VERSION ""

NS_ :

BS_:

BU_: Skylark_EV

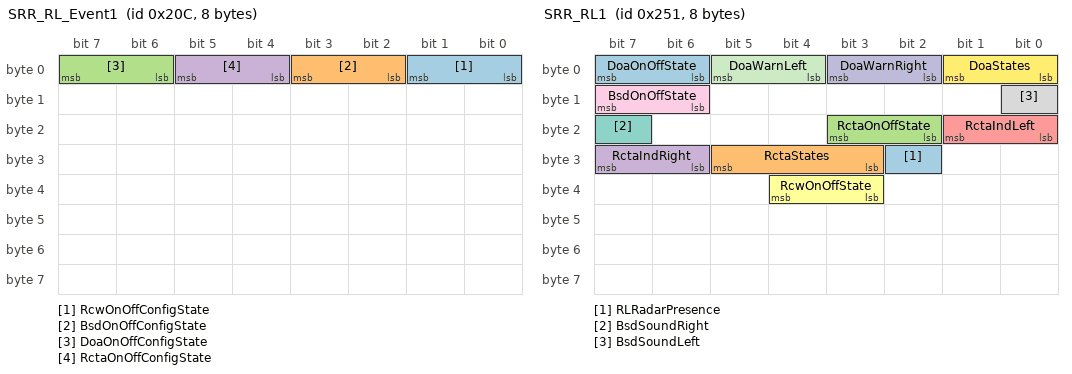
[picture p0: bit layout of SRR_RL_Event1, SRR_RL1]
BO_ 524 SRR_RL_Event1: 8 Vector__XXX
 SG_ RcwOnOffConfigState : 1|2@0+ (1,0) [0|3] ""  Skylark_EV
 SG_ BsdOnOffConfigState : 3|2@0+ (1,0) [0|3] ""  Skylark_EV
 SG_ DoaOnOffConfigState : 7|2@0+ (1,0) [0|3] ""  Skylark_EV
 SG_ RctaOnOffConfigState : 5|2@0+ (1,0) [0|3] ""  Skylark_EV

BO_ 593 SRR_RL1: 8 Vector__XXX
 SG_ RLRadarPresence : 26|1@0+ (1,0) [0|1] ""  Skylark_EV
 SG_ RctaStates : 29|3@0+ (1,0) [0|7] ""  Skylark_EV
 SG_ RctaOnOffState : 19|2@0+ (1,0) [0|3] ""  Skylark_EV
 SG_ RctaIndRight : 31|2@0+ (1,0) [0|3] ""  Skylark_EV
 SG_ RctaIndLeft : 17|2@0+ (1,0) [0|3] ""  Skylark_EV
 SG_ RcwOnOffState : 36|2@0+ (1,0) [0|3] ""  Skylark_EV
 SG_ BsdSoundRight : 23|1@0+ (1,0) [0|1] ""  Skylark_EV
 SG_ BsdSoundLeft : 8|1@0+ (1,0) [0|1] ""  Skylark_EV
 SG_ BsdOnOffState : 15|2@0+ (1,0) [0|3] ""  Skylark_EV
 SG_ DoaWarnRight : 3|2@0+ (1,0) [0|3] ""  Skylark_EV
 SG_ DoaWarnLeft : 5|2@0+ (1,0) [0|3] ""  Skylark_EV
 SG_ DoaStates : 1|2@0+ (1,0) [0|3] ""  Skylark_EV
 SG_ DoaOnOffState : 7|2@0+ (1,0) [0|3] ""  Skylark_EV

BO_ 468 HU_Event2: 8 Skylark_EV
 SG_ HuBcmOrvmTiltReversePos : 56|1@0+ (1,0) [0|1] "" Vector__XXX
 SG_ PotSwRkeOnOffReq : 58|2@0+ (1,0) [0|3] "" Vector__XXX
 SG_ PotHeightAdjReq : 61|3@0+ (1,0) [0|7] "" Vector__XXX
 SG_ PotGestOnOffReq : 63|2@0+ (1,0) [0|3] "" Vector__XXX
 SG_ PotBuzzOnOffReq : 49|2@0+ (1,0) [0|3] "" Vector__XXX
 SG_ RcwReqType : 51|2@0+ (1,0) [0|3] "" Vector__XXX
 SG_ RcwOnOffStateReq : 53|2@0+ (1,0) [0|3] "" Vector__XXX
 SG_ RcwOnOffStateAck : 55|2@0+ (1,0) [0|3] "" Vector__XXX
 SG_ RctaReqType : 41|2@0+ (1,0) [0|3] "" Vector__XXX
 SG_ RctaOnOffStateReq : 43|2@0+ (1,0) [0|3] "" Vector__XXX
 SG_ RctaOnOffStateAck : 45|2@0+ (1,0) [0|3] "" Vector__XXX
 SG_ DoaReqType : 47|2@0+ (1,0) [0|3] "" Vector__XXX
 SG_ DoaOnOffStateReq : 33|2@0+ (1,0) [0|3] "" Vector__XXX
 SG_ DoaOnOffStateAck : 35|2@0+ (1,0) [0|3] "" Vector__XXX
 SG_ BsdReqType : 37|2@0+ (1,0) [0|3] "" Vector__XXX
 SG_ BsdOnOffStateReq : 39|2@0+ (1,0) [0|3] "" Vector__XXX
 SG_ BsdOnOffStateAck : 25|2@0+ (1,0) [0|3] "" Vector__XXX
 SG_ FcwAebWarnSetStateReq : 21|3@0+ (1,0) [0|7] "" Vector__XXX
 SG_ FcwAebWarnSetStateAck : 18|3@0+ (1,0) [0|7] "" Vector__XXX
 SG_ FcwAebReqType : 31|2@0+ (1,0) [0|3] "" Vector__XXX
 SG_ FcwAebOnOffStateReq : 23|2@0+ (1,0) [0|3] "" Vector__XXX
 SG_ FcwAebOnOffStateAck : 29|2@0+ (1,0) [0|3] "" Vector__XXX
 SG_ TsrReqType : 13|2@0+ (1,0) [0|3] "" Vector__XXX
 SG_ TsrOnOffStateReq : 9|2@0+ (1,0) [0|3] "" Vector__XXX
 SG_ TsrOnOffStateAck : 11|2@0+ (1,0) [0|3] "" Vector__XXX
 SG_ LdwOnOffStateReq : 15|2@0+ (1,0) [0|3] "" Vector__XXX
 SG_ LdwReqType : 27|2@0+ (1,0) [0|3] "" Vector__XXX
 SG_ LdwOnOffStateAck : 7|2@0+ (1,0) [0|3] "" Vector__XXX
 SG_ HbaOnOffStateReq : 5|2@0+ (1,0) [0|3] "" Vector__XXX
 SG_ HbaReqType : 3|2@0+ (1,0) [0|3] "" Vector__XXX
 SG_ HbaOnOffStateAck : 1|2@0+ (1,0) [0|3] "" Vector__XXX

BO_ 471 FCM_Event1: 8 Vector__XXX
 SG_ LdwWarningSettingConfigState : 46|2@0+ (1,0) [0|3] ""  Skylark_EV
 SG_ LdwHapticWarningConfigState : 33|3@0+ (1,0) [0|7] ""  Skylark_EV
 SG_ LcsSignalApplicability : 24|1@0+ (1,0) [0|1] ""  Skylark_EV
 SG_ LcsOnOffConfigState : 17|2@0+ (1,0) [0|3] ""  Skylark_EV
 SG_ AsaSignalApplicability : 31|1@0+ (1,0) [0|1] ""  Skylark_EV
 SG_ AsaOnOffConfigState : 35|2@0+ (1,0) [0|3] ""  Skylark_EV
 SG_ OvrSpdLmtThrshldConfigState : 28|2@0+ (1,0) [0|3] "kmph"  Skylark_EV
 SG_ OvrSpdLmtWarnConfigState : 30|2@0+ (1,0) [0|3] ""  Skylark_EV
 SG_ IsaOnOffConfigState : 37|2@0+ (1,0) [0|3] ""  Skylark_EV
 SG_ TsrSignalApplicability : 23|1@0+ (1,0) [0|1] ""  Skylark_EV
 SG_ FcwAebSignalApplicability : 15|1@0+ (1,0) [0|1] ""  Skylark_EV
 SG_ LdwSignalApplicability : 14|1@0+ (1,0) [0|1] ""  Skylark_EV
 SG_ HbaSignalApplicability : 13|1@0+ (1,0) [0|1] ""  Skylark_EV
 SG_ FcwAebOnOffConfigStateValidity : 12|1@0+ (1,0) [0|1] ""  Skylark_EV
 SG_ FcwAebWarnSetConfigStateValidity : 11|1@0+ (1,0) [0|1] ""  Skylark_EV
 SG_ FcwAebWarnSetConfigState : 10|3@0+ (1,0) [0|7] ""  Skylark_EV
 SG_ TsrOnOffConfigState : 7|2@0+ (1,0) [0|3] ""  Skylark_EV
 SG_ LdwOnOffConfigState : 5|2@0+ (1,0) [0|3] ""  Skylark_EV
 SG_ HbaOnOffConfigState : 3|2@0+ (1,0) [0|3] ""  Skylark_EV
 SG_ FcwAebOnOffConfigState : 1|2@0+ (1,0) [0|3] ""  Skylark_EV

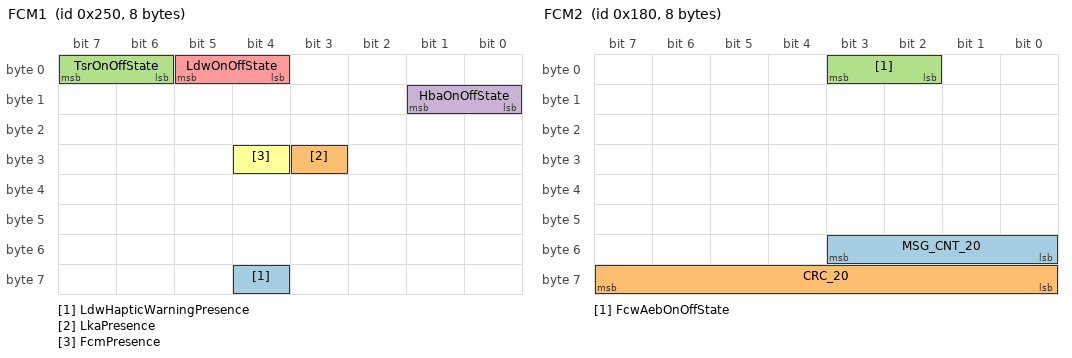
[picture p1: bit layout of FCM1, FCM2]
BO_ 592 FCM1: 8 Vector__XXX
 SG_ LdwHapticWarningPresence : 60|1@0+ (1,0) [0|1] ""  Skylark_EV
 SG_ LkaPresence : 27|1@0+ (1,0) [0|1] ""  Skylark_EV
 SG_ TsrOnOffState : 7|2@0+ (1,0) [0|3] ""  Skylark_EV
 SG_ HbaOnOffState : 9|2@0+ (1,0) [0|3] ""  Skylark_EV
 SG_ LdwOnOffState : 5|2@0+ (1,0) [0|3] ""  Skylark_EV
 SG_ FcmPresence : 28|1@0+ (1,0) [0|1] ""  Skylark_EV

BO_ 384 FCM2: 8 Vector__XXX
 SG_ MSG_CNT_20 : 51|4@0+ (1,0) [0|15] ""  Skylark_EV
 SG_ CRC_20 : 63|8@0+ (1,0) [0|255] ""  Skylark_EV
 SG_ FcwAebOnOffState : 3|2@0+ (1,0) [0|3] ""  Skylark_EV

BO_ 473 HU_Event3: 8 Skylark_EV
 SG_ LdwWarningSettingReq : 27|2@0+ (1,0) [0|3] "" Vector__XXX
 SG_ LdwWarningSettingConfigAck : 25|2@0+ (1,0) [0|3] "" Vector__XXX
 SG_ LdwHapticWarningStateReq : 18|3@0+ (1,0) [0|7] "" Vector__XXX
 SG_ LdwHapticWarningConfigAck : 21|3@0+ (1,0) [0|7] "" Vector__XXX
 SG_ LcsOnOffStateReq : 11|2@0+ (1,0) [0|3] "" Vector__XXX
 SG_ LcsOnOffStateAck : 23|2@0+ (1,0) [0|3] "" Vector__XXX
 SG_ LcsReqType : 9|2@0+ (1,0) [0|3] "" Vector__XXX
 SG_ HuPepsMrrProximityUnfoldSelReq : 13|2@0+ (1,0) [0|3] "" Vector__XXX
 SG_ HuVCuReqType : 15|2@0+ (1,0) [0|3] "" Vector__XXX
 SG_ HuVCuChargeLimitValue : 62|7@0+ (1,0) [0|100] "" Vector__XXX
 SG_ HuCplSclTimerSettingUpdate : 49|2@0+ (1,0) [0|3] "" Vector__XXX
 SG_ HuCplSclOnOffSettingUpdate : 63|1@0+ (1,0) [0|1] "" Vector__XXX
 SG_ HuCplReqType : 51|2@0+ (1,0) [0|3] "" Vector__XXX
 SG_ AsaOnOffStateReq : 33|2@0+ (1,0) [0|3] "" Vector__XXX
 SG_ AsaOnOffStateAck : 35|2@0+ (1,0) [0|3] "" Vector__XXX
 SG_ AsaReqType : 37|2@0+ (1,0) [0|3] "" Vector__XXX
 SG_ OvrSpdLmtThrshldStateReq : 41|2@0+ (1,0) [0|3] "kmph" Vector__XXX
 SG_ OvrSpdLmtThrshldStateAck : 47|2@0+ (1,0) [0|3] "kmph" Vector__XXX
 SG_ OvrSpdLmtWarnStateReq : 43|2@0+ (1,0) [0|3] "" Vector__XXX
 SG_ OvrSpdLmtWarnStateAck : 45|2@0+ (1,0) [0|3] "" Vector__XXX
 SG_ IsaOnOffStateReq : 55|2@0+ (1,0) [0|3] "" Vector__XXX
 SG_ IsaOnOffStateAck : 53|2@0+ (1,0) [0|3] "" Vector__XXX
 SG_ HuBCmMrrAutoUnfoldSelReq : 39|2@0+ (1,0) [0|3] "" Vector__XXX
 SG_ IviSwcEvent : 3|4@0+ (1,0) [0|15] "" Vector__XXX

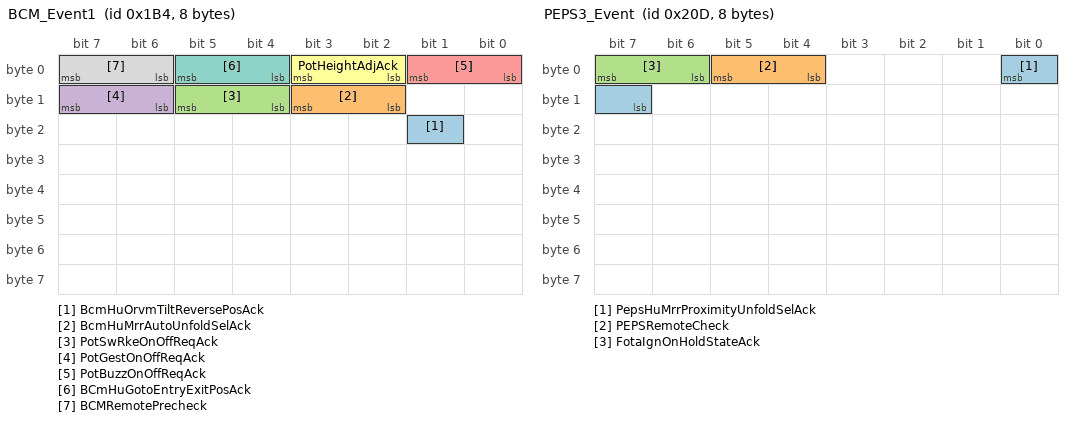
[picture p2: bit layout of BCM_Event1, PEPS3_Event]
BO_ 436 BCM_Event1: 8 Vector__XXX
 SG_ BcmHuOrvmTiltReversePosAck : 17|1@0+ (1,0) [0|1] ""  Skylark_EV
 SG_ BcmHuMrrAutoUnfoldSelAck : 11|2@0+ (1,0) [0|3] ""  Skylark_EV
 SG_ PotSwRkeOnOffReqAck : 13|2@0+ (1,0) [0|3] ""  Skylark_EV
 SG_ PotGestOnOffReqAck : 15|2@0+ (1,0) [0|3] ""  Skylark_EV
 SG_ PotBuzzOnOffReqAck : 1|2@0+ (1,0) [0|3] ""  Skylark_EV
 SG_ PotHeightAdjAck : 3|2@0+ (1,0) [0|3] ""  Skylark_EV
 SG_ BCmHuGotoEntryExitPosAck : 5|2@0+ (1,0) [0|3] ""  Skylark_EV
 SG_ BCMRemotePrecheck : 7|2@0+ (1,0) [0|3] ""  Skylark_EV

BO_ 525 PEPS3_Event: 8 Vector__XXX
 SG_ PepsHuMrrProximityUnfoldSelAck : 0|2@0+ (1,0) [0|3] ""  Skylark_EV
 SG_ PEPSRemoteCheck : 5|2@0+ (1,0) [0|3] ""  Skylark_EV
 SG_ FotaIgnOnHoldStateAck : 7|2@0+ (1,0) [0|3] ""  Skylark_EV

BO_ 496 TelematicsEventMsg1: 8 Skylark_EV
 SG_ FotaIgnOnHoldState : 19|2@0+ (1,0) [0|3] "" Vector__XXX

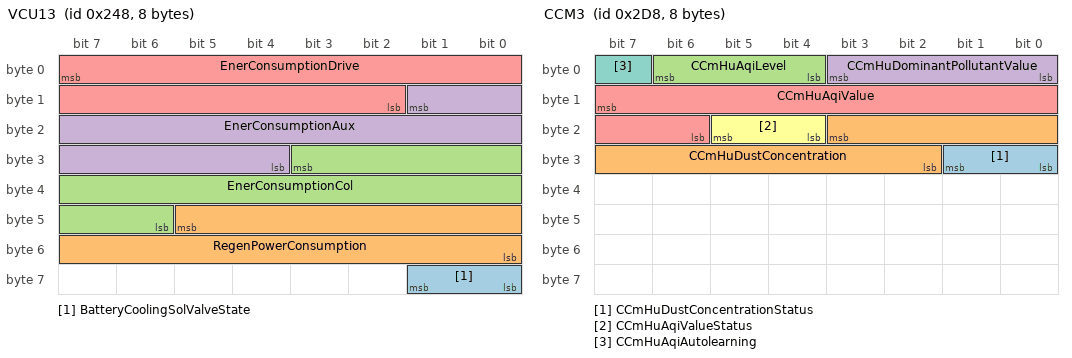
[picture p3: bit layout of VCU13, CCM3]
BO_ 584 VCU13: 8 Vector__XXX
 SG_ BatteryCoolingSolValveState : 57|2@0+ (1,0) [0|3] ""  Skylark_EV
 SG_ RegenPowerConsumption : 45|14@0+ (0.01,0) [0|150] ""  Skylark_EV
 SG_ EnerConsumptionCol : 27|14@0+ (0.01,0) [0|150] ""  Skylark_EV
 SG_ EnerConsumptionAux : 9|14@0+ (0.01,0) [0|150] ""  Skylark_EV
 SG_ EnerConsumptionDrive : 7|14@0+ (0.01,0) [0|150] ""  Skylark_EV

BO_ 728 CCM3: 8 Vector__XXX
 SG_ CCmHuDustConcentrationStatus : 25|2@0+ (1,0) [0|3] ""  Skylark_EV
 SG_ CCmHuDustConcentration : 19|10@0+ (1,0) [0|1023] ""  Skylark_EV
 SG_ CCmHuAqiLevel : 6|3@0+ (1,0) [0|7] ""  Skylark_EV
 SG_ CCmHuDominantPollutantValue : 3|4@0+ (1,0) [0|15] ""  Skylark_EV
 SG_ CCmHuAqiValue : 15|10@0+ (1,0) [0|1023] ""  Skylark_EV
 SG_ CCmHuAqiValueStatus : 21|2@0+ (1,0) [0|3] ""  Skylark_EV
 SG_ CCmHuAqiAutolearning : 7|1@0+ (1,0) [0|1] ""  Skylark_EV

BO_ 736 Remote_Feature1: 8 Vector__XXX
 SG_ VehicleMobilizationStateStatus : 7|2@0+ (1,0) [0|3] ""  Skylark_EV
 SG_ VehicleMobilizationState : 5|2@0+ (1,0) [0|3] ""  Skylark_EV

BO_ 467 HU_Event1: 8 Skylark_EV
 SG_ HuBCmGotoEntryExitPos : 7|2@0+ (1,0) [0|3] "" Vector__XXX

BO_ 583 VCU10_RC: 8 Vector__XXX
 SG_ HvBattDischargingStatus_VCAN : 51|2@0+ (1,0) [0|3] ""  Skylark_EV
 SG_ HvBattDischargingState_VCAN : 23|3@0+ (1,0) [0|7] ""  Skylark_EV
 SG_ HvBattDischargelimitstatus_VCAN : 9|2@0+ (1,0) [0|3] ""  Skylark_EV
 SG_ HvBattDischargelimit_VCAN : 11|2@0+ (1,0) [0|3] ""  Skylark_EV
 SG_ HvBattFullChargeStatus_new_VCAN : 13|2@0+ (1,0) [0|3] ""  Skylark_EV
 SG_ HvBattFullCharge_new_VCAN : 15|2@0+ (1,0) [0|3] ""  Skylark_EV
 SG_ CruiseSwitchStateVCUStatus : 1|2@0+ (1,0) [0|3] ""  Skylark_EV
 SG_ CruiseSwitchStateVCU : 3|2@0+ (1,0) [0|3] ""  Skylark_EV
 SG_ VcuModeSelectionChangeTxt : 53|2@0+ (1,0) [0|3] ""  Skylark_EV
 SG_ ModeForDisplayVCUStatus : 47|2@0+ (1,0) [0|3] ""  Skylark_EV
 SG_ ModeForDisplayVCU : 37|3@0+ (1,0) [0|7] ""  Skylark_EV
 SG_ ModeSelectionSwStateVCUStatus : 16|3@0+ (1,0) [0|7] ""  Skylark_EV
 SG_ ModeSelectionSwStateVCU : 29|3@0+ (1,0) [0|7] ""  Skylark_EV
 SG_ VcuRegenSelectionChangeTxt : 55|2@0+ (1,0) [0|3] ""  Skylark_EV
 SG_ RegenForDisplayVCUStatus : 45|2@0+ (1,0) [0|3] ""  Skylark_EV
 SG_ RegenForDisplayVCU : 34|3@0+ (1,0) [0|7] ""  Skylark_EV
 SG_ VcuCruiseSelectionChangeTxt : 43|4@0+ (1,0) [0|15] ""  Skylark_EV
 SG_ DesiredCruiseSpeedStatus : 49|2@0+ (1,0) [0|3] ""  Skylark_EV
 SG_ DesiredCruiseSpeed : 63|8@0+ (1,0) [0|255] ""  Skylark_EV
 SG_ VCuCruiseStateStatus : 39|2@0+ (1,0) [0|3] ""  Skylark_EV
 SG_ VCuCruiseState : 26|3@0+ (1,0) [0|7] ""  Skylark_EV
 SG_ HvBattFullChargeStatus_VCAN : 7|2@0+ (1,0) [0|3] ""  Skylark_EV
 SG_ HvBattFullCharge_VCAN : 5|1@0+ (1,0) [0|1] ""  Skylark_EV

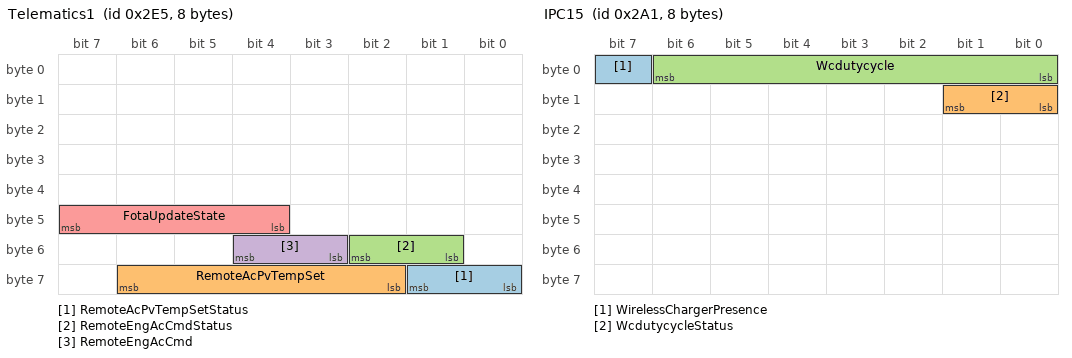
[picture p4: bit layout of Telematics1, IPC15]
BO_ 741 Telematics1: 8 Skylark_EV
 SG_ RemoteAcPvTempSetStatus : 57|2@0+ (1,0) [0|3] "" Vector__XXX
 SG_ RemoteAcPvTempSet : 62|5@0+ (1,0) [0|31] "" Vector__XXX
 SG_ RemoteEngAcCmdStatus : 50|2@0+ (1,0) [0|3] "" Vector__XXX
 SG_ RemoteEngAcCmd : 52|2@0+ (1,0) [0|3] "" Vector__XXX
 SG_ FotaUpdateState : 47|4@0+ (1,0) [0|15] "" Vector__XXX

BO_ 673 IPC15: 8 Vector__XXX
 SG_ WirelessChargerPresence : 7|1@0+ (1,0) [0|1] ""  Skylark_EV
 SG_ WcdutycycleStatus : 9|2@0+ (1,0) [0|3] ""  Skylark_EV
 SG_ Wcdutycycle : 6|7@0+ (1,0) [0|100] "%"  Skylark_EV

BO_ 491 HU_VrCmd_SupportAck: 8 Skylark_EV
 SG_ HuBCmWindowWindingHmiCmdSupportA : 23|1@0+ (1,0) [0|1] "" Vector__XXX
 SG_ HuBCmTyreTempVrCmdSupportAck : 8|1@0+ (1,0) [0|1] "" Vector__XXX
 SG_ HuBCmTyreTempHmiCmdSupportAck : 9|1@0+ (1,0) [0|1] "" Vector__XXX
 SG_ HuBCmTyrePressureVrCmdSupportAck : 10|1@0+ (1,0) [0|1] "" Vector__XXX
 SG_ HuBCmTyrePressureHmiCmdSupportAc : 11|1@0+ (1,0) [0|1] "" Vector__XXX
 SG_ HuBCmSunroofTiltVrCmdSupportAck : 12|1@0+ (1,0) [0|1] "" Vector__XXX
 SG_ HuBCmRoofLampVrCmdSupportAck : 13|1@0+ (1,0) [0|1] "" Vector__XXX
 SG_ HuBCmRoofLampHmiCmdSupportAck : 14|1@0+ (1,0) [0|1] "" Vector__XXX
 SG_ HuBCmPositionLampVrCmdSupportAck : 15|1@0+ (1,0) [0|1] "" Vector__XXX
 SG_ HuBCmORVMVrCmdSupportAck : 2|1@0+ (1,0) [0|1] "" Vector__XXX
 SG_ HuBCmORVMHmiCmdSupportAck : 3|1@0+ (1,0) [0|1] "" Vector__XXX
 SG_ HuBCmMoodLightVrCmdSupportAck : 4|1@0+ (1,0) [0|1] "" Vector__XXX
 SG_ HuBCmHazardLampVrCmdSupportAck : 5|1@0+ (1,0) [0|1] "" Vector__XXX
 SG_ HuBCmDRLVrCmdSupportAck : 6|1@0+ (1,0) [0|1] "" Vector__XXX
 SG_ HuBCmAmbientLightVrCmdSupportAck : 7|1@0+ (1,0) [0|1] "" Vector__XXX
 SG_ HuBCmSunShadeVrCmdSupportAck : 1|1@0+ (1,0) [0|1] "" Vector__XXX
 SG_ HuBCmSunRoofVrCmdSupportAck : 0|1@0+ (1,0) [0|1] "" Vector__XXX

CM_ SG_ 524 RcwOnOffConfigState "It indicates the RCW  feature's On/Off State";
CM_ SG_ 524 BsdOnOffConfigState "It indicates the BSD feature's On/Off State";
CM_ SG_ 524 DoaOnOffConfigState "It indicates the DOA feature's On/Off State";
CM_ SG_ 524 RctaOnOffConfigState "It indicates the RCTA feature's On/Off State";
CM_ SG_ 593 RLRadarPresence "This signal indicates the presence of Rear Radar Module";
CM_ SG_ 593 RctaStates "This signal indicates the states of RCTA";
CM_ SG_ 593 RctaOnOffState "This signal indicates the presence of RCTA feature";
CM_ SG_ 593 RctaIndRight "This signal Indicates RCTA Warning Indicator mode for Right side.";
CM_ SG_ 593 RctaIndLeft "This signal Indicates RCTA Warning Indicator mode for Left side.";
CM_ SG_ 593 RcwOnOffState "This signal indicates the presence of RCW feature";
CM_ SG_ 593 BsdSoundRight "BSD-LCA Sound warning Right speaker";
CM_ SG_ 593 BsdSoundLeft "BSD-LCA Sound warning Left speaker";
CM_ SG_ 593 BsdOnOffState "This signal indicates the presence of BSD feature";
CM_ SG_ 593 DoaWarnRight "DOA Left indicator warning";
CM_ SG_ 593 DoaWarnLeft "DOA Left indicator warning";
CM_ SG_ 593 DoaStates "This signal indicates the states of DOA";
CM_ SG_ 593 DoaOnOffState "This signal indicates the presence of DOA feature";
CM_ SG_ 468 HuBcmOrvmTiltReversePos "ORVM Tilt in reverse Function User request to Enable or Disable Feature";
CM_ SG_ 468 PotSwRkeOnOffReq "POT open/close by RKE switch enable/ disable user req";
CM_ SG_ 468 PotHeightAdjReq "POT height selection by user through HU";
CM_ SG_ 468 PotGestOnOffReq "POT open/close by gesture enable/ disable user req";
CM_ SG_ 468 PotBuzzOnOffReq "POT buzzer of open/close action enable/ disable user req";
CM_ SG_ 468 RcwReqType "This signal indicates the request for an action that IVI wants RearRadar to perform for RCW feature";
CM_ SG_ 468 RcwOnOffStateReq "It indicates the request made by the user for feature enable/disable";
CM_ SG_ 468 RcwOnOffStateAck "It indicates the acknowledgment status from IVI";
CM_ SG_ 468 RctaReqType "This signal indicates the request for an action that IVI wants RLRadar to perform for RCTA feature";
CM_ SG_ 468 RctaOnOffStateReq "It indicates the request made by the user for feature enable/disable";
CM_ SG_ 468 RctaOnOffStateAck "It indicates the acknowledgment status from IVI";
CM_ SG_ 468 DoaReqType "This signal indicates the request for an action that IVI wants RLRadar to perform for DOA feature";
CM_ SG_ 468 DoaOnOffStateReq "It indicates the request made by the user for feature enable/disable";
CM_ SG_ 468 DoaOnOffStateAck "It indicates the acknowledgment status from IVI";
CM_ SG_ 468 BsdReqType "This signal indicates the request for an action that IVI wants RearRadar to perform for BSD feature";
CM_ SG_ 468 BsdOnOffStateReq "It indicates the request made by the user for feature enable/disable";
CM_ SG_ 468 BsdOnOffStateAck "It indicates the acknowledgment status from IVI";
CM_ SG_ 468 FcwAebWarnSetStateReq "It indicates the request made by the user for feature sensitivity

";
CM_ SG_ 468 FcwAebWarnSetStateAck "It indicates the acknowledgment status from IVI for feature sensitivity
";
CM_ SG_ 468 FcwAebReqType "This signal indicates the request for an action that IVI wants FCM to perform for FCW AEB feature

";
CM_ SG_ 468 FcwAebOnOffStateReq "It indicates the request made by the user for feature enable/disable

";
CM_ SG_ 468 FcwAebOnOffStateAck "It indicates the acknowledgment status from IVI for feature ON/OFF
";
CM_ SG_ 468 TsrReqType "This signal indicates the request for an action that IVI wants FCM to perform for TSR feature

";
CM_ SG_ 468 TsrOnOffStateReq "It indicates the request made by the user for feature enable/disable

";
CM_ SG_ 468 TsrOnOffStateAck "It indicates the acknowledgment status from IVI

";
CM_ SG_ 468 LdwOnOffStateReq "It indicates the request made by the user for feature enable/disable

";
CM_ SG_ 468 LdwReqType "This signal indicates the request for an action that IVI wants FCM to perform for LDW feature
";
CM_ SG_ 468 LdwOnOffStateAck "It indicates the acknowledgment status from IVI
";
CM_ SG_ 468 HbaOnOffStateReq "It indicates the request made by the user for feature enable/disable
";
CM_ SG_ 468 HbaReqType "This signal indicates the request for an action that IVI wants FCM to perform for HBA feature";
CM_ SG_ 468 HbaOnOffStateAck "It indicates the acknowledgment status from IVI
";
CM_ SG_ 471 LdwWarningSettingConfigState "This signal  indicates the LDW warning setting





";
CM_ SG_ 471 LdwHapticWarningConfigState "This signal  indicates the LDW Haptic warning setting






";
CM_ SG_ 471 LcsSignalApplicability "This signal describes the applicability of LCS Event signals



";
CM_ SG_ 471 LcsOnOffConfigState "It indicates the LCS feature's On/Off State





";
CM_ SG_ 471 AsaSignalApplicability "It indicates the request made by the user for feature enable/disable





";
CM_ SG_ 471 OvrSpdLmtThrshldConfigState "It indicates the Overspeed limit threshold speed value





";
CM_ SG_ 471 OvrSpdLmtWarnConfigState "It indicates the Overspeed limit alert feature ON/OFF state.";
CM_ SG_ 471 IsaOnOffConfigState "It indicates the ISA feature's ON/OFF state





";
CM_ SG_ 471 TsrSignalApplicability "This signal describes the applicability of TSR Event signals";
CM_ SG_ 471 FcwAebSignalApplicability "This signal describes the applicability of FCW-AEB Event signals";
CM_ SG_ 471 LdwSignalApplicability "This signal describes the applicability of LDW Event signals";
CM_ SG_ 471 HbaSignalApplicability "This signal describes the applicability of HBA Event signals";
CM_ SG_ 471 FcwAebOnOffConfigStateValidity "It indicates the status of AEB feature's On/Off State signal";
CM_ SG_ 471 FcwAebWarnSetConfigStateValidity "It indicates the status of the sensitivity settings signal";
CM_ SG_ 471 FcwAebWarnSetConfigState "It indicates the sensitivity settings selected by the user";
CM_ SG_ 471 TsrOnOffConfigState "It indicates the TSR feature's On/Off State";
CM_ SG_ 471 LdwOnOffConfigState "It indicates the LDW feature's On/Off State";
CM_ SG_ 471 HbaOnOffConfigState "It indicates the HBA feature's On/Off State";
CM_ SG_ 471 FcwAebOnOffConfigState "It indicates the AEB feature's On/Off State";
CM_ SG_ 592 LdwHapticWarningPresence "This signal indicates the presence of Haptic warning setting menu



";
CM_ SG_ 592 LkaPresence "This signal indicates the presence of Lane Keep Assist Feature";
CM_ SG_ 592 TsrOnOffState "It indicates the TSR feature's On/Off State";
CM_ SG_ 592 HbaOnOffState "It indicates the HBA feature's On/Off State";
CM_ SG_ 592 LdwOnOffState "It indicates the LDW feature's On/Off State";
CM_ SG_ 592 FcmPresence "This signal indicates the presence of Front Camera Module";
CM_ SG_ 384 MSG_CNT_20 "Message counter for AEB feature";
CM_ SG_ 384 CRC_20 "CRC signal for AEB feature";
CM_ SG_ 384 FcwAebOnOffState "It indicates the AEB feature's On/Off State";
CM_ SG_ 473 LdwWarningSettingReq "It indicates the request made by the user for LDW warning setting change





";
CM_ SG_ 473 LdwWarningSettingConfigAck "It indicates the acknowledgment status from IVI for LDW warning setting





";
CM_ SG_ 473 LdwHapticWarningStateReq "It indicates the request made by the user for LDW Haptic warning setting change






";
CM_ SG_ 473 LdwHapticWarningConfigAck "It indicates the acknowledgment status from IVI for LDW Haptic warning setting






";
CM_ SG_ 473 LcsOnOffStateReq "It indicates the request made by the user for feature enable/disable





";
CM_ SG_ 473 LcsOnOffStateAck "It indicates the acknowledgment status from IVI





";
CM_ SG_ 473 LcsReqType "This signal indicates the request for an action that IVI wants FCM to perform for LCS feature





";
CM_ SG_ 473 HuPepsMrrProximityUnfoldSelReq "ORVM Proximity Fold / Unfold function enable/ disable user req HU to Peps";
CM_ SG_ 473 HuVCuChargeLimitValue "HuVCuChargeLimitValue";
CM_ SG_ 473 HuCplSclTimerSettingUpdate "This signal indicates timer setting update information for SCL feature.";
CM_ SG_ 473 HuCplSclOnOffSettingUpdate "This signal indicates On/Off setting update information for SCL feature.";
CM_ SG_ 473 HuCplReqType "This signal indicates the intent of event signal send by HU.";
CM_ SG_ 473 AsaOnOffStateReq "It indicates the request made by the user for feature enable/disable





";
CM_ SG_ 473 AsaOnOffStateAck "It indicates the acknowledgment status from IVI





";
CM_ SG_ 473 AsaReqType "This signal indicates the request for an action that IVI wants FCM to perform for ASA feature";
CM_ SG_ 473 OvrSpdLmtThrshldStateReq "It indicates the request made by the user





";
CM_ SG_ 473 OvrSpdLmtThrshldStateAck "It indicates the acknowledgment status from IVI for Overspeed limit threshold speed value





";
CM_ SG_ 473 OvrSpdLmtWarnStateReq "It indicates the request made by the user
";
CM_ SG_ 473 OvrSpdLmtWarnStateAck "It indicates the acknowledgment status from IVI for Overspeed limit alert feature ON/OFF state





";
CM_ SG_ 473 IsaOnOffStateReq "It indicates the request made by the user for feature enable/disable





";
CM_ SG_ 473 IsaOnOffStateAck "It indicates the acknowledgment status from IVI for feature ON/OFF





";
CM_ SG_ 473 HuBCmMrrAutoUnfoldSelReq "ORVM Auto Unfold function enable/ disable user req";
CM_ SG_ 473 IviSwcEvent "LinSwcIc shall publish its variant type to all partner ECUs.";
CM_ SG_ 436 BcmHuOrvmTiltReversePosAck "BCM Ack for ORVM Tilt in Reverse Enable or Disable from HU";
CM_ SG_ 436 BcmHuMrrAutoUnfoldSelAck "ORVM Auto Unfold function user selection acknowledgment from BCM to HU";
CM_ SG_ 436 PotSwRkeOnOffReqAck "ACK BCM to HU for POT open/close by RKE switch enable/ disable user req";
CM_ SG_ 436 PotGestOnOffReqAck "ACK BCM to HU for POT open/close by gesture enable/ disable user req";
CM_ SG_ 436 PotBuzzOnOffReqAck "ACK BCM to HU for POT buzzer of open/close action enable/ disable user req";
CM_ SG_ 436 PotHeightAdjAck "BCM Ack for POT height adj from HU";
CM_ SG_ 436 BCmHuGotoEntryExitPosAck "BCM Ack for Easy Entry/Exit Enable or Disable from HU";
CM_ SG_ 436 BCMRemotePrecheck "BCM shall publish the  door status to TCM & PEPS";
CM_ SG_ 525 PepsHuMrrProximityUnfoldSelAck "ORVM Proximity Fold / Unfold function user selection acknowledgment from Peps to HU";
CM_ SG_ 525 PEPSRemoteCheck "PEPS shall publish  precheck status to TCM";
CM_ SG_ 525 FotaIgnOnHoldStateAck "Acknowledgement Signal from PEPS to TCM for confirming the reception of  the FotaIgnOnHoldState signal  ";
CM_ SG_ 496 FotaIgnOnHoldState "Signal  from TCM to PEPS for requesting to hold Ignition in ON state";
CM_ SG_ 584 BatteryCoolingSolValveState "Battery Cooling Solenoid Valve Signal";
CM_ SG_ 584 RegenPowerConsumption "Regen Power Consumption";
CM_ SG_ 584 EnerConsumptionCol "Energy Consumption Cooling";
CM_ SG_ 584 EnerConsumptionAux "Energy Consumption Auxilary";
CM_ SG_ 584 EnerConsumptionDrive "Energy Consumption Drive ";
CM_ SG_ 728 CCmHuDustConcentrationStatus "Satus for Dust Concentration.";
CM_ SG_ 728 CCmHuDustConcentration "Dust concentration signal is used to measure the concentration level in ug/m3_ PM2.5 Value";
CM_ SG_ 728 CCmHuAqiLevel "AQI Level – used for color indication w.r.t  AQI_Based on Value AQI value the color codes to be assigned. AQI Value to be mapped with respective colour codes.";
CM_ SG_ 728 CCmHuDominantPollutantValue "This value express the concentration of major pollutant inside the cabin";
CM_ SG_ 728 CCmHuAqiValue "AQI value information";
CM_ SG_ 728 CCmHuAqiValueStatus "Plausibility Satus for CCmHuAQIValue";
CM_ SG_ 728 CCmHuAqiAutolearning "This signal will be used by HU to determine whether said feature is available or not";
CM_ SG_ 736 VehicleMobilizationStateStatus "Status of the VehicleMobilizationState signal";
CM_ SG_ 736 VehicleMobilizationState "Vehicle Mobilization and immobilization  response to prevent vehicle crank";
CM_ SG_ 467 HuBCmGotoEntryExitPos "Easy Entry Exit function User request to Enable or Disable Feature";
CM_ SG_ 583 HvBattDischargingStatus_VCAN "Status of HvDischargingState signal";
CM_ SG_ 583 HvBattDischargingState_VCAN "Discharging state of vehicle as published by VCU";
CM_ SG_ 583 HvBattDischargelimitstatus_VCAN "Status of the HV Battery Discharge Charge alert";
CM_ SG_ 583 HvBattDischargelimit_VCAN "HV Battery Discharge alert";
CM_ SG_ 583 HvBattFullChargeStatus_new_VCAN "Status of the HV Battery Full Charge alert_New";
CM_ SG_ 583 HvBattFullCharge_new_VCAN "HV Battery Full Charge alert_New";
CM_ SG_ 583 CruiseSwitchStateVCUStatus "CruiseSwitchstate Signal status information";
CM_ SG_ 583 CruiseSwitchStateVCU "Resume and Set Cruise Switches stateinformation to support HDC function";
CM_ SG_ 583 VcuModeSelectionChangeTxt "Signal on CAN to IPC for possibility of user requested change status.";
CM_ SG_ 583 ModeForDisplayVCUStatus "Plausibility Status of ModeForDisplayVCU";
CM_ SG_ 583 ModeForDisplayVCU "Mode Selection Switch signal (Validated User request) is published by VCU for response Mode Selection";
CM_ SG_ 583 ModeSelectionSwStateVCUStatus "Plausibility Status of ModeSelectionSwState";
CM_ SG_ 583 ModeSelectionSwStateVCU "Mode Selection Display signal is published by VCU for ESP confirmation of Mode Selection request from user";
CM_ SG_ 583 VcuRegenSelectionChangeTxt "This function indicates Regen Level Selection Cluster Indication";
CM_ SG_ 583 RegenForDisplayVCUStatus "Plausibility Status of Regen Level Display on cluster";
CM_ SG_ 583 RegenForDisplayVCU "Regen Level Display on cluster";
CM_ SG_ 583 VcuCruiseSelectionChangeTxt "This function indicates Cruise Selection Cluster Indication";
CM_ SG_ 583 DesiredCruiseSpeedStatus "It indicate the cruise info status";
CM_ SG_ 583 DesiredCruiseSpeed "This information is used   to indicate the speed limit values in display";
CM_ SG_ 583 VCuCruiseStateStatus "status information to CruiseState";
CM_ SG_ 583 VCuCruiseState "Cruise control active / Cruise control failed";
CM_ SG_ 583 HvBattFullChargeStatus_VCAN "Status of the HV Battery Full Charge alert";
CM_ SG_ 583 HvBattFullCharge_VCAN "HV Battery Full Charge alert";
CM_ SG_ 741 RemoteAcPvTempSetStatus "Status of the RemoteAcPvTempSet signal as published by TCU.";
CM_ SG_ 741 RemoteAcPvTempSet "Set temperature value from TCU to FATC for in-cabin climate control.";
CM_ SG_ 741 RemoteEngAcCmdStatus "This signal gives status of RemoteEngAcCmdStatus signal.";
CM_ SG_ 741 RemoteEngAcCmd "After waking up ESCL by PEPS, TCM should send RemoteEngAcCmd on CAN (Cyclic) to BCM, PEPS, IPC, & FATC.";
CM_ SG_ 741 FotaUpdateState "This signal shall be published by TCU to indicate the current state of the FOTA installation to the corresponding ECUs in the vehicle network";
CM_ SG_ 673 WirelessChargerPresence "This signal is transmitted to HU to know wireless charger is presence in vehicle or not.";
CM_ SG_ 673 WcdutycycleStatus "This information is used to determine status of duty cycle of PWM sent by wireless charger";
CM_ SG_ 673 Wcdutycycle "This information is used to determine the duty cycle of PWM sent by wireless charger";
CM_ SG_ 491 HuBCmWindowWindingHmiCmdSupportA "Window Winding HMI support response from HU to BCM";
CM_ SG_ 491 HuBCmTyreTempVrCmdSupportAck "Tyre Temparature Voice support response from HU to BCM";
CM_ SG_ 491 HuBCmTyreTempHmiCmdSupportAck "Tyre Temparature HMI support response from HU to BCM";
CM_ SG_ 491 HuBCmTyrePressureVrCmdSupportAck "Tyre Pressure Voice support response from HU to BCM";
CM_ SG_ 491 HuBCmTyrePressureHmiCmdSupportAc "Tyre Pressure HMI support response from HU to BCM";
CM_ SG_ 491 HuBCmSunroofTiltVrCmdSupportAck "Sunroof Tilt voice support response from HU to BCM";
CM_ SG_ 491 HuBCmRoofLampVrCmdSupportAck "Roof Lamp Voice support response from HU to BCM";
CM_ SG_ 491 HuBCmRoofLampHmiCmdSupportAck "Roof Lamp HMI support response from HU to BCM";
CM_ SG_ 491 HuBCmPositionLampVrCmdSupportAck "Position lamp voice support response from HU to BCM";
CM_ SG_ 491 HuBCmORVMVrCmdSupportAck "ORVM voice support response from HU to BCM";
CM_ SG_ 491 HuBCmORVMHmiCmdSupportAck "ORVM HMI support response from HU to BCM";
CM_ SG_ 491 HuBCmMoodLightVrCmdSupportAck "Mood Light voice support response from HU to BCM";
CM_ SG_ 491 HuBCmHazardLampVrCmdSupportAck "Hazard Lamp voice support response from HU to BCM";
CM_ SG_ 491 HuBCmDRLVrCmdSupportAck "DRL voice support response from HU to BCM";
CM_ SG_ 491 HuBCmAmbientLightVrCmdSupportAck "Ambient Light voice support response from HU to BCM";
CM_ SG_ 491 HuBCmSunShadeVrCmdSupportAck "Sunshade operation support from HU to BCM";
CM_ SG_ 491 HuBCmSunRoofVrCmdSupportAck "Sunroof operation support from HU to BCM";
BA_DEF_ SG_  "Remarks" STRING ;
BA_DEF_ SG_  "NWM_WakeupAllowed" ENUM  "No","Yes";
BA_DEF_ SG_  "GenSigTimeoutTime_HU_Mid_X451" INT 0 65535;
BA_DEF_ SG_  "GenSigTimeoutTime_HU_High_X451" INT 0 65535;
BA_DEF_ SG_  "GenSigTimeoutTime_HU_B" INT 0 65535;
BA_DEF_ SG_  "GenSigTimeoutTime_HU_A" INT 0 65535;
BA_DEF_ SG_  "GenSigTimeoutTime_BCM_Mid" INT 0 65535;
BA_DEF_ SG_  "GenSigTimeoutMsg_HU_Mid_X451" INT 0 65535;
BA_DEF_ SG_  "GenSigTimeoutMsg_HU_High_X451" INT 0 65535;
BA_DEF_ SG_  "GenSigTimeoutMsg_HU_B" INT 0 65535;
BA_DEF_ SG_  "GenSigTimeoutMsg_HU_A" INT 0 65535;
BA_DEF_ SG_  "GenSigStartValue" INT 0 0;
BA_DEF_ SG_  "GenSigSendType" ENUM  "Cyclic","OnWrite","OnWriteWithRepetition","OnChange","OnChangeWithRepetition","IfActive","IfActiveWithRepetition","NoSigSendType","NotUsed","NotUsed","NotUsed","NotUsed","NotUsed";
BA_DEF_ SG_  "GenSigInactiveValue" INT 0 0;
BA_DEF_ SG_  "GenSigEnvVarType" ENUM  "int","float","undef";
BA_DEF_ SG_  "GenSigCycleTimeActive" INT 0 0;
BA_DEF_ SG_  "GenSigCycleTime" INT 0 0;
BA_DEF_ SG_  "GenSigTimeoutMsg_HU_High_X445" INT 0 65535;
BA_DEF_ SG_  "GenSigTimeoutMsg_HU_Mid_X445" INT 0 65535;
BA_DEF_ SG_  "GenSigTimeoutTime_HU_High_X445" INT 0 65535;
BA_DEF_ SG_  "GenSigTimeoutTime_HU_Mid_X445" INT 0 65535;
BA_DEF_ SG_  "GenSigTimeoutMsg_IVI" INT 0 65535;
BA_DEF_ SG_  "GenSigTimeoutTime_IVI" INT 0 65535;
BA_DEF_ BO_  "NmMessage" ENUM  "no","yes";
BA_DEF_ BO_  "NmAsrMessage" ENUM  "<n.a.>","No","Yes";
BA_DEF_ BO_  "MessageTimeout" INT 0 65535;
BA_DEF_ BO_  "GenMsgStartDelayTime" INT 0 0;
BA_DEF_ BO_  "GenMsgSendType" ENUM  "Cyclic","NotUsed","NotUsed","NotUsed","NotUsed","NotUsed","NotUsed","IfActive","NoMsgSendType","NotUsed";
BA_DEF_ BO_  "GenMsgNrOfRepetition" INT 0 0;
BA_DEF_ BO_  "GenMsgILSupport" ENUM  "No","Yes";
BA_DEF_ BO_  "GenMsgDelayTime" INT 0 0;
BA_DEF_ BO_  "GenMsgCycleTimeFast" INT 0 0;
BA_DEF_ BO_  "GenMsgCycleTime" INT 0 0;
BA_DEF_ BO_  "DiagUudtResponse" ENUM  "false","true";
BA_DEF_ BO_  "DiagUsdtResponse" ENUM  "false","true";
BA_DEF_ BO_  "DiagState" ENUM  "No","Yes";
BA_DEF_ BO_  "DiagResponse" ENUM  "No","Yes";
BA_DEF_ BO_  "DiagRequest" ENUM  "No","Yes";
BA_DEF_ BO_  "MsgType" ENUM  "Application","NM","NMH";
BA_DEF_ SG_  "SystemSignalLongSymbol" STRING ;
BA_DEF_DEF_  "Remarks" "null";
BA_DEF_DEF_  "NWM_WakeupAllowed" "No";
BA_DEF_DEF_  "GenSigTimeoutTime_HU_Mid_X451" 500;
BA_DEF_DEF_  "GenSigTimeoutTime_HU_High_X451" 500;
BA_DEF_DEF_  "GenSigTimeoutTime_HU_B" 500;
BA_DEF_DEF_  "GenSigTimeoutTime_HU_A" 500;
BA_DEF_DEF_  "GenSigTimeoutTime_BCM_Mid" 0;
BA_DEF_DEF_  "GenSigTimeoutMsg_HU_Mid_X451" 500;
BA_DEF_DEF_  "GenSigTimeoutMsg_HU_High_X451" 500;
BA_DEF_DEF_  "GenSigTimeoutMsg_HU_B" 500;
BA_DEF_DEF_  "GenSigTimeoutMsg_HU_A" 500;
BA_DEF_DEF_  "GenSigStartValue" 0;
BA_DEF_DEF_  "GenSigSendType" "Cyclic";
BA_DEF_DEF_  "GenSigInactiveValue" 0;
BA_DEF_DEF_  "GenSigEnvVarType" "undef";
BA_DEF_DEF_  "GenSigCycleTimeActive" 0;
BA_DEF_DEF_  "GenSigCycleTime" 0;
BA_DEF_DEF_  "GenSigTimeoutMsg_HU_High_X445" 500;
BA_DEF_DEF_  "GenSigTimeoutMsg_HU_Mid_X445" 500;
BA_DEF_DEF_  "GenSigTimeoutTime_HU_High_X445" 500;
BA_DEF_DEF_  "GenSigTimeoutTime_HU_Mid_X445" 500;
BA_DEF_DEF_  "GenSigTimeoutMsg_IVI" 500;
BA_DEF_DEF_  "GenSigTimeoutTime_IVI" 500;
BA_DEF_DEF_  "NmMessage" "no";
BA_DEF_DEF_  "NmAsrMessage" "<n.a.>";
BA_DEF_DEF_  "MessageTimeout" 500;
BA_DEF_DEF_  "GenMsgStartDelayTime" 0;
BA_DEF_DEF_  "GenMsgSendType" "Cyclic";
BA_DEF_DEF_  "GenMsgNrOfRepetition" 0;
BA_DEF_DEF_  "GenMsgILSupport" "Yes";
BA_DEF_DEF_  "GenMsgDelayTime" 0;
BA_DEF_DEF_  "GenMsgCycleTimeFast" 0;
BA_DEF_DEF_  "GenMsgCycleTime" 0;
BA_DEF_DEF_  "DiagUudtResponse" "false";
BA_DEF_DEF_  "DiagUsdtResponse" "false";
BA_DEF_DEF_  "DiagState" "No";
BA_DEF_DEF_  "DiagResponse" "No";
BA_DEF_DEF_  "DiagRequest" "No";
BA_DEF_DEF_  "MsgType" "Application";
BA_DEF_DEF_  "SystemSignalLongSymbol" "";
BA_ "MessageTimeout" BO_ 524 0;
BA_ "GenMsgSendType" BO_ 524 8;
BA_ "GenMsgNrOfRepetition" BO_ 524 3;
BA_ "GenMsgCycleTime" BO_ 593 100;
BA_ "MessageTimeout" BO_ 468 0;
BA_ "GenMsgSendType" BO_ 468 8;
BA_ "GenMsgNrOfRepetition" BO_ 468 3;
BA_ "GenMsgDelayTime" BO_ 468 200;
BA_ "GenMsgCycleTimeFast" BO_ 468 200;
BA_ "MessageTimeout" BO_ 471 0;
BA_ "GenMsgSendType" BO_ 471 8;
BA_ "GenMsgNrOfRepetition" BO_ 471 3;
BA_ "GenMsgDelayTime" BO_ 471 40;
BA_ "GenMsgCycleTimeFast" BO_ 471 40;
BA_ "GenMsgCycleTime" BO_ 592 100;
BA_ "GenMsgCycleTime" BO_ 384 20;
BA_ "MessageTimeout" BO_ 473 0;
BA_ "GenMsgSendType" BO_ 473 8;
BA_ "GenMsgNrOfRepetition" BO_ 473 3;
BA_ "GenMsgDelayTime" BO_ 473 200;
BA_ "GenMsgCycleTimeFast" BO_ 473 200;
BA_ "MessageTimeout" BO_ 436 0;
BA_ "GenMsgSendType" BO_ 436 8;
BA_ "GenMsgNrOfRepetition" BO_ 436 3;
BA_ "GenMsgDelayTime" BO_ 436 500;
BA_ "GenMsgCycleTimeFast" BO_ 436 500;
BA_ "MessageTimeout" BO_ 525 0;
BA_ "GenMsgSendType" BO_ 525 8;
BA_ "GenMsgNrOfRepetition" BO_ 525 4;
BA_ "GenMsgCycleTimeFast" BO_ 525 100;
BA_ "MessageTimeout" BO_ 496 0;
BA_ "GenMsgSendType" BO_ 496 8;
BA_ "GenMsgNrOfRepetition" BO_ 496 3;
BA_ "GenMsgDelayTime" BO_ 496 100;
BA_ "GenMsgCycleTimeFast" BO_ 496 100;
BA_ "GenMsgCycleTime" BO_ 584 100;
BA_ "GenMsgCycleTime" BO_ 728 100;
BA_ "GenMsgCycleTime" BO_ 736 100;
BA_ "MessageTimeout" BO_ 467 0;
BA_ "GenMsgSendType" BO_ 467 8;
BA_ "GenMsgNrOfRepetition" BO_ 467 3;
BA_ "GenMsgDelayTime" BO_ 467 200;
BA_ "GenMsgCycleTimeFast" BO_ 467 200;
BA_ "GenMsgCycleTime" BO_ 583 100;
BA_ "GenMsgCycleTime" BO_ 741 100;
BA_ "GenMsgCycleTime" BO_ 673 100;
BA_ "MessageTimeout" BO_ 491 0;
BA_ "GenMsgSendType" BO_ 491 8;
BA_ "GenMsgNrOfRepetition" BO_ 491 3;
BA_ "GenMsgDelayTime" BO_ 491 500;
BA_ "GenMsgCycleTimeFast" BO_ 491 500;
BA_ "GenSigTimeoutTime_HU_Mid_X451" SG_ 524 RcwOnOffConfigState 0;
BA_ "GenSigTimeoutTime_HU_High_X451" SG_ 524 RcwOnOffConfigState 0;
BA_ "GenSigTimeoutTime_HU_B" SG_ 524 RcwOnOffConfigState 0;
BA_ "GenSigTimeoutTime_HU_A" SG_ 524 RcwOnOffConfigState 0;
BA_ "GenSigTimeoutMsg_HU_Mid_X451" SG_ 524 RcwOnOffConfigState 0;
BA_ "GenSigTimeoutMsg_HU_High_X451" SG_ 524 RcwOnOffConfigState 0;
BA_ "GenSigTimeoutMsg_HU_B" SG_ 524 RcwOnOffConfigState 0;
BA_ "GenSigTimeoutMsg_HU_A" SG_ 524 RcwOnOffConfigState 0;
BA_ "GenSigSendType" SG_ 524 RcwOnOffConfigState 1;
BA_ "GenSigTimeoutMsg_HU_High_X445" SG_ 524 RcwOnOffConfigState 0;
BA_ "GenSigTimeoutMsg_HU_Mid_X445" SG_ 524 RcwOnOffConfigState 0;
BA_ "GenSigTimeoutTime_HU_High_X445" SG_ 524 RcwOnOffConfigState 0;
BA_ "GenSigTimeoutTime_HU_Mid_X445" SG_ 524 RcwOnOffConfigState 0;
BA_ "GenSigTimeoutMsg_IVI" SG_ 524 RcwOnOffConfigState 0;
BA_ "GenSigTimeoutTime_IVI" SG_ 524 RcwOnOffConfigState 0;
BA_ "GenSigTimeoutTime_HU_Mid_X451" SG_ 524 BsdOnOffConfigState 0;
BA_ "GenSigTimeoutTime_HU_High_X451" SG_ 524 BsdOnOffConfigState 0;
BA_ "GenSigTimeoutTime_HU_B" SG_ 524 BsdOnOffConfigState 0;
BA_ "GenSigTimeoutTime_HU_A" SG_ 524 BsdOnOffConfigState 0;
BA_ "GenSigTimeoutMsg_HU_Mid_X451" SG_ 524 BsdOnOffConfigState 0;
BA_ "GenSigTimeoutMsg_HU_High_X451" SG_ 524 BsdOnOffConfigState 0;
BA_ "GenSigTimeoutMsg_HU_B" SG_ 524 BsdOnOffConfigState 0;
BA_ "GenSigTimeoutMsg_HU_A" SG_ 524 BsdOnOffConfigState 0;
BA_ "GenSigSendType" SG_ 524 BsdOnOffConfigState 1;
BA_ "GenSigTimeoutMsg_HU_High_X445" SG_ 524 BsdOnOffConfigState 0;
BA_ "GenSigTimeoutMsg_HU_Mid_X445" SG_ 524 BsdOnOffConfigState 0;
BA_ "GenSigTimeoutTime_HU_High_X445" SG_ 524 BsdOnOffConfigState 0;
BA_ "GenSigTimeoutTime_HU_Mid_X445" SG_ 524 BsdOnOffConfigState 0;
BA_ "GenSigTimeoutMsg_IVI" SG_ 524 BsdOnOffConfigState 0;
BA_ "GenSigTimeoutTime_IVI" SG_ 524 BsdOnOffConfigState 0;
BA_ "GenSigTimeoutTime_HU_Mid_X451" SG_ 524 DoaOnOffConfigState 0;
BA_ "GenSigTimeoutTime_HU_High_X451" SG_ 524 DoaOnOffConfigState 0;
BA_ "GenSigTimeoutTime_HU_B" SG_ 524 DoaOnOffConfigState 0;
BA_ "GenSigTimeoutTime_HU_A" SG_ 524 DoaOnOffConfigState 0;
BA_ "GenSigTimeoutMsg_HU_Mid_X451" SG_ 524 DoaOnOffConfigState 0;
BA_ "GenSigTimeoutMsg_HU_High_X451" SG_ 524 DoaOnOffConfigState 0;
BA_ "GenSigTimeoutMsg_HU_B" SG_ 524 DoaOnOffConfigState 0;
BA_ "GenSigTimeoutMsg_HU_A" SG_ 524 DoaOnOffConfigState 0;
BA_ "GenSigSendType" SG_ 524 DoaOnOffConfigState 1;
BA_ "GenSigTimeoutMsg_HU_High_X445" SG_ 524 DoaOnOffConfigState 0;
BA_ "GenSigTimeoutMsg_HU_Mid_X445" SG_ 524 DoaOnOffConfigState 0;
BA_ "GenSigTimeoutTime_HU_High_X445" SG_ 524 DoaOnOffConfigState 0;
BA_ "GenSigTimeoutTime_HU_Mid_X445" SG_ 524 DoaOnOffConfigState 0;
BA_ "GenSigTimeoutMsg_IVI" SG_ 524 DoaOnOffConfigState 0;
BA_ "GenSigTimeoutTime_IVI" SG_ 524 DoaOnOffConfigState 0;
BA_ "GenSigTimeoutTime_HU_Mid_X451" SG_ 524 RctaOnOffConfigState 0;
BA_ "GenSigTimeoutTime_HU_High_X451" SG_ 524 RctaOnOffConfigState 0;
BA_ "GenSigTimeoutTime_HU_B" SG_ 524 RctaOnOffConfigState 0;
BA_ "GenSigTimeoutTime_HU_A" SG_ 524 RctaOnOffConfigState 0;
BA_ "GenSigTimeoutMsg_HU_Mid_X451" SG_ 524 RctaOnOffConfigState 0;
BA_ "GenSigTimeoutMsg_HU_High_X451" SG_ 524 RctaOnOffConfigState 0;
BA_ "GenSigTimeoutMsg_HU_B" SG_ 524 RctaOnOffConfigState 0;
BA_ "GenSigTimeoutMsg_HU_A" SG_ 524 RctaOnOffConfigState 0;
BA_ "GenSigSendType" SG_ 524 RctaOnOffConfigState 1;
BA_ "GenSigTimeoutMsg_HU_High_X445" SG_ 524 RctaOnOffConfigState 0;
BA_ "GenSigTimeoutMsg_HU_Mid_X445" SG_ 524 RctaOnOffConfigState 0;
BA_ "GenSigTimeoutTime_HU_High_X445" SG_ 524 RctaOnOffConfigState 0;
BA_ "GenSigTimeoutTime_HU_Mid_X445" SG_ 524 RctaOnOffConfigState 0;
BA_ "GenSigTimeoutMsg_IVI" SG_ 524 RctaOnOffConfigState 0;
BA_ "GenSigTimeoutTime_IVI" SG_ 524 RctaOnOffConfigState 0;
BA_ "GenSigSendType" SG_ 593 RLRadarPresence 7;
BA_ "GenSigCycleTimeActive" SG_ 593 RLRadarPresence 100;
BA_ "GenSigCycleTime" SG_ 593 RLRadarPresence 100;
BA_ "GenSigSendType" SG_ 593 RctaStates 7;
BA_ "GenSigCycleTimeActive" SG_ 593 RctaStates 100;
BA_ "GenSigCycleTime" SG_ 593 RctaStates 100;
BA_ "GenSigStartValue" SG_ 593 RctaOnOffState 1;
BA_ "GenSigSendType" SG_ 593 RctaOnOffState 7;
BA_ "GenSigCycleTimeActive" SG_ 593 RctaOnOffState 100;
BA_ "GenSigCycleTime" SG_ 593 RctaOnOffState 100;
BA_ "GenSigSendType" SG_ 593 RctaIndRight 7;
BA_ "GenSigCycleTimeActive" SG_ 593 RctaIndRight 100;
BA_ "GenSigCycleTime" SG_ 593 RctaIndRight 100;
BA_ "GenSigSendType" SG_ 593 RctaIndLeft 7;
BA_ "GenSigCycleTimeActive" SG_ 593 RctaIndLeft 100;
BA_ "GenSigCycleTime" SG_ 593 RctaIndLeft 100;
BA_ "GenSigStartValue" SG_ 593 RcwOnOffState 1;
BA_ "GenSigSendType" SG_ 593 RcwOnOffState 7;
BA_ "GenSigCycleTimeActive" SG_ 593 RcwOnOffState 100;
BA_ "GenSigCycleTime" SG_ 593 RcwOnOffState 100;
BA_ "GenSigSendType" SG_ 593 BsdSoundRight 7;
BA_ "GenSigCycleTimeActive" SG_ 593 BsdSoundRight 100;
BA_ "GenSigCycleTime" SG_ 593 BsdSoundRight 100;
BA_ "GenSigSendType" SG_ 593 BsdSoundLeft 7;
BA_ "GenSigCycleTimeActive" SG_ 593 BsdSoundLeft 100;
BA_ "GenSigCycleTime" SG_ 593 BsdSoundLeft 100;
BA_ "GenSigStartValue" SG_ 593 BsdOnOffState 1;
BA_ "GenSigSendType" SG_ 593 BsdOnOffState 7;
BA_ "GenSigCycleTimeActive" SG_ 593 BsdOnOffState 100;
BA_ "GenSigCycleTime" SG_ 593 BsdOnOffState 100;
BA_ "GenSigSendType" SG_ 593 DoaWarnRight 7;
BA_ "GenSigCycleTimeActive" SG_ 593 DoaWarnRight 100;
BA_ "GenSigCycleTime" SG_ 593 DoaWarnRight 100;
BA_ "GenSigSendType" SG_ 593 DoaWarnLeft 7;
BA_ "GenSigCycleTimeActive" SG_ 593 DoaWarnLeft 100;
BA_ "GenSigCycleTime" SG_ 593 DoaWarnLeft 100;
BA_ "GenSigSendType" SG_ 593 DoaStates 7;
BA_ "GenSigCycleTimeActive" SG_ 593 DoaStates 100;
BA_ "GenSigCycleTime" SG_ 593 DoaStates 100;
BA_ "GenSigStartValue" SG_ 593 DoaOnOffState 1;
BA_ "GenSigSendType" SG_ 593 DoaOnOffState 7;
BA_ "GenSigCycleTimeActive" SG_ 593 DoaOnOffState 100;
BA_ "GenSigCycleTime" SG_ 593 DoaOnOffState 100;
BA_ "GenSigTimeoutTime_HU_Mid_X451" SG_ 468 HuBcmOrvmTiltReversePos 0;
BA_ "GenSigTimeoutTime_HU_High_X451" SG_ 468 HuBcmOrvmTiltReversePos 0;
BA_ "GenSigTimeoutTime_HU_B" SG_ 468 HuBcmOrvmTiltReversePos 0;
BA_ "GenSigTimeoutTime_HU_A" SG_ 468 HuBcmOrvmTiltReversePos 0;
BA_ "GenSigTimeoutMsg_HU_Mid_X451" SG_ 468 HuBcmOrvmTiltReversePos 0;
BA_ "GenSigTimeoutMsg_HU_High_X451" SG_ 468 HuBcmOrvmTiltReversePos 0;
BA_ "GenSigTimeoutMsg_HU_B" SG_ 468 HuBcmOrvmTiltReversePos 0;
BA_ "GenSigTimeoutMsg_HU_A" SG_ 468 HuBcmOrvmTiltReversePos 0;
BA_ "GenSigSendType" SG_ 468 HuBcmOrvmTiltReversePos 2;
BA_ "GenSigTimeoutMsg_HU_High_X445" SG_ 468 HuBcmOrvmTiltReversePos 0;
BA_ "GenSigTimeoutMsg_HU_Mid_X445" SG_ 468 HuBcmOrvmTiltReversePos 0;
BA_ "GenSigTimeoutTime_HU_High_X445" SG_ 468 HuBcmOrvmTiltReversePos 0;
BA_ "GenSigTimeoutTime_HU_Mid_X445" SG_ 468 HuBcmOrvmTiltReversePos 0;
BA_ "GenSigTimeoutMsg_IVI" SG_ 468 HuBcmOrvmTiltReversePos 0;
BA_ "GenSigTimeoutTime_IVI" SG_ 468 HuBcmOrvmTiltReversePos 0;
BA_ "GenSigTimeoutTime_HU_Mid_X451" SG_ 468 PotSwRkeOnOffReq 0;
BA_ "GenSigTimeoutTime_HU_High_X451" SG_ 468 PotSwRkeOnOffReq 0;
BA_ "GenSigTimeoutTime_HU_B" SG_ 468 PotSwRkeOnOffReq 0;
BA_ "GenSigTimeoutTime_HU_A" SG_ 468 PotSwRkeOnOffReq 0;
BA_ "GenSigTimeoutMsg_HU_Mid_X451" SG_ 468 PotSwRkeOnOffReq 0;
BA_ "GenSigTimeoutMsg_HU_High_X451" SG_ 468 PotSwRkeOnOffReq 0;
BA_ "GenSigTimeoutMsg_HU_B" SG_ 468 PotSwRkeOnOffReq 0;
BA_ "GenSigTimeoutMsg_HU_A" SG_ 468 PotSwRkeOnOffReq 0;
BA_ "GenSigSendType" SG_ 468 PotSwRkeOnOffReq 2;
BA_ "GenSigTimeoutMsg_HU_High_X445" SG_ 468 PotSwRkeOnOffReq 0;
BA_ "GenSigTimeoutMsg_HU_Mid_X445" SG_ 468 PotSwRkeOnOffReq 0;
BA_ "GenSigTimeoutTime_HU_High_X445" SG_ 468 PotSwRkeOnOffReq 0;
BA_ "GenSigTimeoutTime_HU_Mid_X445" SG_ 468 PotSwRkeOnOffReq 0;
BA_ "GenSigTimeoutMsg_IVI" SG_ 468 PotSwRkeOnOffReq 0;
BA_ "GenSigTimeoutTime_IVI" SG_ 468 PotSwRkeOnOffReq 0;
BA_ "GenSigTimeoutTime_HU_Mid_X451" SG_ 468 PotHeightAdjReq 0;
BA_ "GenSigTimeoutTime_HU_High_X451" SG_ 468 PotHeightAdjReq 0;
BA_ "GenSigTimeoutTime_HU_B" SG_ 468 PotHeightAdjReq 0;
BA_ "GenSigTimeoutTime_HU_A" SG_ 468 PotHeightAdjReq 0;
BA_ "GenSigTimeoutMsg_HU_Mid_X451" SG_ 468 PotHeightAdjReq 0;
BA_ "GenSigTimeoutMsg_HU_High_X451" SG_ 468 PotHeightAdjReq 0;
BA_ "GenSigTimeoutMsg_HU_B" SG_ 468 PotHeightAdjReq 0;
BA_ "GenSigTimeoutMsg_HU_A" SG_ 468 PotHeightAdjReq 0;
BA_ "GenSigSendType" SG_ 468 PotHeightAdjReq 2;
BA_ "GenSigTimeoutMsg_HU_High_X445" SG_ 468 PotHeightAdjReq 0;
BA_ "GenSigTimeoutMsg_HU_Mid_X445" SG_ 468 PotHeightAdjReq 0;
BA_ "GenSigTimeoutTime_HU_High_X445" SG_ 468 PotHeightAdjReq 0;
BA_ "GenSigTimeoutTime_HU_Mid_X445" SG_ 468 PotHeightAdjReq 0;
BA_ "GenSigTimeoutMsg_IVI" SG_ 468 PotHeightAdjReq 0;
BA_ "GenSigTimeoutTime_IVI" SG_ 468 PotHeightAdjReq 0;
BA_ "GenSigTimeoutTime_HU_Mid_X451" SG_ 468 PotGestOnOffReq 0;
BA_ "GenSigTimeoutTime_HU_High_X451" SG_ 468 PotGestOnOffReq 0;
BA_ "GenSigTimeoutTime_HU_B" SG_ 468 PotGestOnOffReq 0;
BA_ "GenSigTimeoutTime_HU_A" SG_ 468 PotGestOnOffReq 0;
BA_ "GenSigTimeoutMsg_HU_Mid_X451" SG_ 468 PotGestOnOffReq 0;
BA_ "GenSigTimeoutMsg_HU_High_X451" SG_ 468 PotGestOnOffReq 0;
BA_ "GenSigTimeoutMsg_HU_B" SG_ 468 PotGestOnOffReq 0;
BA_ "GenSigTimeoutMsg_HU_A" SG_ 468 PotGestOnOffReq 0;
BA_ "GenSigSendType" SG_ 468 PotGestOnOffReq 2;
BA_ "GenSigTimeoutMsg_HU_High_X445" SG_ 468 PotGestOnOffReq 0;
BA_ "GenSigTimeoutMsg_HU_Mid_X445" SG_ 468 PotGestOnOffReq 0;
BA_ "GenSigTimeoutTime_HU_High_X445" SG_ 468 PotGestOnOffReq 0;
BA_ "GenSigTimeoutTime_HU_Mid_X445" SG_ 468 PotGestOnOffReq 0;
BA_ "GenSigTimeoutMsg_IVI" SG_ 468 PotGestOnOffReq 0;
BA_ "GenSigTimeoutTime_IVI" SG_ 468 PotGestOnOffReq 0;
BA_ "GenSigTimeoutTime_HU_Mid_X451" SG_ 468 PotBuzzOnOffReq 0;
BA_ "GenSigTimeoutTime_HU_High_X451" SG_ 468 PotBuzzOnOffReq 0;
BA_ "GenSigTimeoutTime_HU_B" SG_ 468 PotBuzzOnOffReq 0;
BA_ "GenSigTimeoutTime_HU_A" SG_ 468 PotBuzzOnOffReq 0;
BA_ "GenSigTimeoutMsg_HU_Mid_X451" SG_ 468 PotBuzzOnOffReq 0;
BA_ "GenSigTimeoutMsg_HU_High_X451" SG_ 468 PotBuzzOnOffReq 0;
BA_ "GenSigTimeoutMsg_HU_B" SG_ 468 PotBuzzOnOffReq 0;
BA_ "GenSigTimeoutMsg_HU_A" SG_ 468 PotBuzzOnOffReq 0;
BA_ "GenSigSendType" SG_ 468 PotBuzzOnOffReq 2;
BA_ "GenSigTimeoutMsg_HU_High_X445" SG_ 468 PotBuzzOnOffReq 0;
BA_ "GenSigTimeoutMsg_HU_Mid_X445" SG_ 468 PotBuzzOnOffReq 0;
BA_ "GenSigTimeoutTime_HU_High_X445" SG_ 468 PotBuzzOnOffReq 0;
BA_ "GenSigTimeoutTime_HU_Mid_X445" SG_ 468 PotBuzzOnOffReq 0;
BA_ "GenSigTimeoutMsg_IVI" SG_ 468 PotBuzzOnOffReq 0;
BA_ "GenSigTimeoutTime_IVI" SG_ 468 PotBuzzOnOffReq 0;
BA_ "GenSigTimeoutTime_HU_Mid_X451" SG_ 468 RcwReqType 0;
BA_ "GenSigTimeoutTime_HU_High_X451" SG_ 468 RcwReqType 0;
BA_ "GenSigTimeoutTime_HU_B" SG_ 468 RcwReqType 0;
BA_ "GenSigTimeoutTime_HU_A" SG_ 468 RcwReqType 0;
BA_ "GenSigTimeoutMsg_HU_Mid_X451" SG_ 468 RcwReqType 0;
BA_ "GenSigTimeoutMsg_HU_High_X451" SG_ 468 RcwReqType 0;
BA_ "GenSigTimeoutMsg_HU_B" SG_ 468 RcwReqType 0;
BA_ "GenSigTimeoutMsg_HU_A" SG_ 468 RcwReqType 0;
BA_ "GenSigSendType" SG_ 468 RcwReqType 2;
BA_ "GenSigTimeoutMsg_HU_High_X445" SG_ 468 RcwReqType 0;
BA_ "GenSigTimeoutMsg_HU_Mid_X445" SG_ 468 RcwReqType 0;
BA_ "GenSigTimeoutTime_HU_High_X445" SG_ 468 RcwReqType 0;
BA_ "GenSigTimeoutTime_HU_Mid_X445" SG_ 468 RcwReqType 0;
BA_ "GenSigTimeoutMsg_IVI" SG_ 468 RcwReqType 0;
BA_ "GenSigTimeoutTime_IVI" SG_ 468 RcwReqType 0;
BA_ "GenSigTimeoutTime_HU_Mid_X451" SG_ 468 RcwOnOffStateReq 0;
BA_ "GenSigTimeoutTime_HU_High_X451" SG_ 468 RcwOnOffStateReq 0;
BA_ "GenSigTimeoutTime_HU_B" SG_ 468 RcwOnOffStateReq 0;
BA_ "GenSigTimeoutTime_HU_A" SG_ 468 RcwOnOffStateReq 0;
BA_ "GenSigTimeoutMsg_HU_Mid_X451" SG_ 468 RcwOnOffStateReq 0;
BA_ "GenSigTimeoutMsg_HU_High_X451" SG_ 468 RcwOnOffStateReq 0;
BA_ "GenSigTimeoutMsg_HU_B" SG_ 468 RcwOnOffStateReq 0;
BA_ "GenSigTimeoutMsg_HU_A" SG_ 468 RcwOnOffStateReq 0;
BA_ "GenSigSendType" SG_ 468 RcwOnOffStateReq 2;
BA_ "GenSigTimeoutMsg_HU_High_X445" SG_ 468 RcwOnOffStateReq 0;
BA_ "GenSigTimeoutMsg_HU_Mid_X445" SG_ 468 RcwOnOffStateReq 0;
BA_ "GenSigTimeoutTime_HU_High_X445" SG_ 468 RcwOnOffStateReq 0;
BA_ "GenSigTimeoutTime_HU_Mid_X445" SG_ 468 RcwOnOffStateReq 0;
BA_ "GenSigTimeoutMsg_IVI" SG_ 468 RcwOnOffStateReq 0;
BA_ "GenSigTimeoutTime_IVI" SG_ 468 RcwOnOffStateReq 0;
BA_ "GenSigTimeoutTime_HU_Mid_X451" SG_ 468 RcwOnOffStateAck 0;
BA_ "GenSigTimeoutTime_HU_High_X451" SG_ 468 RcwOnOffStateAck 0;
BA_ "GenSigTimeoutTime_HU_B" SG_ 468 RcwOnOffStateAck 0;
BA_ "GenSigTimeoutTime_HU_A" SG_ 468 RcwOnOffStateAck 0;
BA_ "GenSigTimeoutMsg_HU_Mid_X451" SG_ 468 RcwOnOffStateAck 0;
BA_ "GenSigTimeoutMsg_HU_High_X451" SG_ 468 RcwOnOffStateAck 0;
BA_ "GenSigTimeoutMsg_HU_B" SG_ 468 RcwOnOffStateAck 0;
BA_ "GenSigTimeoutMsg_HU_A" SG_ 468 RcwOnOffStateAck 0;
BA_ "GenSigSendType" SG_ 468 RcwOnOffStateAck 2;
BA_ "GenSigTimeoutMsg_HU_High_X445" SG_ 468 RcwOnOffStateAck 0;
BA_ "GenSigTimeoutMsg_HU_Mid_X445" SG_ 468 RcwOnOffStateAck 0;
BA_ "GenSigTimeoutTime_HU_High_X445" SG_ 468 RcwOnOffStateAck 0;
BA_ "GenSigTimeoutTime_HU_Mid_X445" SG_ 468 RcwOnOffStateAck 0;
BA_ "GenSigTimeoutMsg_IVI" SG_ 468 RcwOnOffStateAck 0;
BA_ "GenSigTimeoutTime_IVI" SG_ 468 RcwOnOffStateAck 0;
BA_ "GenSigTimeoutTime_HU_Mid_X451" SG_ 468 RctaReqType 0;
BA_ "GenSigTimeoutTime_HU_High_X451" SG_ 468 RctaReqType 0;
BA_ "GenSigTimeoutTime_HU_B" SG_ 468 RctaReqType 0;
BA_ "GenSigTimeoutTime_HU_A" SG_ 468 RctaReqType 0;
BA_ "GenSigTimeoutMsg_HU_Mid_X451" SG_ 468 RctaReqType 0;
BA_ "GenSigTimeoutMsg_HU_High_X451" SG_ 468 RctaReqType 0;
BA_ "GenSigTimeoutMsg_HU_B" SG_ 468 RctaReqType 0;
BA_ "GenSigTimeoutMsg_HU_A" SG_ 468 RctaReqType 0;
BA_ "GenSigSendType" SG_ 468 RctaReqType 2;
BA_ "GenSigTimeoutMsg_HU_High_X445" SG_ 468 RctaReqType 0;
BA_ "GenSigTimeoutMsg_HU_Mid_X445" SG_ 468 RctaReqType 0;
BA_ "GenSigTimeoutTime_HU_High_X445" SG_ 468 RctaReqType 0;
BA_ "GenSigTimeoutTime_HU_Mid_X445" SG_ 468 RctaReqType 0;
BA_ "GenSigTimeoutMsg_IVI" SG_ 468 RctaReqType 0;
BA_ "GenSigTimeoutTime_IVI" SG_ 468 RctaReqType 0;
BA_ "GenSigTimeoutTime_HU_Mid_X451" SG_ 468 RctaOnOffStateReq 0;
BA_ "GenSigTimeoutTime_HU_High_X451" SG_ 468 RctaOnOffStateReq 0;
BA_ "GenSigTimeoutTime_HU_B" SG_ 468 RctaOnOffStateReq 0;
BA_ "GenSigTimeoutTime_HU_A" SG_ 468 RctaOnOffStateReq 0;
BA_ "GenSigTimeoutMsg_HU_Mid_X451" SG_ 468 RctaOnOffStateReq 0;
BA_ "GenSigTimeoutMsg_HU_High_X451" SG_ 468 RctaOnOffStateReq 0;
BA_ "GenSigTimeoutMsg_HU_B" SG_ 468 RctaOnOffStateReq 0;
BA_ "GenSigTimeoutMsg_HU_A" SG_ 468 RctaOnOffStateReq 0;
BA_ "GenSigSendType" SG_ 468 RctaOnOffStateReq 2;
BA_ "GenSigTimeoutMsg_HU_High_X445" SG_ 468 RctaOnOffStateReq 0;
BA_ "GenSigTimeoutMsg_HU_Mid_X445" SG_ 468 RctaOnOffStateReq 0;
BA_ "GenSigTimeoutTime_HU_High_X445" SG_ 468 RctaOnOffStateReq 0;
BA_ "GenSigTimeoutTime_HU_Mid_X445" SG_ 468 RctaOnOffStateReq 0;
BA_ "GenSigTimeoutMsg_IVI" SG_ 468 RctaOnOffStateReq 0;
BA_ "GenSigTimeoutTime_IVI" SG_ 468 RctaOnOffStateReq 0;
BA_ "GenSigTimeoutTime_HU_Mid_X451" SG_ 468 RctaOnOffStateAck 0;
BA_ "GenSigTimeoutTime_HU_High_X451" SG_ 468 RctaOnOffStateAck 0;
BA_ "GenSigTimeoutTime_HU_B" SG_ 468 RctaOnOffStateAck 0;
BA_ "GenSigTimeoutTime_HU_A" SG_ 468 RctaOnOffStateAck 0;
BA_ "GenSigTimeoutMsg_HU_Mid_X451" SG_ 468 RctaOnOffStateAck 0;
BA_ "GenSigTimeoutMsg_HU_High_X451" SG_ 468 RctaOnOffStateAck 0;
BA_ "GenSigTimeoutMsg_HU_B" SG_ 468 RctaOnOffStateAck 0;
BA_ "GenSigTimeoutMsg_HU_A" SG_ 468 RctaOnOffStateAck 0;
BA_ "GenSigSendType" SG_ 468 RctaOnOffStateAck 2;
BA_ "GenSigTimeoutMsg_HU_High_X445" SG_ 468 RctaOnOffStateAck 0;
BA_ "GenSigTimeoutMsg_HU_Mid_X445" SG_ 468 RctaOnOffStateAck 0;
BA_ "GenSigTimeoutTime_HU_High_X445" SG_ 468 RctaOnOffStateAck 0;
BA_ "GenSigTimeoutTime_HU_Mid_X445" SG_ 468 RctaOnOffStateAck 0;
BA_ "GenSigTimeoutMsg_IVI" SG_ 468 RctaOnOffStateAck 0;
BA_ "GenSigTimeoutTime_IVI" SG_ 468 RctaOnOffStateAck 0;
BA_ "GenSigTimeoutTime_HU_Mid_X451" SG_ 468 DoaReqType 0;
BA_ "GenSigTimeoutTime_HU_High_X451" SG_ 468 DoaReqType 0;
BA_ "GenSigTimeoutTime_HU_B" SG_ 468 DoaReqType 0;
BA_ "GenSigTimeoutTime_HU_A" SG_ 468 DoaReqType 0;
BA_ "GenSigTimeoutMsg_HU_Mid_X451" SG_ 468 DoaReqType 0;
BA_ "GenSigTimeoutMsg_HU_High_X451" SG_ 468 DoaReqType 0;
BA_ "GenSigTimeoutMsg_HU_B" SG_ 468 DoaReqType 0;
BA_ "GenSigTimeoutMsg_HU_A" SG_ 468 DoaReqType 0;
BA_ "GenSigSendType" SG_ 468 DoaReqType 2;
BA_ "GenSigTimeoutMsg_HU_High_X445" SG_ 468 DoaReqType 0;
BA_ "GenSigTimeoutMsg_HU_Mid_X445" SG_ 468 DoaReqType 0;
BA_ "GenSigTimeoutTime_HU_High_X445" SG_ 468 DoaReqType 0;
BA_ "GenSigTimeoutTime_HU_Mid_X445" SG_ 468 DoaReqType 0;
BA_ "GenSigTimeoutMsg_IVI" SG_ 468 DoaReqType 0;
BA_ "GenSigTimeoutTime_IVI" SG_ 468 DoaReqType 0;
BA_ "GenSigTimeoutTime_HU_Mid_X451" SG_ 468 DoaOnOffStateReq 0;
BA_ "GenSigTimeoutTime_HU_High_X451" SG_ 468 DoaOnOffStateReq 0;
BA_ "GenSigTimeoutTime_HU_B" SG_ 468 DoaOnOffStateReq 0;
BA_ "GenSigTimeoutTime_HU_A" SG_ 468 DoaOnOffStateReq 0;
BA_ "GenSigTimeoutMsg_HU_Mid_X451" SG_ 468 DoaOnOffStateReq 0;
BA_ "GenSigTimeoutMsg_HU_High_X451" SG_ 468 DoaOnOffStateReq 0;
BA_ "GenSigTimeoutMsg_HU_B" SG_ 468 DoaOnOffStateReq 0;
BA_ "GenSigTimeoutMsg_HU_A" SG_ 468 DoaOnOffStateReq 0;
BA_ "GenSigSendType" SG_ 468 DoaOnOffStateReq 2;
BA_ "GenSigTimeoutMsg_HU_High_X445" SG_ 468 DoaOnOffStateReq 0;
BA_ "GenSigTimeoutMsg_HU_Mid_X445" SG_ 468 DoaOnOffStateReq 0;
BA_ "GenSigTimeoutTime_HU_High_X445" SG_ 468 DoaOnOffStateReq 0;
BA_ "GenSigTimeoutTime_HU_Mid_X445" SG_ 468 DoaOnOffStateReq 0;
BA_ "GenSigTimeoutMsg_IVI" SG_ 468 DoaOnOffStateReq 0;
BA_ "GenSigTimeoutTime_IVI" SG_ 468 DoaOnOffStateReq 0;
BA_ "GenSigTimeoutTime_HU_Mid_X451" SG_ 468 DoaOnOffStateAck 0;
BA_ "GenSigTimeoutTime_HU_High_X451" SG_ 468 DoaOnOffStateAck 0;
BA_ "GenSigTimeoutTime_HU_B" SG_ 468 DoaOnOffStateAck 0;
BA_ "GenSigTimeoutTime_HU_A" SG_ 468 DoaOnOffStateAck 0;
BA_ "GenSigTimeoutMsg_HU_Mid_X451" SG_ 468 DoaOnOffStateAck 0;
BA_ "GenSigTimeoutMsg_HU_High_X451" SG_ 468 DoaOnOffStateAck 0;
BA_ "GenSigTimeoutMsg_HU_B" SG_ 468 DoaOnOffStateAck 0;
BA_ "GenSigTimeoutMsg_HU_A" SG_ 468 DoaOnOffStateAck 0;
BA_ "GenSigSendType" SG_ 468 DoaOnOffStateAck 2;
BA_ "GenSigTimeoutMsg_HU_High_X445" SG_ 468 DoaOnOffStateAck 0;
BA_ "GenSigTimeoutMsg_HU_Mid_X445" SG_ 468 DoaOnOffStateAck 0;
BA_ "GenSigTimeoutTime_HU_High_X445" SG_ 468 DoaOnOffStateAck 0;
BA_ "GenSigTimeoutTime_HU_Mid_X445" SG_ 468 DoaOnOffStateAck 0;
BA_ "GenSigTimeoutMsg_IVI" SG_ 468 DoaOnOffStateAck 0;
BA_ "GenSigTimeoutTime_IVI" SG_ 468 DoaOnOffStateAck 0;
BA_ "GenSigTimeoutTime_HU_Mid_X451" SG_ 468 BsdReqType 0;
BA_ "GenSigTimeoutTime_HU_High_X451" SG_ 468 BsdReqType 0;
BA_ "GenSigTimeoutTime_HU_B" SG_ 468 BsdReqType 0;
BA_ "GenSigTimeoutTime_HU_A" SG_ 468 BsdReqType 0;
BA_ "GenSigTimeoutMsg_HU_Mid_X451" SG_ 468 BsdReqType 0;
BA_ "GenSigTimeoutMsg_HU_High_X451" SG_ 468 BsdReqType 0;
BA_ "GenSigTimeoutMsg_HU_B" SG_ 468 BsdReqType 0;
BA_ "GenSigTimeoutMsg_HU_A" SG_ 468 BsdReqType 0;
BA_ "GenSigSendType" SG_ 468 BsdReqType 2;
BA_ "GenSigTimeoutMsg_HU_High_X445" SG_ 468 BsdReqType 0;
BA_ "GenSigTimeoutMsg_HU_Mid_X445" SG_ 468 BsdReqType 0;
BA_ "GenSigTimeoutTime_HU_High_X445" SG_ 468 BsdReqType 0;
BA_ "GenSigTimeoutTime_HU_Mid_X445" SG_ 468 BsdReqType 0;
BA_ "GenSigTimeoutMsg_IVI" SG_ 468 BsdReqType 0;
BA_ "GenSigTimeoutTime_IVI" SG_ 468 BsdReqType 0;
BA_ "GenSigTimeoutTime_HU_Mid_X451" SG_ 468 BsdOnOffStateReq 0;
BA_ "GenSigTimeoutTime_HU_High_X451" SG_ 468 BsdOnOffStateReq 0;
BA_ "GenSigTimeoutTime_HU_B" SG_ 468 BsdOnOffStateReq 0;
BA_ "GenSigTimeoutTime_HU_A" SG_ 468 BsdOnOffStateReq 0;
BA_ "GenSigTimeoutMsg_HU_Mid_X451" SG_ 468 BsdOnOffStateReq 0;
BA_ "GenSigTimeoutMsg_HU_High_X451" SG_ 468 BsdOnOffStateReq 0;
BA_ "GenSigTimeoutMsg_HU_B" SG_ 468 BsdOnOffStateReq 0;
BA_ "GenSigTimeoutMsg_HU_A" SG_ 468 BsdOnOffStateReq 0;
BA_ "GenSigSendType" SG_ 468 BsdOnOffStateReq 2;
BA_ "GenSigTimeoutMsg_HU_High_X445" SG_ 468 BsdOnOffStateReq 0;
BA_ "GenSigTimeoutMsg_HU_Mid_X445" SG_ 468 BsdOnOffStateReq 0;
BA_ "GenSigTimeoutTime_HU_High_X445" SG_ 468 BsdOnOffStateReq 0;
BA_ "GenSigTimeoutTime_HU_Mid_X445" SG_ 468 BsdOnOffStateReq 0;
BA_ "GenSigTimeoutMsg_IVI" SG_ 468 BsdOnOffStateReq 0;
BA_ "GenSigTimeoutTime_IVI" SG_ 468 BsdOnOffStateReq 0;
BA_ "GenSigTimeoutTime_HU_Mid_X451" SG_ 468 BsdOnOffStateAck 0;
BA_ "GenSigTimeoutTime_HU_High_X451" SG_ 468 BsdOnOffStateAck 0;
BA_ "GenSigTimeoutTime_HU_B" SG_ 468 BsdOnOffStateAck 0;
BA_ "GenSigTimeoutTime_HU_A" SG_ 468 BsdOnOffStateAck 0;
BA_ "GenSigTimeoutMsg_HU_Mid_X451" SG_ 468 BsdOnOffStateAck 0;
BA_ "GenSigTimeoutMsg_HU_High_X451" SG_ 468 BsdOnOffStateAck 0;
BA_ "GenSigTimeoutMsg_HU_B" SG_ 468 BsdOnOffStateAck 0;
BA_ "GenSigTimeoutMsg_HU_A" SG_ 468 BsdOnOffStateAck 0;
BA_ "GenSigSendType" SG_ 468 BsdOnOffStateAck 2;
BA_ "GenSigTimeoutMsg_HU_High_X445" SG_ 468 BsdOnOffStateAck 0;
BA_ "GenSigTimeoutMsg_HU_Mid_X445" SG_ 468 BsdOnOffStateAck 0;
BA_ "GenSigTimeoutTime_HU_High_X445" SG_ 468 BsdOnOffStateAck 0;
BA_ "GenSigTimeoutTime_HU_Mid_X445" SG_ 468 BsdOnOffStateAck 0;
BA_ "GenSigTimeoutMsg_IVI" SG_ 468 BsdOnOffStateAck 0;
BA_ "GenSigTimeoutTime_IVI" SG_ 468 BsdOnOffStateAck 0;
BA_ "GenSigTimeoutTime_HU_Mid_X451" SG_ 468 FcwAebWarnSetStateReq 0;
BA_ "GenSigTimeoutTime_HU_High_X451" SG_ 468 FcwAebWarnSetStateReq 0;
BA_ "GenSigTimeoutTime_HU_B" SG_ 468 FcwAebWarnSetStateReq 0;
BA_ "GenSigTimeoutTime_HU_A" SG_ 468 FcwAebWarnSetStateReq 0;
BA_ "GenSigTimeoutMsg_HU_Mid_X451" SG_ 468 FcwAebWarnSetStateReq 0;
BA_ "GenSigTimeoutMsg_HU_High_X451" SG_ 468 FcwAebWarnSetStateReq 0;
BA_ "GenSigTimeoutMsg_HU_B" SG_ 468 FcwAebWarnSetStateReq 0;
BA_ "GenSigTimeoutMsg_HU_A" SG_ 468 FcwAebWarnSetStateReq 0;
BA_ "GenSigSendType" SG_ 468 FcwAebWarnSetStateReq 2;
BA_ "GenSigTimeoutMsg_HU_High_X445" SG_ 468 FcwAebWarnSetStateReq 0;
BA_ "GenSigTimeoutMsg_HU_Mid_X445" SG_ 468 FcwAebWarnSetStateReq 0;
BA_ "GenSigTimeoutTime_HU_High_X445" SG_ 468 FcwAebWarnSetStateReq 0;
BA_ "GenSigTimeoutTime_HU_Mid_X445" SG_ 468 FcwAebWarnSetStateReq 0;
BA_ "GenSigTimeoutMsg_IVI" SG_ 468 FcwAebWarnSetStateReq 0;
BA_ "GenSigTimeoutTime_IVI" SG_ 468 FcwAebWarnSetStateReq 0;
BA_ "GenSigTimeoutTime_HU_Mid_X451" SG_ 468 FcwAebWarnSetStateAck 0;
BA_ "GenSigTimeoutTime_HU_High_X451" SG_ 468 FcwAebWarnSetStateAck 0;
BA_ "GenSigTimeoutTime_HU_B" SG_ 468 FcwAebWarnSetStateAck 0;
BA_ "GenSigTimeoutTime_HU_A" SG_ 468 FcwAebWarnSetStateAck 0;
BA_ "GenSigTimeoutMsg_HU_Mid_X451" SG_ 468 FcwAebWarnSetStateAck 0;
BA_ "GenSigTimeoutMsg_HU_High_X451" SG_ 468 FcwAebWarnSetStateAck 0;
BA_ "GenSigTimeoutMsg_HU_B" SG_ 468 FcwAebWarnSetStateAck 0;
BA_ "GenSigTimeoutMsg_HU_A" SG_ 468 FcwAebWarnSetStateAck 0;
BA_ "GenSigSendType" SG_ 468 FcwAebWarnSetStateAck 2;
BA_ "GenSigTimeoutMsg_HU_High_X445" SG_ 468 FcwAebWarnSetStateAck 0;
BA_ "GenSigTimeoutMsg_HU_Mid_X445" SG_ 468 FcwAebWarnSetStateAck 0;
BA_ "GenSigTimeoutTime_HU_High_X445" SG_ 468 FcwAebWarnSetStateAck 0;
BA_ "GenSigTimeoutTime_HU_Mid_X445" SG_ 468 FcwAebWarnSetStateAck 0;
BA_ "GenSigTimeoutMsg_IVI" SG_ 468 FcwAebWarnSetStateAck 0;
BA_ "GenSigTimeoutTime_IVI" SG_ 468 FcwAebWarnSetStateAck 0;
BA_ "GenSigTimeoutTime_HU_Mid_X451" SG_ 468 FcwAebReqType 0;
BA_ "GenSigTimeoutTime_HU_High_X451" SG_ 468 FcwAebReqType 0;
BA_ "GenSigTimeoutTime_HU_B" SG_ 468 FcwAebReqType 0;
BA_ "GenSigTimeoutTime_HU_A" SG_ 468 FcwAebReqType 0;
BA_ "GenSigTimeoutMsg_HU_Mid_X451" SG_ 468 FcwAebReqType 0;
BA_ "GenSigTimeoutMsg_HU_High_X451" SG_ 468 FcwAebReqType 0;
BA_ "GenSigTimeoutMsg_HU_B" SG_ 468 FcwAebReqType 0;
BA_ "GenSigTimeoutMsg_HU_A" SG_ 468 FcwAebReqType 0;
BA_ "GenSigSendType" SG_ 468 FcwAebReqType 2;
BA_ "GenSigTimeoutMsg_HU_High_X445" SG_ 468 FcwAebReqType 0;
BA_ "GenSigTimeoutMsg_HU_Mid_X445" SG_ 468 FcwAebReqType 0;
BA_ "GenSigTimeoutTime_HU_High_X445" SG_ 468 FcwAebReqType 0;
BA_ "GenSigTimeoutTime_HU_Mid_X445" SG_ 468 FcwAebReqType 0;
BA_ "GenSigTimeoutMsg_IVI" SG_ 468 FcwAebReqType 0;
BA_ "GenSigTimeoutTime_IVI" SG_ 468 FcwAebReqType 0;
BA_ "GenSigTimeoutTime_HU_Mid_X451" SG_ 468 FcwAebOnOffStateReq 0;
BA_ "GenSigTimeoutTime_HU_High_X451" SG_ 468 FcwAebOnOffStateReq 0;
BA_ "GenSigTimeoutTime_HU_B" SG_ 468 FcwAebOnOffStateReq 0;
BA_ "GenSigTimeoutTime_HU_A" SG_ 468 FcwAebOnOffStateReq 0;
BA_ "GenSigTimeoutMsg_HU_Mid_X451" SG_ 468 FcwAebOnOffStateReq 0;
BA_ "GenSigTimeoutMsg_HU_High_X451" SG_ 468 FcwAebOnOffStateReq 0;
BA_ "GenSigTimeoutMsg_HU_B" SG_ 468 FcwAebOnOffStateReq 0;
BA_ "GenSigTimeoutMsg_HU_A" SG_ 468 FcwAebOnOffStateReq 0;
BA_ "GenSigSendType" SG_ 468 FcwAebOnOffStateReq 2;
BA_ "GenSigTimeoutMsg_HU_High_X445" SG_ 468 FcwAebOnOffStateReq 0;
BA_ "GenSigTimeoutMsg_HU_Mid_X445" SG_ 468 FcwAebOnOffStateReq 0;
BA_ "GenSigTimeoutTime_HU_High_X445" SG_ 468 FcwAebOnOffStateReq 0;
BA_ "GenSigTimeoutTime_HU_Mid_X445" SG_ 468 FcwAebOnOffStateReq 0;
BA_ "GenSigTimeoutMsg_IVI" SG_ 468 FcwAebOnOffStateReq 0;
BA_ "GenSigTimeoutTime_IVI" SG_ 468 FcwAebOnOffStateReq 0;
BA_ "GenSigTimeoutTime_HU_Mid_X451" SG_ 468 FcwAebOnOffStateAck 0;
BA_ "GenSigTimeoutTime_HU_High_X451" SG_ 468 FcwAebOnOffStateAck 0;
BA_ "GenSigTimeoutTime_HU_B" SG_ 468 FcwAebOnOffStateAck 0;
BA_ "GenSigTimeoutTime_HU_A" SG_ 468 FcwAebOnOffStateAck 0;
BA_ "GenSigTimeoutMsg_HU_Mid_X451" SG_ 468 FcwAebOnOffStateAck 0;
BA_ "GenSigTimeoutMsg_HU_High_X451" SG_ 468 FcwAebOnOffStateAck 0;
BA_ "GenSigTimeoutMsg_HU_B" SG_ 468 FcwAebOnOffStateAck 0;
BA_ "GenSigTimeoutMsg_HU_A" SG_ 468 FcwAebOnOffStateAck 0;
BA_ "GenSigSendType" SG_ 468 FcwAebOnOffStateAck 2;
BA_ "GenSigTimeoutMsg_HU_High_X445" SG_ 468 FcwAebOnOffStateAck 0;
BA_ "GenSigTimeoutMsg_HU_Mid_X445" SG_ 468 FcwAebOnOffStateAck 0;
BA_ "GenSigTimeoutTime_HU_High_X445" SG_ 468 FcwAebOnOffStateAck 0;
BA_ "GenSigTimeoutTime_HU_Mid_X445" SG_ 468 FcwAebOnOffStateAck 0;
BA_ "GenSigTimeoutMsg_IVI" SG_ 468 FcwAebOnOffStateAck 0;
BA_ "GenSigTimeoutTime_IVI" SG_ 468 FcwAebOnOffStateAck 0;
BA_ "GenSigTimeoutTime_HU_Mid_X451" SG_ 468 TsrReqType 0;
BA_ "GenSigTimeoutTime_HU_High_X451" SG_ 468 TsrReqType 0;
BA_ "GenSigTimeoutTime_HU_B" SG_ 468 TsrReqType 0;
BA_ "GenSigTimeoutTime_HU_A" SG_ 468 TsrReqType 0;
BA_ "GenSigTimeoutMsg_HU_Mid_X451" SG_ 468 TsrReqType 0;
BA_ "GenSigTimeoutMsg_HU_High_X451" SG_ 468 TsrReqType 0;
BA_ "GenSigTimeoutMsg_HU_B" SG_ 468 TsrReqType 0;
BA_ "GenSigTimeoutMsg_HU_A" SG_ 468 TsrReqType 0;
BA_ "GenSigSendType" SG_ 468 TsrReqType 2;
BA_ "GenSigTimeoutMsg_HU_High_X445" SG_ 468 TsrReqType 0;
BA_ "GenSigTimeoutMsg_HU_Mid_X445" SG_ 468 TsrReqType 0;
BA_ "GenSigTimeoutTime_HU_High_X445" SG_ 468 TsrReqType 0;
BA_ "GenSigTimeoutTime_HU_Mid_X445" SG_ 468 TsrReqType 0;
BA_ "GenSigTimeoutMsg_IVI" SG_ 468 TsrReqType 0;
BA_ "GenSigTimeoutTime_IVI" SG_ 468 TsrReqType 0;
BA_ "GenSigTimeoutTime_HU_Mid_X451" SG_ 468 TsrOnOffStateReq 0;
BA_ "GenSigTimeoutTime_HU_High_X451" SG_ 468 TsrOnOffStateReq 0;
BA_ "GenSigTimeoutTime_HU_B" SG_ 468 TsrOnOffStateReq 0;
BA_ "GenSigTimeoutTime_HU_A" SG_ 468 TsrOnOffStateReq 0;
BA_ "GenSigTimeoutMsg_HU_Mid_X451" SG_ 468 TsrOnOffStateReq 0;
BA_ "GenSigTimeoutMsg_HU_High_X451" SG_ 468 TsrOnOffStateReq 0;
BA_ "GenSigTimeoutMsg_HU_B" SG_ 468 TsrOnOffStateReq 0;
BA_ "GenSigTimeoutMsg_HU_A" SG_ 468 TsrOnOffStateReq 0;
BA_ "GenSigSendType" SG_ 468 TsrOnOffStateReq 2;
BA_ "GenSigTimeoutMsg_HU_High_X445" SG_ 468 TsrOnOffStateReq 0;
BA_ "GenSigTimeoutMsg_HU_Mid_X445" SG_ 468 TsrOnOffStateReq 0;
BA_ "GenSigTimeoutTime_HU_High_X445" SG_ 468 TsrOnOffStateReq 0;
BA_ "GenSigTimeoutTime_HU_Mid_X445" SG_ 468 TsrOnOffStateReq 0;
BA_ "GenSigTimeoutMsg_IVI" SG_ 468 TsrOnOffStateReq 0;
BA_ "GenSigTimeoutTime_IVI" SG_ 468 TsrOnOffStateReq 0;
BA_ "GenSigTimeoutTime_HU_Mid_X451" SG_ 468 TsrOnOffStateAck 0;
BA_ "GenSigTimeoutTime_HU_High_X451" SG_ 468 TsrOnOffStateAck 0;
BA_ "GenSigTimeoutTime_HU_B" SG_ 468 TsrOnOffStateAck 0;
BA_ "GenSigTimeoutTime_HU_A" SG_ 468 TsrOnOffStateAck 0;
BA_ "GenSigTimeoutMsg_HU_Mid_X451" SG_ 468 TsrOnOffStateAck 0;
BA_ "GenSigTimeoutMsg_HU_High_X451" SG_ 468 TsrOnOffStateAck 0;
BA_ "GenSigTimeoutMsg_HU_B" SG_ 468 TsrOnOffStateAck 0;
BA_ "GenSigTimeoutMsg_HU_A" SG_ 468 TsrOnOffStateAck 0;
BA_ "GenSigSendType" SG_ 468 TsrOnOffStateAck 2;
BA_ "GenSigTimeoutMsg_HU_High_X445" SG_ 468 TsrOnOffStateAck 0;
BA_ "GenSigTimeoutMsg_HU_Mid_X445" SG_ 468 TsrOnOffStateAck 0;
BA_ "GenSigTimeoutTime_HU_High_X445" SG_ 468 TsrOnOffStateAck 0;
BA_ "GenSigTimeoutTime_HU_Mid_X445" SG_ 468 TsrOnOffStateAck 0;
BA_ "GenSigTimeoutMsg_IVI" SG_ 468 TsrOnOffStateAck 0;
BA_ "GenSigTimeoutTime_IVI" SG_ 468 TsrOnOffStateAck 0;
BA_ "GenSigTimeoutTime_HU_Mid_X451" SG_ 468 LdwOnOffStateReq 0;
BA_ "GenSigTimeoutTime_HU_High_X451" SG_ 468 LdwOnOffStateReq 0;
BA_ "GenSigTimeoutTime_HU_B" SG_ 468 LdwOnOffStateReq 0;
BA_ "GenSigTimeoutTime_HU_A" SG_ 468 LdwOnOffStateReq 0;
BA_ "GenSigTimeoutMsg_HU_Mid_X451" SG_ 468 LdwOnOffStateReq 0;
BA_ "GenSigTimeoutMsg_HU_High_X451" SG_ 468 LdwOnOffStateReq 0;
BA_ "GenSigTimeoutMsg_HU_B" SG_ 468 LdwOnOffStateReq 0;
BA_ "GenSigTimeoutMsg_HU_A" SG_ 468 LdwOnOffStateReq 0;
BA_ "GenSigSendType" SG_ 468 LdwOnOffStateReq 2;
BA_ "GenSigTimeoutMsg_HU_High_X445" SG_ 468 LdwOnOffStateReq 0;
BA_ "GenSigTimeoutMsg_HU_Mid_X445" SG_ 468 LdwOnOffStateReq 0;
BA_ "GenSigTimeoutTime_HU_High_X445" SG_ 468 LdwOnOffStateReq 0;
BA_ "GenSigTimeoutTime_HU_Mid_X445" SG_ 468 LdwOnOffStateReq 0;
BA_ "GenSigTimeoutMsg_IVI" SG_ 468 LdwOnOffStateReq 0;
BA_ "GenSigTimeoutTime_IVI" SG_ 468 LdwOnOffStateReq 0;
BA_ "GenSigTimeoutTime_HU_Mid_X451" SG_ 468 LdwReqType 0;
BA_ "GenSigTimeoutTime_HU_High_X451" SG_ 468 LdwReqType 0;
BA_ "GenSigTimeoutTime_HU_B" SG_ 468 LdwReqType 0;
BA_ "GenSigTimeoutTime_HU_A" SG_ 468 LdwReqType 0;
BA_ "GenSigTimeoutMsg_HU_Mid_X451" SG_ 468 LdwReqType 0;
BA_ "GenSigTimeoutMsg_HU_High_X451" SG_ 468 LdwReqType 0;
BA_ "GenSigTimeoutMsg_HU_B" SG_ 468 LdwReqType 0;
BA_ "GenSigTimeoutMsg_HU_A" SG_ 468 LdwReqType 0;
BA_ "GenSigSendType" SG_ 468 LdwReqType 2;
BA_ "GenSigTimeoutMsg_HU_High_X445" SG_ 468 LdwReqType 0;
BA_ "GenSigTimeoutMsg_HU_Mid_X445" SG_ 468 LdwReqType 0;
BA_ "GenSigTimeoutTime_HU_High_X445" SG_ 468 LdwReqType 0;
BA_ "GenSigTimeoutTime_HU_Mid_X445" SG_ 468 LdwReqType 0;
BA_ "GenSigTimeoutMsg_IVI" SG_ 468 LdwReqType 0;
BA_ "GenSigTimeoutTime_IVI" SG_ 468 LdwReqType 0;
BA_ "GenSigTimeoutTime_HU_Mid_X451" SG_ 468 LdwOnOffStateAck 0;
BA_ "GenSigTimeoutTime_HU_High_X451" SG_ 468 LdwOnOffStateAck 0;
BA_ "GenSigTimeoutTime_HU_B" SG_ 468 LdwOnOffStateAck 0;
BA_ "GenSigTimeoutTime_HU_A" SG_ 468 LdwOnOffStateAck 0;
BA_ "GenSigTimeoutMsg_HU_Mid_X451" SG_ 468 LdwOnOffStateAck 0;
BA_ "GenSigTimeoutMsg_HU_High_X451" SG_ 468 LdwOnOffStateAck 0;
BA_ "GenSigTimeoutMsg_HU_B" SG_ 468 LdwOnOffStateAck 0;
BA_ "GenSigTimeoutMsg_HU_A" SG_ 468 LdwOnOffStateAck 0;
BA_ "GenSigSendType" SG_ 468 LdwOnOffStateAck 2;
BA_ "GenSigTimeoutMsg_HU_High_X445" SG_ 468 LdwOnOffStateAck 0;
BA_ "GenSigTimeoutMsg_HU_Mid_X445" SG_ 468 LdwOnOffStateAck 0;
BA_ "GenSigTimeoutTime_HU_High_X445" SG_ 468 LdwOnOffStateAck 0;
BA_ "GenSigTimeoutTime_HU_Mid_X445" SG_ 468 LdwOnOffStateAck 0;
BA_ "GenSigTimeoutMsg_IVI" SG_ 468 LdwOnOffStateAck 0;
BA_ "GenSigTimeoutTime_IVI" SG_ 468 LdwOnOffStateAck 0;
BA_ "GenSigTimeoutTime_HU_Mid_X451" SG_ 468 HbaOnOffStateReq 0;
BA_ "GenSigTimeoutTime_HU_High_X451" SG_ 468 HbaOnOffStateReq 0;
BA_ "GenSigTimeoutTime_HU_B" SG_ 468 HbaOnOffStateReq 0;
BA_ "GenSigTimeoutTime_HU_A" SG_ 468 HbaOnOffStateReq 0;
BA_ "GenSigTimeoutMsg_HU_Mid_X451" SG_ 468 HbaOnOffStateReq 0;
BA_ "GenSigTimeoutMsg_HU_High_X451" SG_ 468 HbaOnOffStateReq 0;
BA_ "GenSigTimeoutMsg_HU_B" SG_ 468 HbaOnOffStateReq 0;
BA_ "GenSigTimeoutMsg_HU_A" SG_ 468 HbaOnOffStateReq 0;
BA_ "GenSigSendType" SG_ 468 HbaOnOffStateReq 2;
BA_ "GenSigTimeoutMsg_HU_High_X445" SG_ 468 HbaOnOffStateReq 0;
BA_ "GenSigTimeoutMsg_HU_Mid_X445" SG_ 468 HbaOnOffStateReq 0;
BA_ "GenSigTimeoutTime_HU_High_X445" SG_ 468 HbaOnOffStateReq 0;
BA_ "GenSigTimeoutTime_HU_Mid_X445" SG_ 468 HbaOnOffStateReq 0;
BA_ "GenSigTimeoutMsg_IVI" SG_ 468 HbaOnOffStateReq 0;
BA_ "GenSigTimeoutTime_IVI" SG_ 468 HbaOnOffStateReq 0;
BA_ "GenSigTimeoutTime_HU_Mid_X451" SG_ 468 HbaReqType 0;
BA_ "GenSigTimeoutTime_HU_High_X451" SG_ 468 HbaReqType 0;
BA_ "GenSigTimeoutTime_HU_B" SG_ 468 HbaReqType 0;
BA_ "GenSigTimeoutTime_HU_A" SG_ 468 HbaReqType 0;
BA_ "GenSigTimeoutMsg_HU_Mid_X451" SG_ 468 HbaReqType 0;
BA_ "GenSigTimeoutMsg_HU_High_X451" SG_ 468 HbaReqType 0;
BA_ "GenSigTimeoutMsg_HU_B" SG_ 468 HbaReqType 0;
BA_ "GenSigTimeoutMsg_HU_A" SG_ 468 HbaReqType 0;
BA_ "GenSigSendType" SG_ 468 HbaReqType 2;
BA_ "GenSigTimeoutMsg_HU_High_X445" SG_ 468 HbaReqType 0;
BA_ "GenSigTimeoutMsg_HU_Mid_X445" SG_ 468 HbaReqType 0;
BA_ "GenSigTimeoutTime_HU_High_X445" SG_ 468 HbaReqType 0;
BA_ "GenSigTimeoutTime_HU_Mid_X445" SG_ 468 HbaReqType 0;
BA_ "GenSigTimeoutMsg_IVI" SG_ 468 HbaReqType 0;
BA_ "GenSigTimeoutTime_IVI" SG_ 468 HbaReqType 0;
BA_ "GenSigTimeoutTime_HU_Mid_X451" SG_ 468 HbaOnOffStateAck 0;
BA_ "GenSigTimeoutTime_HU_High_X451" SG_ 468 HbaOnOffStateAck 0;
BA_ "GenSigTimeoutTime_HU_B" SG_ 468 HbaOnOffStateAck 0;
BA_ "GenSigTimeoutTime_HU_A" SG_ 468 HbaOnOffStateAck 0;
BA_ "GenSigTimeoutMsg_HU_Mid_X451" SG_ 468 HbaOnOffStateAck 0;
BA_ "GenSigTimeoutMsg_HU_High_X451" SG_ 468 HbaOnOffStateAck 0;
BA_ "GenSigTimeoutMsg_HU_B" SG_ 468 HbaOnOffStateAck 0;
BA_ "GenSigTimeoutMsg_HU_A" SG_ 468 HbaOnOffStateAck 0;
BA_ "GenSigSendType" SG_ 468 HbaOnOffStateAck 2;
BA_ "GenSigTimeoutMsg_HU_High_X445" SG_ 468 HbaOnOffStateAck 0;
BA_ "GenSigTimeoutMsg_HU_Mid_X445" SG_ 468 HbaOnOffStateAck 0;
BA_ "GenSigTimeoutTime_HU_High_X445" SG_ 468 HbaOnOffStateAck 0;
BA_ "GenSigTimeoutTime_HU_Mid_X445" SG_ 468 HbaOnOffStateAck 0;
BA_ "GenSigTimeoutMsg_IVI" SG_ 468 HbaOnOffStateAck 0;
BA_ "GenSigTimeoutTime_IVI" SG_ 468 HbaOnOffStateAck 0;
BA_ "GenSigTimeoutTime_HU_Mid_X451" SG_ 471 LdwWarningSettingConfigState 0;
BA_ "GenSigTimeoutTime_HU_High_X451" SG_ 471 LdwWarningSettingConfigState 0;
BA_ "GenSigTimeoutTime_HU_B" SG_ 471 LdwWarningSettingConfigState 0;
BA_ "GenSigTimeoutTime_HU_A" SG_ 471 LdwWarningSettingConfigState 0;
BA_ "GenSigTimeoutMsg_HU_Mid_X451" SG_ 471 LdwWarningSettingConfigState 0;
BA_ "GenSigTimeoutMsg_HU_High_X451" SG_ 471 LdwWarningSettingConfigState 0;
BA_ "GenSigTimeoutMsg_HU_B" SG_ 471 LdwWarningSettingConfigState 0;
BA_ "GenSigTimeoutMsg_HU_A" SG_ 471 LdwWarningSettingConfigState 0;
BA_ "GenSigSendType" SG_ 471 LdwWarningSettingConfigState 2;
BA_ "GenSigTimeoutMsg_HU_High_X445" SG_ 471 LdwWarningSettingConfigState 0;
BA_ "GenSigTimeoutMsg_HU_Mid_X445" SG_ 471 LdwWarningSettingConfigState 0;
BA_ "GenSigTimeoutTime_HU_High_X445" SG_ 471 LdwWarningSettingConfigState 0;
BA_ "GenSigTimeoutTime_HU_Mid_X445" SG_ 471 LdwWarningSettingConfigState 0;
BA_ "GenSigTimeoutMsg_IVI" SG_ 471 LdwWarningSettingConfigState 0;
BA_ "GenSigTimeoutTime_IVI" SG_ 471 LdwWarningSettingConfigState 0;
BA_ "GenSigTimeoutTime_HU_Mid_X451" SG_ 471 LdwHapticWarningConfigState 0;
BA_ "GenSigTimeoutTime_HU_High_X451" SG_ 471 LdwHapticWarningConfigState 0;
BA_ "GenSigTimeoutTime_HU_B" SG_ 471 LdwHapticWarningConfigState 0;
BA_ "GenSigTimeoutTime_HU_A" SG_ 471 LdwHapticWarningConfigState 0;
BA_ "GenSigTimeoutMsg_HU_Mid_X451" SG_ 471 LdwHapticWarningConfigState 0;
BA_ "GenSigTimeoutMsg_HU_High_X451" SG_ 471 LdwHapticWarningConfigState 0;
BA_ "GenSigTimeoutMsg_HU_B" SG_ 471 LdwHapticWarningConfigState 0;
BA_ "GenSigTimeoutMsg_HU_A" SG_ 471 LdwHapticWarningConfigState 0;
BA_ "GenSigSendType" SG_ 471 LdwHapticWarningConfigState 2;
BA_ "GenSigTimeoutMsg_HU_High_X445" SG_ 471 LdwHapticWarningConfigState 0;
BA_ "GenSigTimeoutMsg_HU_Mid_X445" SG_ 471 LdwHapticWarningConfigState 0;
BA_ "GenSigTimeoutTime_HU_High_X445" SG_ 471 LdwHapticWarningConfigState 0;
BA_ "GenSigTimeoutTime_HU_Mid_X445" SG_ 471 LdwHapticWarningConfigState 0;
BA_ "GenSigTimeoutMsg_IVI" SG_ 471 LdwHapticWarningConfigState 0;
BA_ "GenSigTimeoutTime_IVI" SG_ 471 LdwHapticWarningConfigState 0;
BA_ "GenSigTimeoutTime_HU_Mid_X451" SG_ 471 LcsSignalApplicability 0;
BA_ "GenSigTimeoutTime_HU_High_X451" SG_ 471 LcsSignalApplicability 0;
BA_ "GenSigTimeoutTime_HU_B" SG_ 471 LcsSignalApplicability 0;
BA_ "GenSigTimeoutTime_HU_A" SG_ 471 LcsSignalApplicability 0;
BA_ "GenSigTimeoutMsg_HU_Mid_X451" SG_ 471 LcsSignalApplicability 0;
BA_ "GenSigTimeoutMsg_HU_High_X451" SG_ 471 LcsSignalApplicability 0;
BA_ "GenSigTimeoutMsg_HU_B" SG_ 471 LcsSignalApplicability 0;
BA_ "GenSigTimeoutMsg_HU_A" SG_ 471 LcsSignalApplicability 0;
BA_ "GenSigSendType" SG_ 471 LcsSignalApplicability 2;
BA_ "GenSigTimeoutMsg_HU_High_X445" SG_ 471 LcsSignalApplicability 0;
BA_ "GenSigTimeoutMsg_HU_Mid_X445" SG_ 471 LcsSignalApplicability 0;
BA_ "GenSigTimeoutTime_HU_High_X445" SG_ 471 LcsSignalApplicability 0;
BA_ "GenSigTimeoutTime_HU_Mid_X445" SG_ 471 LcsSignalApplicability 0;
BA_ "GenSigTimeoutMsg_IVI" SG_ 471 LcsSignalApplicability 0;
BA_ "GenSigTimeoutTime_IVI" SG_ 471 LcsSignalApplicability 0;
BA_ "GenSigTimeoutTime_HU_Mid_X451" SG_ 471 LcsOnOffConfigState 0;
BA_ "GenSigTimeoutTime_HU_High_X451" SG_ 471 LcsOnOffConfigState 0;
BA_ "GenSigTimeoutTime_HU_B" SG_ 471 LcsOnOffConfigState 0;
BA_ "GenSigTimeoutTime_HU_A" SG_ 471 LcsOnOffConfigState 0;
BA_ "GenSigTimeoutMsg_HU_Mid_X451" SG_ 471 LcsOnOffConfigState 0;
BA_ "GenSigTimeoutMsg_HU_High_X451" SG_ 471 LcsOnOffConfigState 0;
BA_ "GenSigTimeoutMsg_HU_B" SG_ 471 LcsOnOffConfigState 0;
BA_ "GenSigTimeoutMsg_HU_A" SG_ 471 LcsOnOffConfigState 0;
BA_ "GenSigSendType" SG_ 471 LcsOnOffConfigState 2;
BA_ "GenSigTimeoutMsg_HU_High_X445" SG_ 471 LcsOnOffConfigState 0;
BA_ "GenSigTimeoutMsg_HU_Mid_X445" SG_ 471 LcsOnOffConfigState 0;
BA_ "GenSigTimeoutTime_HU_High_X445" SG_ 471 LcsOnOffConfigState 0;
BA_ "GenSigTimeoutTime_HU_Mid_X445" SG_ 471 LcsOnOffConfigState 0;
BA_ "GenSigTimeoutMsg_IVI" SG_ 471 LcsOnOffConfigState 0;
BA_ "GenSigTimeoutTime_IVI" SG_ 471 LcsOnOffConfigState 0;
BA_ "GenSigTimeoutTime_HU_Mid_X451" SG_ 471 AsaSignalApplicability 0;
BA_ "GenSigTimeoutTime_HU_High_X451" SG_ 471 AsaSignalApplicability 0;
BA_ "GenSigTimeoutTime_HU_B" SG_ 471 AsaSignalApplicability 0;
BA_ "GenSigTimeoutTime_HU_A" SG_ 471 AsaSignalApplicability 0;
BA_ "GenSigTimeoutMsg_HU_Mid_X451" SG_ 471 AsaSignalApplicability 0;
BA_ "GenSigTimeoutMsg_HU_High_X451" SG_ 471 AsaSignalApplicability 0;
BA_ "GenSigTimeoutMsg_HU_B" SG_ 471 AsaSignalApplicability 0;
BA_ "GenSigTimeoutMsg_HU_A" SG_ 471 AsaSignalApplicability 0;
BA_ "GenSigSendType" SG_ 471 AsaSignalApplicability 2;
BA_ "GenSigTimeoutMsg_HU_High_X445" SG_ 471 AsaSignalApplicability 0;
BA_ "GenSigTimeoutMsg_HU_Mid_X445" SG_ 471 AsaSignalApplicability 0;
BA_ "GenSigTimeoutTime_HU_High_X445" SG_ 471 AsaSignalApplicability 0;
BA_ "GenSigTimeoutTime_HU_Mid_X445" SG_ 471 AsaSignalApplicability 0;
BA_ "GenSigTimeoutMsg_IVI" SG_ 471 AsaSignalApplicability 0;
BA_ "GenSigTimeoutTime_IVI" SG_ 471 AsaSignalApplicability 0;
BA_ "GenSigTimeoutTime_HU_Mid_X451" SG_ 471 AsaOnOffConfigState 0;
BA_ "GenSigTimeoutTime_HU_High_X451" SG_ 471 AsaOnOffConfigState 0;
BA_ "GenSigTimeoutTime_HU_B" SG_ 471 AsaOnOffConfigState 0;
BA_ "GenSigTimeoutTime_HU_A" SG_ 471 AsaOnOffConfigState 0;
BA_ "GenSigTimeoutMsg_HU_Mid_X451" SG_ 471 AsaOnOffConfigState 0;
BA_ "GenSigTimeoutMsg_HU_High_X451" SG_ 471 AsaOnOffConfigState 0;
BA_ "GenSigTimeoutMsg_HU_B" SG_ 471 AsaOnOffConfigState 0;
BA_ "GenSigTimeoutMsg_HU_A" SG_ 471 AsaOnOffConfigState 0;
BA_ "GenSigSendType" SG_ 471 AsaOnOffConfigState 2;
BA_ "GenSigTimeoutMsg_HU_High_X445" SG_ 471 AsaOnOffConfigState 0;
BA_ "GenSigTimeoutMsg_HU_Mid_X445" SG_ 471 AsaOnOffConfigState 0;
BA_ "GenSigTimeoutTime_HU_High_X445" SG_ 471 AsaOnOffConfigState 0;
BA_ "GenSigTimeoutTime_HU_Mid_X445" SG_ 471 AsaOnOffConfigState 0;
BA_ "GenSigTimeoutMsg_IVI" SG_ 471 AsaOnOffConfigState 0;
BA_ "GenSigTimeoutTime_IVI" SG_ 471 AsaOnOffConfigState 0;
BA_ "GenSigTimeoutTime_HU_Mid_X451" SG_ 471 OvrSpdLmtThrshldConfigState 0;
BA_ "GenSigTimeoutTime_HU_High_X451" SG_ 471 OvrSpdLmtThrshldConfigState 0;
BA_ "GenSigTimeoutTime_HU_B" SG_ 471 OvrSpdLmtThrshldConfigState 0;
BA_ "GenSigTimeoutTime_HU_A" SG_ 471 OvrSpdLmtThrshldConfigState 0;
BA_ "GenSigTimeoutMsg_HU_Mid_X451" SG_ 471 OvrSpdLmtThrshldConfigState 0;
BA_ "GenSigTimeoutMsg_HU_High_X451" SG_ 471 OvrSpdLmtThrshldConfigState 0;
BA_ "GenSigTimeoutMsg_HU_B" SG_ 471 OvrSpdLmtThrshldConfigState 0;
BA_ "GenSigTimeoutMsg_HU_A" SG_ 471 OvrSpdLmtThrshldConfigState 0;
BA_ "GenSigSendType" SG_ 471 OvrSpdLmtThrshldConfigState 2;
BA_ "GenSigTimeoutMsg_HU_High_X445" SG_ 471 OvrSpdLmtThrshldConfigState 0;
BA_ "GenSigTimeoutMsg_HU_Mid_X445" SG_ 471 OvrSpdLmtThrshldConfigState 0;
BA_ "GenSigTimeoutTime_HU_High_X445" SG_ 471 OvrSpdLmtThrshldConfigState 0;
BA_ "GenSigTimeoutTime_HU_Mid_X445" SG_ 471 OvrSpdLmtThrshldConfigState 0;
BA_ "GenSigTimeoutMsg_IVI" SG_ 471 OvrSpdLmtThrshldConfigState 0;
BA_ "GenSigTimeoutTime_IVI" SG_ 471 OvrSpdLmtThrshldConfigState 0;
BA_ "GenSigTimeoutTime_HU_Mid_X451" SG_ 471 OvrSpdLmtWarnConfigState 0;
BA_ "GenSigTimeoutTime_HU_High_X451" SG_ 471 OvrSpdLmtWarnConfigState 0;
BA_ "GenSigTimeoutTime_HU_B" SG_ 471 OvrSpdLmtWarnConfigState 0;
BA_ "GenSigTimeoutTime_HU_A" SG_ 471 OvrSpdLmtWarnConfigState 0;
BA_ "GenSigTimeoutMsg_HU_Mid_X451" SG_ 471 OvrSpdLmtWarnConfigState 0;
BA_ "GenSigTimeoutMsg_HU_High_X451" SG_ 471 OvrSpdLmtWarnConfigState 0;
BA_ "GenSigTimeoutMsg_HU_B" SG_ 471 OvrSpdLmtWarnConfigState 0;
BA_ "GenSigTimeoutMsg_HU_A" SG_ 471 OvrSpdLmtWarnConfigState 0;
BA_ "GenSigSendType" SG_ 471 OvrSpdLmtWarnConfigState 2;
BA_ "GenSigTimeoutMsg_HU_High_X445" SG_ 471 OvrSpdLmtWarnConfigState 0;
BA_ "GenSigTimeoutMsg_HU_Mid_X445" SG_ 471 OvrSpdLmtWarnConfigState 0;
BA_ "GenSigTimeoutTime_HU_High_X445" SG_ 471 OvrSpdLmtWarnConfigState 0;
BA_ "GenSigTimeoutTime_HU_Mid_X445" SG_ 471 OvrSpdLmtWarnConfigState 0;
BA_ "GenSigTimeoutMsg_IVI" SG_ 471 OvrSpdLmtWarnConfigState 0;
BA_ "GenSigTimeoutTime_IVI" SG_ 471 OvrSpdLmtWarnConfigState 0;
BA_ "GenSigTimeoutTime_HU_Mid_X451" SG_ 471 IsaOnOffConfigState 0;
BA_ "GenSigTimeoutTime_HU_High_X451" SG_ 471 IsaOnOffConfigState 0;
BA_ "GenSigTimeoutTime_HU_B" SG_ 471 IsaOnOffConfigState 0;
BA_ "GenSigTimeoutTime_HU_A" SG_ 471 IsaOnOffConfigState 0;
BA_ "GenSigTimeoutMsg_HU_Mid_X451" SG_ 471 IsaOnOffConfigState 0;
BA_ "GenSigTimeoutMsg_HU_High_X451" SG_ 471 IsaOnOffConfigState 0;
BA_ "GenSigTimeoutMsg_HU_B" SG_ 471 IsaOnOffConfigState 0;
BA_ "GenSigTimeoutMsg_HU_A" SG_ 471 IsaOnOffConfigState 0;
BA_ "GenSigSendType" SG_ 471 IsaOnOffConfigState 2;
BA_ "GenSigTimeoutMsg_HU_High_X445" SG_ 471 IsaOnOffConfigState 0;
BA_ "GenSigTimeoutMsg_HU_Mid_X445" SG_ 471 IsaOnOffConfigState 0;
BA_ "GenSigTimeoutTime_HU_High_X445" SG_ 471 IsaOnOffConfigState 0;
BA_ "GenSigTimeoutTime_HU_Mid_X445" SG_ 471 IsaOnOffConfigState 0;
BA_ "GenSigTimeoutMsg_IVI" SG_ 471 IsaOnOffConfigState 0;
BA_ "GenSigTimeoutTime_IVI" SG_ 471 IsaOnOffConfigState 0;
BA_ "GenSigTimeoutTime_HU_Mid_X451" SG_ 471 TsrSignalApplicability 0;
BA_ "GenSigTimeoutTime_HU_High_X451" SG_ 471 TsrSignalApplicability 0;
BA_ "GenSigTimeoutTime_HU_B" SG_ 471 TsrSignalApplicability 0;
BA_ "GenSigTimeoutTime_HU_A" SG_ 471 TsrSignalApplicability 0;
BA_ "GenSigTimeoutMsg_HU_Mid_X451" SG_ 471 TsrSignalApplicability 0;
BA_ "GenSigTimeoutMsg_HU_High_X451" SG_ 471 TsrSignalApplicability 0;
BA_ "GenSigTimeoutMsg_HU_B" SG_ 471 TsrSignalApplicability 0;
BA_ "GenSigTimeoutMsg_HU_A" SG_ 471 TsrSignalApplicability 0;
BA_ "GenSigSendType" SG_ 471 TsrSignalApplicability 2;
BA_ "GenSigTimeoutMsg_HU_High_X445" SG_ 471 TsrSignalApplicability 0;
BA_ "GenSigTimeoutMsg_HU_Mid_X445" SG_ 471 TsrSignalApplicability 0;
BA_ "GenSigTimeoutTime_HU_High_X445" SG_ 471 TsrSignalApplicability 0;
BA_ "GenSigTimeoutTime_HU_Mid_X445" SG_ 471 TsrSignalApplicability 0;
BA_ "GenSigTimeoutMsg_IVI" SG_ 471 TsrSignalApplicability 0;
BA_ "GenSigTimeoutTime_IVI" SG_ 471 TsrSignalApplicability 0;
BA_ "GenSigTimeoutTime_HU_Mid_X451" SG_ 471 FcwAebSignalApplicability 0;
BA_ "GenSigTimeoutTime_HU_High_X451" SG_ 471 FcwAebSignalApplicability 0;
BA_ "GenSigTimeoutTime_HU_B" SG_ 471 FcwAebSignalApplicability 0;
BA_ "GenSigTimeoutTime_HU_A" SG_ 471 FcwAebSignalApplicability 0;
BA_ "GenSigTimeoutMsg_HU_Mid_X451" SG_ 471 FcwAebSignalApplicability 0;
BA_ "GenSigTimeoutMsg_HU_High_X451" SG_ 471 FcwAebSignalApplicability 0;
BA_ "GenSigTimeoutMsg_HU_B" SG_ 471 FcwAebSignalApplicability 0;
BA_ "GenSigTimeoutMsg_HU_A" SG_ 471 FcwAebSignalApplicability 0;
BA_ "GenSigSendType" SG_ 471 FcwAebSignalApplicability 2;
BA_ "GenSigTimeoutMsg_HU_High_X445" SG_ 471 FcwAebSignalApplicability 0;
BA_ "GenSigTimeoutMsg_HU_Mid_X445" SG_ 471 FcwAebSignalApplicability 0;
BA_ "GenSigTimeoutTime_HU_High_X445" SG_ 471 FcwAebSignalApplicability 0;
BA_ "GenSigTimeoutTime_HU_Mid_X445" SG_ 471 FcwAebSignalApplicability 0;
BA_ "GenSigTimeoutMsg_IVI" SG_ 471 FcwAebSignalApplicability 0;
BA_ "GenSigTimeoutTime_IVI" SG_ 471 FcwAebSignalApplicability 0;
BA_ "GenSigTimeoutTime_HU_Mid_X451" SG_ 471 LdwSignalApplicability 0;
BA_ "GenSigTimeoutTime_HU_High_X451" SG_ 471 LdwSignalApplicability 0;
BA_ "GenSigTimeoutTime_HU_B" SG_ 471 LdwSignalApplicability 0;
BA_ "GenSigTimeoutTime_HU_A" SG_ 471 LdwSignalApplicability 0;
BA_ "GenSigTimeoutMsg_HU_Mid_X451" SG_ 471 LdwSignalApplicability 0;
BA_ "GenSigTimeoutMsg_HU_High_X451" SG_ 471 LdwSignalApplicability 0;
BA_ "GenSigTimeoutMsg_HU_B" SG_ 471 LdwSignalApplicability 0;
BA_ "GenSigTimeoutMsg_HU_A" SG_ 471 LdwSignalApplicability 0;
BA_ "GenSigSendType" SG_ 471 LdwSignalApplicability 2;
BA_ "GenSigTimeoutMsg_HU_High_X445" SG_ 471 LdwSignalApplicability 0;
BA_ "GenSigTimeoutMsg_HU_Mid_X445" SG_ 471 LdwSignalApplicability 0;
BA_ "GenSigTimeoutTime_HU_High_X445" SG_ 471 LdwSignalApplicability 0;
BA_ "GenSigTimeoutTime_HU_Mid_X445" SG_ 471 LdwSignalApplicability 0;
BA_ "GenSigTimeoutMsg_IVI" SG_ 471 LdwSignalApplicability 0;
BA_ "GenSigTimeoutTime_IVI" SG_ 471 LdwSignalApplicability 0;
BA_ "GenSigTimeoutTime_HU_Mid_X451" SG_ 471 HbaSignalApplicability 0;
BA_ "GenSigTimeoutTime_HU_High_X451" SG_ 471 HbaSignalApplicability 0;
BA_ "GenSigTimeoutTime_HU_B" SG_ 471 HbaSignalApplicability 0;
BA_ "GenSigTimeoutTime_HU_A" SG_ 471 HbaSignalApplicability 0;
BA_ "GenSigTimeoutMsg_HU_Mid_X451" SG_ 471 HbaSignalApplicability 0;
BA_ "GenSigTimeoutMsg_HU_High_X451" SG_ 471 HbaSignalApplicability 0;
BA_ "GenSigTimeoutMsg_HU_B" SG_ 471 HbaSignalApplicability 0;
BA_ "GenSigTimeoutMsg_HU_A" SG_ 471 HbaSignalApplicability 0;
BA_ "GenSigSendType" SG_ 471 HbaSignalApplicability 2;
BA_ "GenSigTimeoutMsg_HU_High_X445" SG_ 471 HbaSignalApplicability 0;
BA_ "GenSigTimeoutMsg_HU_Mid_X445" SG_ 471 HbaSignalApplicability 0;
BA_ "GenSigTimeoutTime_HU_High_X445" SG_ 471 HbaSignalApplicability 0;
BA_ "GenSigTimeoutTime_HU_Mid_X445" SG_ 471 HbaSignalApplicability 0;
BA_ "GenSigTimeoutMsg_IVI" SG_ 471 HbaSignalApplicability 0;
BA_ "GenSigTimeoutTime_IVI" SG_ 471 HbaSignalApplicability 0;
BA_ "GenSigTimeoutTime_HU_Mid_X451" SG_ 471 FcwAebOnOffConfigStateValidity 0;
BA_ "GenSigTimeoutTime_HU_High_X451" SG_ 471 FcwAebOnOffConfigStateValidity 0;
BA_ "GenSigTimeoutTime_HU_B" SG_ 471 FcwAebOnOffConfigStateValidity 0;
BA_ "GenSigTimeoutTime_HU_A" SG_ 471 FcwAebOnOffConfigStateValidity 0;
BA_ "GenSigTimeoutMsg_HU_Mid_X451" SG_ 471 FcwAebOnOffConfigStateValidity 0;
BA_ "GenSigTimeoutMsg_HU_High_X451" SG_ 471 FcwAebOnOffConfigStateValidity 0;
BA_ "GenSigTimeoutMsg_HU_B" SG_ 471 FcwAebOnOffConfigStateValidity 0;
BA_ "GenSigTimeoutMsg_HU_A" SG_ 471 FcwAebOnOffConfigStateValidity 0;
BA_ "GenSigSendType" SG_ 471 FcwAebOnOffConfigStateValidity 2;
BA_ "GenSigTimeoutMsg_HU_High_X445" SG_ 471 FcwAebOnOffConfigStateValidity 0;
BA_ "GenSigTimeoutMsg_HU_Mid_X445" SG_ 471 FcwAebOnOffConfigStateValidity 0;
BA_ "GenSigTimeoutTime_HU_High_X445" SG_ 471 FcwAebOnOffConfigStateValidity 0;
BA_ "GenSigTimeoutTime_HU_Mid_X445" SG_ 471 FcwAebOnOffConfigStateValidity 0;
BA_ "GenSigTimeoutMsg_IVI" SG_ 471 FcwAebOnOffConfigStateValidity 0;
BA_ "GenSigTimeoutTime_IVI" SG_ 471 FcwAebOnOffConfigStateValidity 0;
BA_ "GenSigTimeoutTime_HU_Mid_X451" SG_ 471 FcwAebWarnSetConfigStateValidity 0;
BA_ "GenSigTimeoutTime_HU_High_X451" SG_ 471 FcwAebWarnSetConfigStateValidity 0;
BA_ "GenSigTimeoutTime_HU_B" SG_ 471 FcwAebWarnSetConfigStateValidity 0;
BA_ "GenSigTimeoutTime_HU_A" SG_ 471 FcwAebWarnSetConfigStateValidity 0;
BA_ "GenSigTimeoutMsg_HU_Mid_X451" SG_ 471 FcwAebWarnSetConfigStateValidity 0;
BA_ "GenSigTimeoutMsg_HU_High_X451" SG_ 471 FcwAebWarnSetConfigStateValidity 0;
BA_ "GenSigTimeoutMsg_HU_B" SG_ 471 FcwAebWarnSetConfigStateValidity 0;
BA_ "GenSigTimeoutMsg_HU_A" SG_ 471 FcwAebWarnSetConfigStateValidity 0;
BA_ "GenSigSendType" SG_ 471 FcwAebWarnSetConfigStateValidity 2;
BA_ "GenSigTimeoutMsg_HU_High_X445" SG_ 471 FcwAebWarnSetConfigStateValidity 0;
BA_ "GenSigTimeoutMsg_HU_Mid_X445" SG_ 471 FcwAebWarnSetConfigStateValidity 0;
BA_ "GenSigTimeoutTime_HU_High_X445" SG_ 471 FcwAebWarnSetConfigStateValidity 0;
BA_ "GenSigTimeoutTime_HU_Mid_X445" SG_ 471 FcwAebWarnSetConfigStateValidity 0;
BA_ "GenSigTimeoutMsg_IVI" SG_ 471 FcwAebWarnSetConfigStateValidity 0;
BA_ "GenSigTimeoutTime_IVI" SG_ 471 FcwAebWarnSetConfigStateValidity 0;
BA_ "GenSigTimeoutTime_HU_Mid_X451" SG_ 471 FcwAebWarnSetConfigState 0;
BA_ "GenSigTimeoutTime_HU_High_X451" SG_ 471 FcwAebWarnSetConfigState 0;
BA_ "GenSigTimeoutTime_HU_B" SG_ 471 FcwAebWarnSetConfigState 0;
BA_ "GenSigTimeoutTime_HU_A" SG_ 471 FcwAebWarnSetConfigState 0;
BA_ "GenSigTimeoutMsg_HU_Mid_X451" SG_ 471 FcwAebWarnSetConfigState 0;
BA_ "GenSigTimeoutMsg_HU_High_X451" SG_ 471 FcwAebWarnSetConfigState 0;
BA_ "GenSigTimeoutMsg_HU_B" SG_ 471 FcwAebWarnSetConfigState 0;
BA_ "GenSigTimeoutMsg_HU_A" SG_ 471 FcwAebWarnSetConfigState 0;
BA_ "GenSigSendType" SG_ 471 FcwAebWarnSetConfigState 2;
BA_ "GenSigTimeoutMsg_HU_High_X445" SG_ 471 FcwAebWarnSetConfigState 0;
BA_ "GenSigTimeoutMsg_HU_Mid_X445" SG_ 471 FcwAebWarnSetConfigState 0;
BA_ "GenSigTimeoutTime_HU_High_X445" SG_ 471 FcwAebWarnSetConfigState 0;
BA_ "GenSigTimeoutTime_HU_Mid_X445" SG_ 471 FcwAebWarnSetConfigState 0;
BA_ "GenSigTimeoutMsg_IVI" SG_ 471 FcwAebWarnSetConfigState 0;
BA_ "GenSigTimeoutTime_IVI" SG_ 471 FcwAebWarnSetConfigState 0;
BA_ "GenSigTimeoutTime_HU_Mid_X451" SG_ 471 TsrOnOffConfigState 0;
BA_ "GenSigTimeoutTime_HU_High_X451" SG_ 471 TsrOnOffConfigState 0;
BA_ "GenSigTimeoutTime_HU_B" SG_ 471 TsrOnOffConfigState 0;
BA_ "GenSigTimeoutTime_HU_A" SG_ 471 TsrOnOffConfigState 0;
BA_ "GenSigTimeoutMsg_HU_Mid_X451" SG_ 471 TsrOnOffConfigState 0;
BA_ "GenSigTimeoutMsg_HU_High_X451" SG_ 471 TsrOnOffConfigState 0;
BA_ "GenSigTimeoutMsg_HU_B" SG_ 471 TsrOnOffConfigState 0;
BA_ "GenSigTimeoutMsg_HU_A" SG_ 471 TsrOnOffConfigState 0;
BA_ "GenSigSendType" SG_ 471 TsrOnOffConfigState 2;
BA_ "GenSigTimeoutMsg_HU_High_X445" SG_ 471 TsrOnOffConfigState 0;
BA_ "GenSigTimeoutMsg_HU_Mid_X445" SG_ 471 TsrOnOffConfigState 0;
BA_ "GenSigTimeoutTime_HU_High_X445" SG_ 471 TsrOnOffConfigState 0;
BA_ "GenSigTimeoutTime_HU_Mid_X445" SG_ 471 TsrOnOffConfigState 0;
BA_ "GenSigTimeoutMsg_IVI" SG_ 471 TsrOnOffConfigState 0;
BA_ "GenSigTimeoutTime_IVI" SG_ 471 TsrOnOffConfigState 0;
BA_ "GenSigTimeoutTime_HU_Mid_X451" SG_ 471 LdwOnOffConfigState 0;
BA_ "GenSigTimeoutTime_HU_High_X451" SG_ 471 LdwOnOffConfigState 0;
BA_ "GenSigTimeoutTime_HU_B" SG_ 471 LdwOnOffConfigState 0;
BA_ "GenSigTimeoutTime_HU_A" SG_ 471 LdwOnOffConfigState 0;
BA_ "GenSigTimeoutMsg_HU_Mid_X451" SG_ 471 LdwOnOffConfigState 0;
BA_ "GenSigTimeoutMsg_HU_High_X451" SG_ 471 LdwOnOffConfigState 0;
BA_ "GenSigTimeoutMsg_HU_B" SG_ 471 LdwOnOffConfigState 0;
BA_ "GenSigTimeoutMsg_HU_A" SG_ 471 LdwOnOffConfigState 0;
BA_ "GenSigSendType" SG_ 471 LdwOnOffConfigState 2;
BA_ "GenSigTimeoutMsg_HU_High_X445" SG_ 471 LdwOnOffConfigState 0;
BA_ "GenSigTimeoutMsg_HU_Mid_X445" SG_ 471 LdwOnOffConfigState 0;
BA_ "GenSigTimeoutTime_HU_High_X445" SG_ 471 LdwOnOffConfigState 0;
BA_ "GenSigTimeoutTime_HU_Mid_X445" SG_ 471 LdwOnOffConfigState 0;
BA_ "GenSigTimeoutMsg_IVI" SG_ 471 LdwOnOffConfigState 0;
BA_ "GenSigTimeoutTime_IVI" SG_ 471 LdwOnOffConfigState 0;
BA_ "GenSigTimeoutTime_HU_Mid_X451" SG_ 471 HbaOnOffConfigState 0;
BA_ "GenSigTimeoutTime_HU_High_X451" SG_ 471 HbaOnOffConfigState 0;
BA_ "GenSigTimeoutTime_HU_B" SG_ 471 HbaOnOffConfigState 0;
BA_ "GenSigTimeoutTime_HU_A" SG_ 471 HbaOnOffConfigState 0;
BA_ "GenSigTimeoutMsg_HU_Mid_X451" SG_ 471 HbaOnOffConfigState 0;
BA_ "GenSigTimeoutMsg_HU_High_X451" SG_ 471 HbaOnOffConfigState 0;
BA_ "GenSigTimeoutMsg_HU_B" SG_ 471 HbaOnOffConfigState 0;
BA_ "GenSigTimeoutMsg_HU_A" SG_ 471 HbaOnOffConfigState 0;
BA_ "GenSigSendType" SG_ 471 HbaOnOffConfigState 2;
BA_ "GenSigTimeoutMsg_HU_High_X445" SG_ 471 HbaOnOffConfigState 0;
BA_ "GenSigTimeoutMsg_HU_Mid_X445" SG_ 471 HbaOnOffConfigState 0;
BA_ "GenSigTimeoutTime_HU_High_X445" SG_ 471 HbaOnOffConfigState 0;
BA_ "GenSigTimeoutTime_HU_Mid_X445" SG_ 471 HbaOnOffConfigState 0;
BA_ "GenSigTimeoutMsg_IVI" SG_ 471 HbaOnOffConfigState 0;
BA_ "GenSigTimeoutTime_IVI" SG_ 471 HbaOnOffConfigState 0;
BA_ "GenSigTimeoutTime_HU_Mid_X451" SG_ 471 FcwAebOnOffConfigState 0;
BA_ "GenSigTimeoutTime_HU_High_X451" SG_ 471 FcwAebOnOffConfigState 0;
BA_ "GenSigTimeoutTime_HU_B" SG_ 471 FcwAebOnOffConfigState 0;
BA_ "GenSigTimeoutTime_HU_A" SG_ 471 FcwAebOnOffConfigState 0;
BA_ "GenSigTimeoutMsg_HU_Mid_X451" SG_ 471 FcwAebOnOffConfigState 0;
BA_ "GenSigTimeoutMsg_HU_High_X451" SG_ 471 FcwAebOnOffConfigState 0;
BA_ "GenSigTimeoutMsg_HU_B" SG_ 471 FcwAebOnOffConfigState 0;
BA_ "GenSigTimeoutMsg_HU_A" SG_ 471 FcwAebOnOffConfigState 0;
BA_ "GenSigSendType" SG_ 471 FcwAebOnOffConfigState 2;
BA_ "GenSigTimeoutMsg_HU_High_X445" SG_ 471 FcwAebOnOffConfigState 0;
BA_ "GenSigTimeoutMsg_HU_Mid_X445" SG_ 471 FcwAebOnOffConfigState 0;
BA_ "GenSigTimeoutTime_HU_High_X445" SG_ 471 FcwAebOnOffConfigState 0;
BA_ "GenSigTimeoutTime_HU_Mid_X445" SG_ 471 FcwAebOnOffConfigState 0;
BA_ "GenSigTimeoutMsg_IVI" SG_ 471 FcwAebOnOffConfigState 0;
BA_ "GenSigTimeoutTime_IVI" SG_ 471 FcwAebOnOffConfigState 0;
BA_ "GenSigSendType" SG_ 592 LdwHapticWarningPresence 7;
BA_ "GenSigCycleTimeActive" SG_ 592 LdwHapticWarningPresence 100;
BA_ "GenSigCycleTime" SG_ 592 LdwHapticWarningPresence 100;
BA_ "GenSigSendType" SG_ 592 LkaPresence 7;
BA_ "GenSigCycleTimeActive" SG_ 592 LkaPresence 100;
BA_ "GenSigCycleTime" SG_ 592 LkaPresence 100;
BA_ "GenSigStartValue" SG_ 592 TsrOnOffState 1;
BA_ "GenSigSendType" SG_ 592 TsrOnOffState 7;
BA_ "GenSigCycleTimeActive" SG_ 592 TsrOnOffState 100;
BA_ "GenSigCycleTime" SG_ 592 TsrOnOffState 100;
BA_ "GenSigSendType" SG_ 592 HbaOnOffState 7;
BA_ "GenSigCycleTimeActive" SG_ 592 HbaOnOffState 100;
BA_ "GenSigCycleTime" SG_ 592 HbaOnOffState 100;
BA_ "GenSigStartValue" SG_ 592 LdwOnOffState 1;
BA_ "GenSigSendType" SG_ 592 LdwOnOffState 7;
BA_ "GenSigCycleTimeActive" SG_ 592 LdwOnOffState 100;
BA_ "GenSigCycleTime" SG_ 592 LdwOnOffState 100;
BA_ "GenSigSendType" SG_ 592 FcmPresence 7;
BA_ "GenSigCycleTimeActive" SG_ 592 FcmPresence 100;
BA_ "GenSigCycleTime" SG_ 592 FcmPresence 100;
BA_ "GenSigSendType" SG_ 384 MSG_CNT_20 7;
BA_ "GenSigCycleTimeActive" SG_ 384 MSG_CNT_20 20;
BA_ "GenSigCycleTime" SG_ 384 MSG_CNT_20 20;
BA_ "GenSigSendType" SG_ 384 CRC_20 7;
BA_ "GenSigCycleTimeActive" SG_ 384 CRC_20 20;
BA_ "GenSigCycleTime" SG_ 384 CRC_20 20;
BA_ "GenSigStartValue" SG_ 384 FcwAebOnOffState 1;
BA_ "GenSigSendType" SG_ 384 FcwAebOnOffState 7;
BA_ "GenSigCycleTimeActive" SG_ 384 FcwAebOnOffState 20;
BA_ "GenSigCycleTime" SG_ 384 FcwAebOnOffState 20;
BA_ "GenSigTimeoutTime_HU_Mid_X451" SG_ 473 LdwWarningSettingReq 0;
BA_ "GenSigTimeoutTime_HU_High_X451" SG_ 473 LdwWarningSettingReq 0;
BA_ "GenSigTimeoutTime_HU_B" SG_ 473 LdwWarningSettingReq 0;
BA_ "GenSigTimeoutTime_HU_A" SG_ 473 LdwWarningSettingReq 0;
BA_ "GenSigTimeoutMsg_HU_Mid_X451" SG_ 473 LdwWarningSettingReq 0;
BA_ "GenSigTimeoutMsg_HU_High_X451" SG_ 473 LdwWarningSettingReq 0;
BA_ "GenSigTimeoutMsg_HU_B" SG_ 473 LdwWarningSettingReq 0;
BA_ "GenSigTimeoutMsg_HU_A" SG_ 473 LdwWarningSettingReq 0;
BA_ "GenSigSendType" SG_ 473 LdwWarningSettingReq 2;
BA_ "GenSigTimeoutMsg_HU_High_X445" SG_ 473 LdwWarningSettingReq 0;
BA_ "GenSigTimeoutMsg_HU_Mid_X445" SG_ 473 LdwWarningSettingReq 0;
BA_ "GenSigTimeoutTime_HU_High_X445" SG_ 473 LdwWarningSettingReq 0;
BA_ "GenSigTimeoutTime_HU_Mid_X445" SG_ 473 LdwWarningSettingReq 0;
BA_ "GenSigTimeoutMsg_IVI" SG_ 473 LdwWarningSettingReq 0;
BA_ "GenSigTimeoutTime_IVI" SG_ 473 LdwWarningSettingReq 0;
BA_ "GenSigTimeoutTime_HU_Mid_X451" SG_ 473 LdwWarningSettingConfigAck 0;
BA_ "GenSigTimeoutTime_HU_High_X451" SG_ 473 LdwWarningSettingConfigAck 0;
BA_ "GenSigTimeoutTime_HU_B" SG_ 473 LdwWarningSettingConfigAck 0;
BA_ "GenSigTimeoutTime_HU_A" SG_ 473 LdwWarningSettingConfigAck 0;
BA_ "GenSigTimeoutMsg_HU_Mid_X451" SG_ 473 LdwWarningSettingConfigAck 0;
BA_ "GenSigTimeoutMsg_HU_High_X451" SG_ 473 LdwWarningSettingConfigAck 0;
BA_ "GenSigTimeoutMsg_HU_B" SG_ 473 LdwWarningSettingConfigAck 0;
BA_ "GenSigTimeoutMsg_HU_A" SG_ 473 LdwWarningSettingConfigAck 0;
BA_ "GenSigSendType" SG_ 473 LdwWarningSettingConfigAck 2;
BA_ "GenSigTimeoutMsg_HU_High_X445" SG_ 473 LdwWarningSettingConfigAck 0;
BA_ "GenSigTimeoutMsg_HU_Mid_X445" SG_ 473 LdwWarningSettingConfigAck 0;
BA_ "GenSigTimeoutTime_HU_High_X445" SG_ 473 LdwWarningSettingConfigAck 0;
BA_ "GenSigTimeoutTime_HU_Mid_X445" SG_ 473 LdwWarningSettingConfigAck 0;
BA_ "GenSigTimeoutMsg_IVI" SG_ 473 LdwWarningSettingConfigAck 0;
BA_ "GenSigTimeoutTime_IVI" SG_ 473 LdwWarningSettingConfigAck 0;
BA_ "GenSigTimeoutTime_HU_Mid_X451" SG_ 473 LdwHapticWarningStateReq 0;
BA_ "GenSigTimeoutTime_HU_High_X451" SG_ 473 LdwHapticWarningStateReq 0;
BA_ "GenSigTimeoutTime_HU_B" SG_ 473 LdwHapticWarningStateReq 0;
BA_ "GenSigTimeoutTime_HU_A" SG_ 473 LdwHapticWarningStateReq 0;
BA_ "GenSigTimeoutMsg_HU_Mid_X451" SG_ 473 LdwHapticWarningStateReq 0;
BA_ "GenSigTimeoutMsg_HU_High_X451" SG_ 473 LdwHapticWarningStateReq 0;
BA_ "GenSigTimeoutMsg_HU_B" SG_ 473 LdwHapticWarningStateReq 0;
BA_ "GenSigTimeoutMsg_HU_A" SG_ 473 LdwHapticWarningStateReq 0;
BA_ "GenSigSendType" SG_ 473 LdwHapticWarningStateReq 2;
BA_ "GenSigTimeoutMsg_HU_High_X445" SG_ 473 LdwHapticWarningStateReq 0;
BA_ "GenSigTimeoutMsg_HU_Mid_X445" SG_ 473 LdwHapticWarningStateReq 0;
BA_ "GenSigTimeoutTime_HU_High_X445" SG_ 473 LdwHapticWarningStateReq 0;
BA_ "GenSigTimeoutTime_HU_Mid_X445" SG_ 473 LdwHapticWarningStateReq 0;
BA_ "GenSigTimeoutMsg_IVI" SG_ 473 LdwHapticWarningStateReq 0;
BA_ "GenSigTimeoutTime_IVI" SG_ 473 LdwHapticWarningStateReq 0;
BA_ "GenSigTimeoutTime_HU_Mid_X451" SG_ 473 LdwHapticWarningConfigAck 0;
BA_ "GenSigTimeoutTime_HU_High_X451" SG_ 473 LdwHapticWarningConfigAck 0;
BA_ "GenSigTimeoutTime_HU_B" SG_ 473 LdwHapticWarningConfigAck 0;
BA_ "GenSigTimeoutTime_HU_A" SG_ 473 LdwHapticWarningConfigAck 0;
BA_ "GenSigTimeoutMsg_HU_Mid_X451" SG_ 473 LdwHapticWarningConfigAck 0;
BA_ "GenSigTimeoutMsg_HU_High_X451" SG_ 473 LdwHapticWarningConfigAck 0;
BA_ "GenSigTimeoutMsg_HU_B" SG_ 473 LdwHapticWarningConfigAck 0;
BA_ "GenSigTimeoutMsg_HU_A" SG_ 473 LdwHapticWarningConfigAck 0;
BA_ "GenSigSendType" SG_ 473 LdwHapticWarningConfigAck 2;
BA_ "GenSigTimeoutMsg_HU_High_X445" SG_ 473 LdwHapticWarningConfigAck 0;
BA_ "GenSigTimeoutMsg_HU_Mid_X445" SG_ 473 LdwHapticWarningConfigAck 0;
BA_ "GenSigTimeoutTime_HU_High_X445" SG_ 473 LdwHapticWarningConfigAck 0;
BA_ "GenSigTimeoutTime_HU_Mid_X445" SG_ 473 LdwHapticWarningConfigAck 0;
BA_ "GenSigTimeoutMsg_IVI" SG_ 473 LdwHapticWarningConfigAck 0;
BA_ "GenSigTimeoutTime_IVI" SG_ 473 LdwHapticWarningConfigAck 0;
BA_ "GenSigTimeoutTime_HU_Mid_X451" SG_ 473 LcsOnOffStateReq 0;
BA_ "GenSigTimeoutTime_HU_High_X451" SG_ 473 LcsOnOffStateReq 0;
BA_ "GenSigTimeoutTime_HU_B" SG_ 473 LcsOnOffStateReq 0;
BA_ "GenSigTimeoutTime_HU_A" SG_ 473 LcsOnOffStateReq 0;
BA_ "GenSigTimeoutMsg_HU_Mid_X451" SG_ 473 LcsOnOffStateReq 0;
BA_ "GenSigTimeoutMsg_HU_High_X451" SG_ 473 LcsOnOffStateReq 0;
BA_ "GenSigTimeoutMsg_HU_B" SG_ 473 LcsOnOffStateReq 0;
BA_ "GenSigTimeoutMsg_HU_A" SG_ 473 LcsOnOffStateReq 0;
BA_ "GenSigSendType" SG_ 473 LcsOnOffStateReq 2;
BA_ "GenSigTimeoutMsg_HU_High_X445" SG_ 473 LcsOnOffStateReq 0;
BA_ "GenSigTimeoutMsg_HU_Mid_X445" SG_ 473 LcsOnOffStateReq 0;
BA_ "GenSigTimeoutTime_HU_High_X445" SG_ 473 LcsOnOffStateReq 0;
BA_ "GenSigTimeoutTime_HU_Mid_X445" SG_ 473 LcsOnOffStateReq 0;
BA_ "GenSigTimeoutMsg_IVI" SG_ 473 LcsOnOffStateReq 0;
BA_ "GenSigTimeoutTime_IVI" SG_ 473 LcsOnOffStateReq 0;
BA_ "GenSigTimeoutTime_HU_Mid_X451" SG_ 473 LcsOnOffStateAck 0;
BA_ "GenSigTimeoutTime_HU_High_X451" SG_ 473 LcsOnOffStateAck 0;
BA_ "GenSigTimeoutTime_HU_B" SG_ 473 LcsOnOffStateAck 0;
BA_ "GenSigTimeoutTime_HU_A" SG_ 473 LcsOnOffStateAck 0;
BA_ "GenSigTimeoutMsg_HU_Mid_X451" SG_ 473 LcsOnOffStateAck 0;
BA_ "GenSigTimeoutMsg_HU_High_X451" SG_ 473 LcsOnOffStateAck 0;
BA_ "GenSigTimeoutMsg_HU_B" SG_ 473 LcsOnOffStateAck 0;
BA_ "GenSigTimeoutMsg_HU_A" SG_ 473 LcsOnOffStateAck 0;
BA_ "GenSigSendType" SG_ 473 LcsOnOffStateAck 2;
BA_ "GenSigTimeoutMsg_HU_High_X445" SG_ 473 LcsOnOffStateAck 0;
BA_ "GenSigTimeoutMsg_HU_Mid_X445" SG_ 473 LcsOnOffStateAck 0;
BA_ "GenSigTimeoutTime_HU_High_X445" SG_ 473 LcsOnOffStateAck 0;
BA_ "GenSigTimeoutTime_HU_Mid_X445" SG_ 473 LcsOnOffStateAck 0;
BA_ "GenSigTimeoutMsg_IVI" SG_ 473 LcsOnOffStateAck 0;
BA_ "GenSigTimeoutTime_IVI" SG_ 473 LcsOnOffStateAck 0;
BA_ "GenSigTimeoutTime_HU_Mid_X451" SG_ 473 LcsReqType 0;
BA_ "GenSigTimeoutTime_HU_High_X451" SG_ 473 LcsReqType 0;
BA_ "GenSigTimeoutTime_HU_B" SG_ 473 LcsReqType 0;
BA_ "GenSigTimeoutTime_HU_A" SG_ 473 LcsReqType 0;
BA_ "GenSigTimeoutMsg_HU_Mid_X451" SG_ 473 LcsReqType 0;
BA_ "GenSigTimeoutMsg_HU_High_X451" SG_ 473 LcsReqType 0;
BA_ "GenSigTimeoutMsg_HU_B" SG_ 473 LcsReqType 0;
BA_ "GenSigTimeoutMsg_HU_A" SG_ 473 LcsReqType 0;
BA_ "GenSigSendType" SG_ 473 LcsReqType 2;
BA_ "GenSigTimeoutMsg_HU_High_X445" SG_ 473 LcsReqType 0;
BA_ "GenSigTimeoutMsg_HU_Mid_X445" SG_ 473 LcsReqType 0;
BA_ "GenSigTimeoutTime_HU_High_X445" SG_ 473 LcsReqType 0;
BA_ "GenSigTimeoutTime_HU_Mid_X445" SG_ 473 LcsReqType 0;
BA_ "GenSigTimeoutMsg_IVI" SG_ 473 LcsReqType 0;
BA_ "GenSigTimeoutTime_IVI" SG_ 473 LcsReqType 0;
BA_ "GenSigTimeoutTime_HU_Mid_X451" SG_ 473 HuPepsMrrProximityUnfoldSelReq 0;
BA_ "GenSigTimeoutTime_HU_High_X451" SG_ 473 HuPepsMrrProximityUnfoldSelReq 0;
BA_ "GenSigTimeoutTime_HU_B" SG_ 473 HuPepsMrrProximityUnfoldSelReq 0;
BA_ "GenSigTimeoutTime_HU_A" SG_ 473 HuPepsMrrProximityUnfoldSelReq 0;
BA_ "GenSigTimeoutMsg_HU_Mid_X451" SG_ 473 HuPepsMrrProximityUnfoldSelReq 0;
BA_ "GenSigTimeoutMsg_HU_High_X451" SG_ 473 HuPepsMrrProximityUnfoldSelReq 0;
BA_ "GenSigTimeoutMsg_HU_B" SG_ 473 HuPepsMrrProximityUnfoldSelReq 0;
BA_ "GenSigTimeoutMsg_HU_A" SG_ 473 HuPepsMrrProximityUnfoldSelReq 0;
BA_ "GenSigSendType" SG_ 473 HuPepsMrrProximityUnfoldSelReq 2;
BA_ "GenSigTimeoutMsg_HU_High_X445" SG_ 473 HuPepsMrrProximityUnfoldSelReq 0;
BA_ "GenSigTimeoutMsg_HU_Mid_X445" SG_ 473 HuPepsMrrProximityUnfoldSelReq 0;
BA_ "GenSigTimeoutTime_HU_High_X445" SG_ 473 HuPepsMrrProximityUnfoldSelReq 0;
BA_ "GenSigTimeoutTime_HU_Mid_X445" SG_ 473 HuPepsMrrProximityUnfoldSelReq 0;
BA_ "GenSigTimeoutMsg_IVI" SG_ 473 HuPepsMrrProximityUnfoldSelReq 0;
BA_ "GenSigTimeoutTime_IVI" SG_ 473 HuPepsMrrProximityUnfoldSelReq 0;
BA_ "GenSigTimeoutTime_HU_Mid_X451" SG_ 473 HuVCuReqType 0;
BA_ "GenSigTimeoutTime_HU_High_X451" SG_ 473 HuVCuReqType 0;
BA_ "GenSigTimeoutTime_HU_B" SG_ 473 HuVCuReqType 0;
BA_ "GenSigTimeoutTime_HU_A" SG_ 473 HuVCuReqType 0;
BA_ "GenSigTimeoutMsg_HU_Mid_X451" SG_ 473 HuVCuReqType 0;
BA_ "GenSigTimeoutMsg_HU_High_X451" SG_ 473 HuVCuReqType 0;
BA_ "GenSigTimeoutMsg_HU_B" SG_ 473 HuVCuReqType 0;
BA_ "GenSigTimeoutMsg_HU_A" SG_ 473 HuVCuReqType 0;
BA_ "GenSigSendType" SG_ 473 HuVCuReqType 2;
BA_ "GenSigTimeoutMsg_HU_High_X445" SG_ 473 HuVCuReqType 0;
BA_ "GenSigTimeoutMsg_HU_Mid_X445" SG_ 473 HuVCuReqType 0;
BA_ "GenSigTimeoutTime_HU_High_X445" SG_ 473 HuVCuReqType 0;
BA_ "GenSigTimeoutTime_HU_Mid_X445" SG_ 473 HuVCuReqType 0;
BA_ "GenSigTimeoutMsg_IVI" SG_ 473 HuVCuReqType 0;
BA_ "GenSigTimeoutTime_IVI" SG_ 473 HuVCuReqType 0;
BA_ "GenSigTimeoutTime_HU_Mid_X451" SG_ 473 HuVCuChargeLimitValue 0;
BA_ "GenSigTimeoutTime_HU_High_X451" SG_ 473 HuVCuChargeLimitValue 0;
BA_ "GenSigTimeoutTime_HU_B" SG_ 473 HuVCuChargeLimitValue 0;
BA_ "GenSigTimeoutTime_HU_A" SG_ 473 HuVCuChargeLimitValue 0;
BA_ "GenSigTimeoutMsg_HU_Mid_X451" SG_ 473 HuVCuChargeLimitValue 0;
BA_ "GenSigTimeoutMsg_HU_High_X451" SG_ 473 HuVCuChargeLimitValue 0;
BA_ "GenSigTimeoutMsg_HU_B" SG_ 473 HuVCuChargeLimitValue 0;
BA_ "GenSigTimeoutMsg_HU_A" SG_ 473 HuVCuChargeLimitValue 0;
BA_ "GenSigSendType" SG_ 473 HuVCuChargeLimitValue 2;
BA_ "GenSigTimeoutMsg_HU_High_X445" SG_ 473 HuVCuChargeLimitValue 0;
BA_ "GenSigTimeoutMsg_HU_Mid_X445" SG_ 473 HuVCuChargeLimitValue 0;
BA_ "GenSigTimeoutTime_HU_High_X445" SG_ 473 HuVCuChargeLimitValue 0;
BA_ "GenSigTimeoutTime_HU_Mid_X445" SG_ 473 HuVCuChargeLimitValue 0;
BA_ "GenSigTimeoutMsg_IVI" SG_ 473 HuVCuChargeLimitValue 0;
BA_ "GenSigTimeoutTime_IVI" SG_ 473 HuVCuChargeLimitValue 0;
BA_ "GenSigTimeoutTime_HU_Mid_X451" SG_ 473 HuCplSclTimerSettingUpdate 0;
BA_ "GenSigTimeoutTime_HU_High_X451" SG_ 473 HuCplSclTimerSettingUpdate 0;
BA_ "GenSigTimeoutTime_HU_B" SG_ 473 HuCplSclTimerSettingUpdate 0;
BA_ "GenSigTimeoutTime_HU_A" SG_ 473 HuCplSclTimerSettingUpdate 0;
BA_ "GenSigTimeoutMsg_HU_Mid_X451" SG_ 473 HuCplSclTimerSettingUpdate 0;
BA_ "GenSigTimeoutMsg_HU_High_X451" SG_ 473 HuCplSclTimerSettingUpdate 0;
BA_ "GenSigTimeoutMsg_HU_B" SG_ 473 HuCplSclTimerSettingUpdate 0;
BA_ "GenSigTimeoutMsg_HU_A" SG_ 473 HuCplSclTimerSettingUpdate 0;
BA_ "GenSigSendType" SG_ 473 HuCplSclTimerSettingUpdate 2;
BA_ "GenSigTimeoutMsg_HU_High_X445" SG_ 473 HuCplSclTimerSettingUpdate 0;
BA_ "GenSigTimeoutMsg_HU_Mid_X445" SG_ 473 HuCplSclTimerSettingUpdate 0;
BA_ "GenSigTimeoutTime_HU_High_X445" SG_ 473 HuCplSclTimerSettingUpdate 0;
BA_ "GenSigTimeoutTime_HU_Mid_X445" SG_ 473 HuCplSclTimerSettingUpdate 0;
BA_ "GenSigTimeoutMsg_IVI" SG_ 473 HuCplSclTimerSettingUpdate 0;
BA_ "GenSigTimeoutTime_IVI" SG_ 473 HuCplSclTimerSettingUpdate 0;
BA_ "GenSigTimeoutTime_HU_Mid_X451" SG_ 473 HuCplSclOnOffSettingUpdate 0;
BA_ "GenSigTimeoutTime_HU_High_X451" SG_ 473 HuCplSclOnOffSettingUpdate 0;
BA_ "GenSigTimeoutTime_HU_B" SG_ 473 HuCplSclOnOffSettingUpdate 0;
BA_ "GenSigTimeoutTime_HU_A" SG_ 473 HuCplSclOnOffSettingUpdate 0;
BA_ "GenSigTimeoutMsg_HU_Mid_X451" SG_ 473 HuCplSclOnOffSettingUpdate 0;
BA_ "GenSigTimeoutMsg_HU_High_X451" SG_ 473 HuCplSclOnOffSettingUpdate 0;
BA_ "GenSigTimeoutMsg_HU_B" SG_ 473 HuCplSclOnOffSettingUpdate 0;
BA_ "GenSigTimeoutMsg_HU_A" SG_ 473 HuCplSclOnOffSettingUpdate 0;
BA_ "GenSigSendType" SG_ 473 HuCplSclOnOffSettingUpdate 2;
BA_ "GenSigTimeoutMsg_HU_High_X445" SG_ 473 HuCplSclOnOffSettingUpdate 0;
BA_ "GenSigTimeoutMsg_HU_Mid_X445" SG_ 473 HuCplSclOnOffSettingUpdate 0;
BA_ "GenSigTimeoutTime_HU_High_X445" SG_ 473 HuCplSclOnOffSettingUpdate 0;
BA_ "GenSigTimeoutTime_HU_Mid_X445" SG_ 473 HuCplSclOnOffSettingUpdate 0;
BA_ "GenSigTimeoutMsg_IVI" SG_ 473 HuCplSclOnOffSettingUpdate 0;
BA_ "GenSigTimeoutTime_IVI" SG_ 473 HuCplSclOnOffSettingUpdate 0;
BA_ "GenSigTimeoutTime_HU_Mid_X451" SG_ 473 HuCplReqType 0;
BA_ "GenSigTimeoutTime_HU_High_X451" SG_ 473 HuCplReqType 0;
BA_ "GenSigTimeoutTime_HU_B" SG_ 473 HuCplReqType 0;
BA_ "GenSigTimeoutTime_HU_A" SG_ 473 HuCplReqType 0;
BA_ "GenSigTimeoutMsg_HU_Mid_X451" SG_ 473 HuCplReqType 0;
BA_ "GenSigTimeoutMsg_HU_High_X451" SG_ 473 HuCplReqType 0;
BA_ "GenSigTimeoutMsg_HU_B" SG_ 473 HuCplReqType 0;
BA_ "GenSigTimeoutMsg_HU_A" SG_ 473 HuCplReqType 0;
BA_ "GenSigSendType" SG_ 473 HuCplReqType 2;
BA_ "GenSigTimeoutMsg_HU_High_X445" SG_ 473 HuCplReqType 0;
BA_ "GenSigTimeoutMsg_HU_Mid_X445" SG_ 473 HuCplReqType 0;
BA_ "GenSigTimeoutTime_HU_High_X445" SG_ 473 HuCplReqType 0;
BA_ "GenSigTimeoutTime_HU_Mid_X445" SG_ 473 HuCplReqType 0;
BA_ "GenSigTimeoutMsg_IVI" SG_ 473 HuCplReqType 0;
BA_ "GenSigTimeoutTime_IVI" SG_ 473 HuCplReqType 0;
BA_ "GenSigTimeoutTime_HU_Mid_X451" SG_ 473 AsaOnOffStateReq 0;
BA_ "GenSigTimeoutTime_HU_High_X451" SG_ 473 AsaOnOffStateReq 0;
BA_ "GenSigTimeoutTime_HU_B" SG_ 473 AsaOnOffStateReq 0;
BA_ "GenSigTimeoutTime_HU_A" SG_ 473 AsaOnOffStateReq 0;
BA_ "GenSigTimeoutMsg_HU_Mid_X451" SG_ 473 AsaOnOffStateReq 0;
BA_ "GenSigTimeoutMsg_HU_High_X451" SG_ 473 AsaOnOffStateReq 0;
BA_ "GenSigTimeoutMsg_HU_B" SG_ 473 AsaOnOffStateReq 0;
BA_ "GenSigTimeoutMsg_HU_A" SG_ 473 AsaOnOffStateReq 0;
BA_ "GenSigSendType" SG_ 473 AsaOnOffStateReq 2;
BA_ "GenSigTimeoutMsg_HU_High_X445" SG_ 473 AsaOnOffStateReq 0;
BA_ "GenSigTimeoutMsg_HU_Mid_X445" SG_ 473 AsaOnOffStateReq 0;
BA_ "GenSigTimeoutTime_HU_High_X445" SG_ 473 AsaOnOffStateReq 0;
BA_ "GenSigTimeoutTime_HU_Mid_X445" SG_ 473 AsaOnOffStateReq 0;
BA_ "GenSigTimeoutMsg_IVI" SG_ 473 AsaOnOffStateReq 0;
BA_ "GenSigTimeoutTime_IVI" SG_ 473 AsaOnOffStateReq 0;
BA_ "GenSigTimeoutTime_HU_Mid_X451" SG_ 473 AsaOnOffStateAck 0;
BA_ "GenSigTimeoutTime_HU_High_X451" SG_ 473 AsaOnOffStateAck 0;
BA_ "GenSigTimeoutTime_HU_B" SG_ 473 AsaOnOffStateAck 0;
BA_ "GenSigTimeoutTime_HU_A" SG_ 473 AsaOnOffStateAck 0;
BA_ "GenSigTimeoutMsg_HU_Mid_X451" SG_ 473 AsaOnOffStateAck 0;
BA_ "GenSigTimeoutMsg_HU_High_X451" SG_ 473 AsaOnOffStateAck 0;
BA_ "GenSigTimeoutMsg_HU_B" SG_ 473 AsaOnOffStateAck 0;
BA_ "GenSigTimeoutMsg_HU_A" SG_ 473 AsaOnOffStateAck 0;
BA_ "GenSigSendType" SG_ 473 AsaOnOffStateAck 2;
BA_ "GenSigTimeoutMsg_HU_High_X445" SG_ 473 AsaOnOffStateAck 0;
BA_ "GenSigTimeoutMsg_HU_Mid_X445" SG_ 473 AsaOnOffStateAck 0;
BA_ "GenSigTimeoutTime_HU_High_X445" SG_ 473 AsaOnOffStateAck 0;
BA_ "GenSigTimeoutTime_HU_Mid_X445" SG_ 473 AsaOnOffStateAck 0;
BA_ "GenSigTimeoutMsg_IVI" SG_ 473 AsaOnOffStateAck 0;
BA_ "GenSigTimeoutTime_IVI" SG_ 473 AsaOnOffStateAck 0;
BA_ "GenSigTimeoutTime_HU_Mid_X451" SG_ 473 AsaReqType 0;
BA_ "GenSigTimeoutTime_HU_High_X451" SG_ 473 AsaReqType 0;
BA_ "GenSigTimeoutTime_HU_B" SG_ 473 AsaReqType 0;
BA_ "GenSigTimeoutTime_HU_A" SG_ 473 AsaReqType 0;
BA_ "GenSigTimeoutMsg_HU_Mid_X451" SG_ 473 AsaReqType 0;
BA_ "GenSigTimeoutMsg_HU_High_X451" SG_ 473 AsaReqType 0;
BA_ "GenSigTimeoutMsg_HU_B" SG_ 473 AsaReqType 0;
BA_ "GenSigTimeoutMsg_HU_A" SG_ 473 AsaReqType 0;
BA_ "GenSigSendType" SG_ 473 AsaReqType 2;
BA_ "GenSigTimeoutMsg_HU_High_X445" SG_ 473 AsaReqType 0;
BA_ "GenSigTimeoutMsg_HU_Mid_X445" SG_ 473 AsaReqType 0;
BA_ "GenSigTimeoutTime_HU_High_X445" SG_ 473 AsaReqType 0;
BA_ "GenSigTimeoutTime_HU_Mid_X445" SG_ 473 AsaReqType 0;
BA_ "GenSigTimeoutMsg_IVI" SG_ 473 AsaReqType 0;
BA_ "GenSigTimeoutTime_IVI" SG_ 473 AsaReqType 0;
BA_ "GenSigTimeoutTime_HU_Mid_X451" SG_ 473 OvrSpdLmtThrshldStateReq 0;
BA_ "GenSigTimeoutTime_HU_High_X451" SG_ 473 OvrSpdLmtThrshldStateReq 0;
BA_ "GenSigTimeoutTime_HU_B" SG_ 473 OvrSpdLmtThrshldStateReq 0;
BA_ "GenSigTimeoutTime_HU_A" SG_ 473 OvrSpdLmtThrshldStateReq 0;
BA_ "GenSigTimeoutMsg_HU_Mid_X451" SG_ 473 OvrSpdLmtThrshldStateReq 0;
BA_ "GenSigTimeoutMsg_HU_High_X451" SG_ 473 OvrSpdLmtThrshldStateReq 0;
BA_ "GenSigTimeoutMsg_HU_B" SG_ 473 OvrSpdLmtThrshldStateReq 0;
BA_ "GenSigTimeoutMsg_HU_A" SG_ 473 OvrSpdLmtThrshldStateReq 0;
BA_ "GenSigSendType" SG_ 473 OvrSpdLmtThrshldStateReq 2;
BA_ "GenSigTimeoutMsg_HU_High_X445" SG_ 473 OvrSpdLmtThrshldStateReq 0;
BA_ "GenSigTimeoutMsg_HU_Mid_X445" SG_ 473 OvrSpdLmtThrshldStateReq 0;
BA_ "GenSigTimeoutTime_HU_High_X445" SG_ 473 OvrSpdLmtThrshldStateReq 0;
BA_ "GenSigTimeoutTime_HU_Mid_X445" SG_ 473 OvrSpdLmtThrshldStateReq 0;
BA_ "GenSigTimeoutMsg_IVI" SG_ 473 OvrSpdLmtThrshldStateReq 0;
BA_ "GenSigTimeoutTime_IVI" SG_ 473 OvrSpdLmtThrshldStateReq 0;
BA_ "GenSigTimeoutTime_HU_Mid_X451" SG_ 473 OvrSpdLmtThrshldStateAck 0;
BA_ "GenSigTimeoutTime_HU_High_X451" SG_ 473 OvrSpdLmtThrshldStateAck 0;
BA_ "GenSigTimeoutTime_HU_B" SG_ 473 OvrSpdLmtThrshldStateAck 0;
BA_ "GenSigTimeoutTime_HU_A" SG_ 473 OvrSpdLmtThrshldStateAck 0;
BA_ "GenSigTimeoutMsg_HU_Mid_X451" SG_ 473 OvrSpdLmtThrshldStateAck 0;
BA_ "GenSigTimeoutMsg_HU_High_X451" SG_ 473 OvrSpdLmtThrshldStateAck 0;
BA_ "GenSigTimeoutMsg_HU_B" SG_ 473 OvrSpdLmtThrshldStateAck 0;
BA_ "GenSigTimeoutMsg_HU_A" SG_ 473 OvrSpdLmtThrshldStateAck 0;
BA_ "GenSigSendType" SG_ 473 OvrSpdLmtThrshldStateAck 2;
BA_ "GenSigTimeoutMsg_HU_High_X445" SG_ 473 OvrSpdLmtThrshldStateAck 0;
BA_ "GenSigTimeoutMsg_HU_Mid_X445" SG_ 473 OvrSpdLmtThrshldStateAck 0;
BA_ "GenSigTimeoutTime_HU_High_X445" SG_ 473 OvrSpdLmtThrshldStateAck 0;
BA_ "GenSigTimeoutTime_HU_Mid_X445" SG_ 473 OvrSpdLmtThrshldStateAck 0;
BA_ "GenSigTimeoutMsg_IVI" SG_ 473 OvrSpdLmtThrshldStateAck 0;
BA_ "GenSigTimeoutTime_IVI" SG_ 473 OvrSpdLmtThrshldStateAck 0;
BA_ "GenSigTimeoutTime_HU_Mid_X451" SG_ 473 OvrSpdLmtWarnStateReq 0;
BA_ "GenSigTimeoutTime_HU_High_X451" SG_ 473 OvrSpdLmtWarnStateReq 0;
BA_ "GenSigTimeoutTime_HU_B" SG_ 473 OvrSpdLmtWarnStateReq 0;
BA_ "GenSigTimeoutTime_HU_A" SG_ 473 OvrSpdLmtWarnStateReq 0;
BA_ "GenSigTimeoutMsg_HU_Mid_X451" SG_ 473 OvrSpdLmtWarnStateReq 0;
BA_ "GenSigTimeoutMsg_HU_High_X451" SG_ 473 OvrSpdLmtWarnStateReq 0;
BA_ "GenSigTimeoutMsg_HU_B" SG_ 473 OvrSpdLmtWarnStateReq 0;
BA_ "GenSigTimeoutMsg_HU_A" SG_ 473 OvrSpdLmtWarnStateReq 0;
BA_ "GenSigSendType" SG_ 473 OvrSpdLmtWarnStateReq 2;
BA_ "GenSigTimeoutMsg_HU_High_X445" SG_ 473 OvrSpdLmtWarnStateReq 0;
BA_ "GenSigTimeoutMsg_HU_Mid_X445" SG_ 473 OvrSpdLmtWarnStateReq 0;
BA_ "GenSigTimeoutTime_HU_High_X445" SG_ 473 OvrSpdLmtWarnStateReq 0;
BA_ "GenSigTimeoutTime_HU_Mid_X445" SG_ 473 OvrSpdLmtWarnStateReq 0;
BA_ "GenSigTimeoutMsg_IVI" SG_ 473 OvrSpdLmtWarnStateReq 0;
BA_ "GenSigTimeoutTime_IVI" SG_ 473 OvrSpdLmtWarnStateReq 0;
BA_ "GenSigTimeoutTime_HU_Mid_X451" SG_ 473 OvrSpdLmtWarnStateAck 0;
BA_ "GenSigTimeoutTime_HU_High_X451" SG_ 473 OvrSpdLmtWarnStateAck 0;
BA_ "GenSigTimeoutTime_HU_B" SG_ 473 OvrSpdLmtWarnStateAck 0;
BA_ "GenSigTimeoutTime_HU_A" SG_ 473 OvrSpdLmtWarnStateAck 0;
BA_ "GenSigTimeoutMsg_HU_Mid_X451" SG_ 473 OvrSpdLmtWarnStateAck 0;
BA_ "GenSigTimeoutMsg_HU_High_X451" SG_ 473 OvrSpdLmtWarnStateAck 0;
BA_ "GenSigTimeoutMsg_HU_B" SG_ 473 OvrSpdLmtWarnStateAck 0;
BA_ "GenSigTimeoutMsg_HU_A" SG_ 473 OvrSpdLmtWarnStateAck 0;
BA_ "GenSigSendType" SG_ 473 OvrSpdLmtWarnStateAck 2;
BA_ "GenSigTimeoutMsg_HU_High_X445" SG_ 473 OvrSpdLmtWarnStateAck 0;
BA_ "GenSigTimeoutMsg_HU_Mid_X445" SG_ 473 OvrSpdLmtWarnStateAck 0;
BA_ "GenSigTimeoutTime_HU_High_X445" SG_ 473 OvrSpdLmtWarnStateAck 0;
BA_ "GenSigTimeoutTime_HU_Mid_X445" SG_ 473 OvrSpdLmtWarnStateAck 0;
BA_ "GenSigTimeoutMsg_IVI" SG_ 473 OvrSpdLmtWarnStateAck 0;
BA_ "GenSigTimeoutTime_IVI" SG_ 473 OvrSpdLmtWarnStateAck 0;
BA_ "GenSigTimeoutTime_HU_Mid_X451" SG_ 473 IsaOnOffStateReq 0;
BA_ "GenSigTimeoutTime_HU_High_X451" SG_ 473 IsaOnOffStateReq 0;
BA_ "GenSigTimeoutTime_HU_B" SG_ 473 IsaOnOffStateReq 0;
BA_ "GenSigTimeoutTime_HU_A" SG_ 473 IsaOnOffStateReq 0;
BA_ "GenSigTimeoutMsg_HU_Mid_X451" SG_ 473 IsaOnOffStateReq 0;
BA_ "GenSigTimeoutMsg_HU_High_X451" SG_ 473 IsaOnOffStateReq 0;
BA_ "GenSigTimeoutMsg_HU_B" SG_ 473 IsaOnOffStateReq 0;
BA_ "GenSigTimeoutMsg_HU_A" SG_ 473 IsaOnOffStateReq 0;
BA_ "GenSigSendType" SG_ 473 IsaOnOffStateReq 2;
BA_ "GenSigTimeoutMsg_HU_High_X445" SG_ 473 IsaOnOffStateReq 0;
BA_ "GenSigTimeoutMsg_HU_Mid_X445" SG_ 473 IsaOnOffStateReq 0;
BA_ "GenSigTimeoutTime_HU_High_X445" SG_ 473 IsaOnOffStateReq 0;
BA_ "GenSigTimeoutTime_HU_Mid_X445" SG_ 473 IsaOnOffStateReq 0;
BA_ "GenSigTimeoutMsg_IVI" SG_ 473 IsaOnOffStateReq 0;
BA_ "GenSigTimeoutTime_IVI" SG_ 473 IsaOnOffStateReq 0;
BA_ "GenSigTimeoutTime_HU_Mid_X451" SG_ 473 IsaOnOffStateAck 0;
BA_ "GenSigTimeoutTime_HU_High_X451" SG_ 473 IsaOnOffStateAck 0;
BA_ "GenSigTimeoutTime_HU_B" SG_ 473 IsaOnOffStateAck 0;
BA_ "GenSigTimeoutTime_HU_A" SG_ 473 IsaOnOffStateAck 0;
BA_ "GenSigTimeoutMsg_HU_Mid_X451" SG_ 473 IsaOnOffStateAck 0;
BA_ "GenSigTimeoutMsg_HU_High_X451" SG_ 473 IsaOnOffStateAck 0;
BA_ "GenSigTimeoutMsg_HU_B" SG_ 473 IsaOnOffStateAck 0;
BA_ "GenSigTimeoutMsg_HU_A" SG_ 473 IsaOnOffStateAck 0;
BA_ "GenSigSendType" SG_ 473 IsaOnOffStateAck 2;
BA_ "GenSigTimeoutMsg_HU_High_X445" SG_ 473 IsaOnOffStateAck 0;
BA_ "GenSigTimeoutMsg_HU_Mid_X445" SG_ 473 IsaOnOffStateAck 0;
BA_ "GenSigTimeoutTime_HU_High_X445" SG_ 473 IsaOnOffStateAck 0;
BA_ "GenSigTimeoutTime_HU_Mid_X445" SG_ 473 IsaOnOffStateAck 0;
BA_ "GenSigTimeoutMsg_IVI" SG_ 473 IsaOnOffStateAck 0;
BA_ "GenSigTimeoutTime_IVI" SG_ 473 IsaOnOffStateAck 0;
BA_ "GenSigTimeoutTime_HU_Mid_X451" SG_ 473 HuBCmMrrAutoUnfoldSelReq 0;
BA_ "GenSigTimeoutTime_HU_High_X451" SG_ 473 HuBCmMrrAutoUnfoldSelReq 0;
BA_ "GenSigTimeoutTime_HU_B" SG_ 473 HuBCmMrrAutoUnfoldSelReq 0;
BA_ "GenSigTimeoutTime_HU_A" SG_ 473 HuBCmMrrAutoUnfoldSelReq 0;
BA_ "GenSigTimeoutMsg_HU_Mid_X451" SG_ 473 HuBCmMrrAutoUnfoldSelReq 0;
BA_ "GenSigTimeoutMsg_HU_High_X451" SG_ 473 HuBCmMrrAutoUnfoldSelReq 0;
BA_ "GenSigTimeoutMsg_HU_B" SG_ 473 HuBCmMrrAutoUnfoldSelReq 0;
BA_ "GenSigTimeoutMsg_HU_A" SG_ 473 HuBCmMrrAutoUnfoldSelReq 0;
BA_ "GenSigSendType" SG_ 473 HuBCmMrrAutoUnfoldSelReq 2;
BA_ "GenSigTimeoutMsg_HU_High_X445" SG_ 473 HuBCmMrrAutoUnfoldSelReq 0;
BA_ "GenSigTimeoutMsg_HU_Mid_X445" SG_ 473 HuBCmMrrAutoUnfoldSelReq 0;
BA_ "GenSigTimeoutTime_HU_High_X445" SG_ 473 HuBCmMrrAutoUnfoldSelReq 0;
BA_ "GenSigTimeoutTime_HU_Mid_X445" SG_ 473 HuBCmMrrAutoUnfoldSelReq 0;
BA_ "GenSigTimeoutMsg_IVI" SG_ 473 HuBCmMrrAutoUnfoldSelReq 0;
BA_ "GenSigTimeoutTime_IVI" SG_ 473 HuBCmMrrAutoUnfoldSelReq 0;
BA_ "GenSigTimeoutTime_HU_Mid_X451" SG_ 473 IviSwcEvent 0;
BA_ "GenSigTimeoutTime_HU_High_X451" SG_ 473 IviSwcEvent 0;
BA_ "GenSigTimeoutTime_HU_B" SG_ 473 IviSwcEvent 0;
BA_ "GenSigTimeoutTime_HU_A" SG_ 473 IviSwcEvent 0;
BA_ "GenSigTimeoutMsg_HU_Mid_X451" SG_ 473 IviSwcEvent 0;
BA_ "GenSigTimeoutMsg_HU_High_X451" SG_ 473 IviSwcEvent 0;
BA_ "GenSigTimeoutMsg_HU_B" SG_ 473 IviSwcEvent 0;
BA_ "GenSigTimeoutMsg_HU_A" SG_ 473 IviSwcEvent 0;
BA_ "GenSigSendType" SG_ 473 IviSwcEvent 2;
BA_ "GenSigTimeoutMsg_HU_High_X445" SG_ 473 IviSwcEvent 0;
BA_ "GenSigTimeoutMsg_HU_Mid_X445" SG_ 473 IviSwcEvent 0;
BA_ "GenSigTimeoutTime_HU_High_X445" SG_ 473 IviSwcEvent 0;
BA_ "GenSigTimeoutTime_HU_Mid_X445" SG_ 473 IviSwcEvent 0;
BA_ "GenSigTimeoutMsg_IVI" SG_ 473 IviSwcEvent 0;
BA_ "GenSigTimeoutTime_IVI" SG_ 473 IviSwcEvent 0;
BA_ "GenSigTimeoutTime_HU_Mid_X451" SG_ 436 BcmHuOrvmTiltReversePosAck 0;
BA_ "GenSigTimeoutTime_HU_High_X451" SG_ 436 BcmHuOrvmTiltReversePosAck 0;
BA_ "GenSigTimeoutTime_HU_B" SG_ 436 BcmHuOrvmTiltReversePosAck 0;
BA_ "GenSigTimeoutTime_HU_A" SG_ 436 BcmHuOrvmTiltReversePosAck 0;
BA_ "GenSigTimeoutMsg_HU_Mid_X451" SG_ 436 BcmHuOrvmTiltReversePosAck 0;
BA_ "GenSigTimeoutMsg_HU_High_X451" SG_ 436 BcmHuOrvmTiltReversePosAck 0;
BA_ "GenSigTimeoutMsg_HU_B" SG_ 436 BcmHuOrvmTiltReversePosAck 0;
BA_ "GenSigTimeoutMsg_HU_A" SG_ 436 BcmHuOrvmTiltReversePosAck 0;
BA_ "GenSigSendType" SG_ 436 BcmHuOrvmTiltReversePosAck 2;
BA_ "GenSigTimeoutMsg_HU_High_X445" SG_ 436 BcmHuOrvmTiltReversePosAck 0;
BA_ "GenSigTimeoutMsg_HU_Mid_X445" SG_ 436 BcmHuOrvmTiltReversePosAck 0;
BA_ "GenSigTimeoutTime_HU_High_X445" SG_ 436 BcmHuOrvmTiltReversePosAck 0;
BA_ "GenSigTimeoutTime_HU_Mid_X445" SG_ 436 BcmHuOrvmTiltReversePosAck 0;
BA_ "GenSigTimeoutMsg_IVI" SG_ 436 BcmHuOrvmTiltReversePosAck 0;
BA_ "GenSigTimeoutTime_IVI" SG_ 436 BcmHuOrvmTiltReversePosAck 0;
BA_ "GenSigTimeoutTime_HU_Mid_X451" SG_ 436 BcmHuMrrAutoUnfoldSelAck 0;
BA_ "GenSigTimeoutTime_HU_High_X451" SG_ 436 BcmHuMrrAutoUnfoldSelAck 0;
BA_ "GenSigTimeoutTime_HU_B" SG_ 436 BcmHuMrrAutoUnfoldSelAck 0;
BA_ "GenSigTimeoutTime_HU_A" SG_ 436 BcmHuMrrAutoUnfoldSelAck 0;
BA_ "GenSigTimeoutMsg_HU_Mid_X451" SG_ 436 BcmHuMrrAutoUnfoldSelAck 0;
BA_ "GenSigTimeoutMsg_HU_High_X451" SG_ 436 BcmHuMrrAutoUnfoldSelAck 0;
BA_ "GenSigTimeoutMsg_HU_B" SG_ 436 BcmHuMrrAutoUnfoldSelAck 0;
BA_ "GenSigTimeoutMsg_HU_A" SG_ 436 BcmHuMrrAutoUnfoldSelAck 0;
BA_ "GenSigSendType" SG_ 436 BcmHuMrrAutoUnfoldSelAck 2;
BA_ "GenSigTimeoutMsg_HU_High_X445" SG_ 436 BcmHuMrrAutoUnfoldSelAck 0;
BA_ "GenSigTimeoutMsg_HU_Mid_X445" SG_ 436 BcmHuMrrAutoUnfoldSelAck 0;
BA_ "GenSigTimeoutTime_HU_High_X445" SG_ 436 BcmHuMrrAutoUnfoldSelAck 0;
BA_ "GenSigTimeoutTime_HU_Mid_X445" SG_ 436 BcmHuMrrAutoUnfoldSelAck 0;
BA_ "GenSigTimeoutMsg_IVI" SG_ 436 BcmHuMrrAutoUnfoldSelAck 0;
BA_ "GenSigTimeoutTime_IVI" SG_ 436 BcmHuMrrAutoUnfoldSelAck 0;
BA_ "GenSigTimeoutTime_HU_Mid_X451" SG_ 436 PotSwRkeOnOffReqAck 0;
BA_ "GenSigTimeoutTime_HU_High_X451" SG_ 436 PotSwRkeOnOffReqAck 0;
BA_ "GenSigTimeoutTime_HU_B" SG_ 436 PotSwRkeOnOffReqAck 0;
BA_ "GenSigTimeoutTime_HU_A" SG_ 436 PotSwRkeOnOffReqAck 0;
BA_ "GenSigTimeoutMsg_HU_Mid_X451" SG_ 436 PotSwRkeOnOffReqAck 0;
BA_ "GenSigTimeoutMsg_HU_High_X451" SG_ 436 PotSwRkeOnOffReqAck 0;
BA_ "GenSigTimeoutMsg_HU_B" SG_ 436 PotSwRkeOnOffReqAck 0;
BA_ "GenSigTimeoutMsg_HU_A" SG_ 436 PotSwRkeOnOffReqAck 0;
BA_ "GenSigSendType" SG_ 436 PotSwRkeOnOffReqAck 2;
BA_ "GenSigTimeoutMsg_HU_High_X445" SG_ 436 PotSwRkeOnOffReqAck 0;
BA_ "GenSigTimeoutMsg_HU_Mid_X445" SG_ 436 PotSwRkeOnOffReqAck 0;
BA_ "GenSigTimeoutTime_HU_High_X445" SG_ 436 PotSwRkeOnOffReqAck 0;
BA_ "GenSigTimeoutTime_HU_Mid_X445" SG_ 436 PotSwRkeOnOffReqAck 0;
BA_ "GenSigTimeoutMsg_IVI" SG_ 436 PotSwRkeOnOffReqAck 0;
BA_ "GenSigTimeoutTime_IVI" SG_ 436 PotSwRkeOnOffReqAck 0;
BA_ "GenSigTimeoutTime_HU_Mid_X451" SG_ 436 PotGestOnOffReqAck 0;
BA_ "GenSigTimeoutTime_HU_High_X451" SG_ 436 PotGestOnOffReqAck 0;
BA_ "GenSigTimeoutTime_HU_B" SG_ 436 PotGestOnOffReqAck 0;
BA_ "GenSigTimeoutTime_HU_A" SG_ 436 PotGestOnOffReqAck 0;
BA_ "GenSigTimeoutMsg_HU_Mid_X451" SG_ 436 PotGestOnOffReqAck 0;
BA_ "GenSigTimeoutMsg_HU_High_X451" SG_ 436 PotGestOnOffReqAck 0;
BA_ "GenSigTimeoutMsg_HU_B" SG_ 436 PotGestOnOffReqAck 0;
BA_ "GenSigTimeoutMsg_HU_A" SG_ 436 PotGestOnOffReqAck 0;
BA_ "GenSigSendType" SG_ 436 PotGestOnOffReqAck 2;
BA_ "GenSigTimeoutMsg_HU_High_X445" SG_ 436 PotGestOnOffReqAck 0;
BA_ "GenSigTimeoutMsg_HU_Mid_X445" SG_ 436 PotGestOnOffReqAck 0;
BA_ "GenSigTimeoutTime_HU_High_X445" SG_ 436 PotGestOnOffReqAck 0;
BA_ "GenSigTimeoutTime_HU_Mid_X445" SG_ 436 PotGestOnOffReqAck 0;
BA_ "GenSigTimeoutMsg_IVI" SG_ 436 PotGestOnOffReqAck 0;
BA_ "GenSigTimeoutTime_IVI" SG_ 436 PotGestOnOffReqAck 0;
BA_ "GenSigTimeoutTime_HU_Mid_X451" SG_ 436 PotBuzzOnOffReqAck 0;
BA_ "GenSigTimeoutTime_HU_High_X451" SG_ 436 PotBuzzOnOffReqAck 0;
BA_ "GenSigTimeoutTime_HU_B" SG_ 436 PotBuzzOnOffReqAck 0;
BA_ "GenSigTimeoutTime_HU_A" SG_ 436 PotBuzzOnOffReqAck 0;
BA_ "GenSigTimeoutMsg_HU_Mid_X451" SG_ 436 PotBuzzOnOffReqAck 0;
BA_ "GenSigTimeoutMsg_HU_High_X451" SG_ 436 PotBuzzOnOffReqAck 0;
BA_ "GenSigTimeoutMsg_HU_B" SG_ 436 PotBuzzOnOffReqAck 0;
BA_ "GenSigTimeoutMsg_HU_A" SG_ 436 PotBuzzOnOffReqAck 0;
BA_ "GenSigSendType" SG_ 436 PotBuzzOnOffReqAck 2;
BA_ "GenSigTimeoutMsg_HU_High_X445" SG_ 436 PotBuzzOnOffReqAck 0;
BA_ "GenSigTimeoutMsg_HU_Mid_X445" SG_ 436 PotBuzzOnOffReqAck 0;
BA_ "GenSigTimeoutTime_HU_High_X445" SG_ 436 PotBuzzOnOffReqAck 0;
BA_ "GenSigTimeoutTime_HU_Mid_X445" SG_ 436 PotBuzzOnOffReqAck 0;
BA_ "GenSigTimeoutMsg_IVI" SG_ 436 PotBuzzOnOffReqAck 0;
BA_ "GenSigTimeoutTime_IVI" SG_ 436 PotBuzzOnOffReqAck 0;
BA_ "GenSigTimeoutTime_HU_Mid_X451" SG_ 436 PotHeightAdjAck 0;
BA_ "GenSigTimeoutTime_HU_High_X451" SG_ 436 PotHeightAdjAck 0;
BA_ "GenSigTimeoutTime_HU_B" SG_ 436 PotHeightAdjAck 0;
BA_ "GenSigTimeoutTime_HU_A" SG_ 436 PotHeightAdjAck 0;
BA_ "GenSigTimeoutMsg_HU_Mid_X451" SG_ 436 PotHeightAdjAck 0;
BA_ "GenSigTimeoutMsg_HU_High_X451" SG_ 436 PotHeightAdjAck 0;
BA_ "GenSigTimeoutMsg_HU_B" SG_ 436 PotHeightAdjAck 0;
BA_ "GenSigTimeoutMsg_HU_A" SG_ 436 PotHeightAdjAck 0;
BA_ "GenSigSendType" SG_ 436 PotHeightAdjAck 2;
BA_ "GenSigTimeoutMsg_HU_High_X445" SG_ 436 PotHeightAdjAck 0;
BA_ "GenSigTimeoutMsg_HU_Mid_X445" SG_ 436 PotHeightAdjAck 0;
BA_ "GenSigTimeoutTime_HU_High_X445" SG_ 436 PotHeightAdjAck 0;
BA_ "GenSigTimeoutTime_HU_Mid_X445" SG_ 436 PotHeightAdjAck 0;
BA_ "GenSigTimeoutMsg_IVI" SG_ 436 PotHeightAdjAck 0;
BA_ "GenSigTimeoutTime_IVI" SG_ 436 PotHeightAdjAck 0;
BA_ "GenSigTimeoutTime_HU_Mid_X451" SG_ 436 BCmHuGotoEntryExitPosAck 0;
BA_ "GenSigTimeoutTime_HU_High_X451" SG_ 436 BCmHuGotoEntryExitPosAck 0;
BA_ "GenSigTimeoutTime_HU_B" SG_ 436 BCmHuGotoEntryExitPosAck 0;
BA_ "GenSigTimeoutTime_HU_A" SG_ 436 BCmHuGotoEntryExitPosAck 0;
BA_ "GenSigTimeoutMsg_HU_Mid_X451" SG_ 436 BCmHuGotoEntryExitPosAck 0;
BA_ "GenSigTimeoutMsg_HU_High_X451" SG_ 436 BCmHuGotoEntryExitPosAck 0;
BA_ "GenSigTimeoutMsg_HU_B" SG_ 436 BCmHuGotoEntryExitPosAck 0;
BA_ "GenSigTimeoutMsg_HU_A" SG_ 436 BCmHuGotoEntryExitPosAck 0;
BA_ "GenSigSendType" SG_ 436 BCmHuGotoEntryExitPosAck 2;
BA_ "GenSigTimeoutMsg_HU_High_X445" SG_ 436 BCmHuGotoEntryExitPosAck 0;
BA_ "GenSigTimeoutMsg_HU_Mid_X445" SG_ 436 BCmHuGotoEntryExitPosAck 0;
BA_ "GenSigTimeoutTime_HU_High_X445" SG_ 436 BCmHuGotoEntryExitPosAck 0;
BA_ "GenSigTimeoutTime_HU_Mid_X445" SG_ 436 BCmHuGotoEntryExitPosAck 0;
BA_ "GenSigTimeoutMsg_IVI" SG_ 436 BCmHuGotoEntryExitPosAck 0;
BA_ "GenSigTimeoutTime_IVI" SG_ 436 BCmHuGotoEntryExitPosAck 0;
BA_ "GenSigTimeoutTime_HU_Mid_X451" SG_ 436 BCMRemotePrecheck 0;
BA_ "GenSigTimeoutTime_HU_High_X451" SG_ 436 BCMRemotePrecheck 0;
BA_ "GenSigTimeoutTime_HU_B" SG_ 436 BCMRemotePrecheck 0;
BA_ "GenSigTimeoutTime_HU_A" SG_ 436 BCMRemotePrecheck 0;
BA_ "GenSigTimeoutMsg_HU_Mid_X451" SG_ 436 BCMRemotePrecheck 0;
BA_ "GenSigTimeoutMsg_HU_High_X451" SG_ 436 BCMRemotePrecheck 0;
BA_ "GenSigTimeoutMsg_HU_B" SG_ 436 BCMRemotePrecheck 0;
BA_ "GenSigTimeoutMsg_HU_A" SG_ 436 BCMRemotePrecheck 0;
BA_ "GenSigSendType" SG_ 436 BCMRemotePrecheck 2;
BA_ "GenSigTimeoutMsg_HU_High_X445" SG_ 436 BCMRemotePrecheck 0;
BA_ "GenSigTimeoutMsg_HU_Mid_X445" SG_ 436 BCMRemotePrecheck 0;
BA_ "GenSigTimeoutTime_HU_High_X445" SG_ 436 BCMRemotePrecheck 0;
BA_ "GenSigTimeoutTime_HU_Mid_X445" SG_ 436 BCMRemotePrecheck 0;
BA_ "GenSigTimeoutMsg_IVI" SG_ 436 BCMRemotePrecheck 0;
BA_ "GenSigTimeoutTime_IVI" SG_ 436 BCMRemotePrecheck 0;
BA_ "GenSigTimeoutTime_HU_Mid_X451" SG_ 525 PepsHuMrrProximityUnfoldSelAck 0;
BA_ "GenSigTimeoutTime_HU_High_X451" SG_ 525 PepsHuMrrProximityUnfoldSelAck 0;
BA_ "GenSigTimeoutTime_HU_B" SG_ 525 PepsHuMrrProximityUnfoldSelAck 0;
BA_ "GenSigTimeoutTime_HU_A" SG_ 525 PepsHuMrrProximityUnfoldSelAck 0;
BA_ "GenSigTimeoutMsg_HU_Mid_X451" SG_ 525 PepsHuMrrProximityUnfoldSelAck 0;
BA_ "GenSigTimeoutMsg_HU_High_X451" SG_ 525 PepsHuMrrProximityUnfoldSelAck 0;
BA_ "GenSigTimeoutMsg_HU_B" SG_ 525 PepsHuMrrProximityUnfoldSelAck 0;
BA_ "GenSigTimeoutMsg_HU_A" SG_ 525 PepsHuMrrProximityUnfoldSelAck 0;
BA_ "GenSigSendType" SG_ 525 PepsHuMrrProximityUnfoldSelAck 2;
BA_ "GenSigTimeoutMsg_HU_High_X445" SG_ 525 PepsHuMrrProximityUnfoldSelAck 0;
BA_ "GenSigTimeoutMsg_HU_Mid_X445" SG_ 525 PepsHuMrrProximityUnfoldSelAck 0;
BA_ "GenSigTimeoutTime_HU_High_X445" SG_ 525 PepsHuMrrProximityUnfoldSelAck 0;
BA_ "GenSigTimeoutTime_HU_Mid_X445" SG_ 525 PepsHuMrrProximityUnfoldSelAck 0;
BA_ "GenSigTimeoutMsg_IVI" SG_ 525 PepsHuMrrProximityUnfoldSelAck 0;
BA_ "GenSigTimeoutTime_IVI" SG_ 525 PepsHuMrrProximityUnfoldSelAck 0;
BA_ "GenSigTimeoutTime_HU_Mid_X451" SG_ 525 PEPSRemoteCheck 0;
BA_ "GenSigTimeoutTime_HU_High_X451" SG_ 525 PEPSRemoteCheck 0;
BA_ "GenSigTimeoutTime_HU_B" SG_ 525 PEPSRemoteCheck 0;
BA_ "GenSigTimeoutTime_HU_A" SG_ 525 PEPSRemoteCheck 0;
BA_ "GenSigTimeoutMsg_HU_Mid_X451" SG_ 525 PEPSRemoteCheck 0;
BA_ "GenSigTimeoutMsg_HU_High_X451" SG_ 525 PEPSRemoteCheck 0;
BA_ "GenSigTimeoutMsg_HU_B" SG_ 525 PEPSRemoteCheck 0;
BA_ "GenSigTimeoutMsg_HU_A" SG_ 525 PEPSRemoteCheck 0;
BA_ "GenSigSendType" SG_ 525 PEPSRemoteCheck 2;
BA_ "GenSigTimeoutMsg_HU_High_X445" SG_ 525 PEPSRemoteCheck 0;
BA_ "GenSigTimeoutMsg_HU_Mid_X445" SG_ 525 PEPSRemoteCheck 0;
BA_ "GenSigTimeoutTime_HU_High_X445" SG_ 525 PEPSRemoteCheck 0;
BA_ "GenSigTimeoutTime_HU_Mid_X445" SG_ 525 PEPSRemoteCheck 0;
BA_ "GenSigTimeoutMsg_IVI" SG_ 525 PEPSRemoteCheck 0;
BA_ "GenSigTimeoutTime_IVI" SG_ 525 PEPSRemoteCheck 0;
BA_ "GenSigTimeoutTime_HU_Mid_X451" SG_ 525 FotaIgnOnHoldStateAck 0;
BA_ "GenSigTimeoutTime_HU_High_X451" SG_ 525 FotaIgnOnHoldStateAck 0;
BA_ "GenSigTimeoutTime_HU_B" SG_ 525 FotaIgnOnHoldStateAck 0;
BA_ "GenSigTimeoutTime_HU_A" SG_ 525 FotaIgnOnHoldStateAck 0;
BA_ "GenSigTimeoutMsg_HU_Mid_X451" SG_ 525 FotaIgnOnHoldStateAck 0;
BA_ "GenSigTimeoutMsg_HU_High_X451" SG_ 525 FotaIgnOnHoldStateAck 0;
BA_ "GenSigTimeoutMsg_HU_B" SG_ 525 FotaIgnOnHoldStateAck 0;
BA_ "GenSigTimeoutMsg_HU_A" SG_ 525 FotaIgnOnHoldStateAck 0;
BA_ "GenSigSendType" SG_ 525 FotaIgnOnHoldStateAck 2;
BA_ "GenSigTimeoutMsg_HU_High_X445" SG_ 525 FotaIgnOnHoldStateAck 0;
BA_ "GenSigTimeoutMsg_HU_Mid_X445" SG_ 525 FotaIgnOnHoldStateAck 0;
BA_ "GenSigTimeoutTime_HU_High_X445" SG_ 525 FotaIgnOnHoldStateAck 0;
BA_ "GenSigTimeoutTime_HU_Mid_X445" SG_ 525 FotaIgnOnHoldStateAck 0;
BA_ "GenSigTimeoutMsg_IVI" SG_ 525 FotaIgnOnHoldStateAck 0;
BA_ "GenSigTimeoutTime_IVI" SG_ 525 FotaIgnOnHoldStateAck 0;
BA_ "GenSigTimeoutTime_HU_Mid_X451" SG_ 496 FotaIgnOnHoldState 0;
BA_ "GenSigTimeoutTime_HU_High_X451" SG_ 496 FotaIgnOnHoldState 0;
BA_ "GenSigTimeoutTime_HU_B" SG_ 496 FotaIgnOnHoldState 0;
BA_ "GenSigTimeoutTime_HU_A" SG_ 496 FotaIgnOnHoldState 0;
BA_ "GenSigTimeoutMsg_HU_Mid_X451" SG_ 496 FotaIgnOnHoldState 0;
BA_ "GenSigTimeoutMsg_HU_High_X451" SG_ 496 FotaIgnOnHoldState 0;
BA_ "GenSigTimeoutMsg_HU_B" SG_ 496 FotaIgnOnHoldState 0;
BA_ "GenSigTimeoutMsg_HU_A" SG_ 496 FotaIgnOnHoldState 0;
BA_ "GenSigSendType" SG_ 496 FotaIgnOnHoldState 2;
BA_ "GenSigTimeoutMsg_HU_High_X445" SG_ 496 FotaIgnOnHoldState 0;
BA_ "GenSigTimeoutMsg_HU_Mid_X445" SG_ 496 FotaIgnOnHoldState 0;
BA_ "GenSigTimeoutTime_HU_High_X445" SG_ 496 FotaIgnOnHoldState 0;
BA_ "GenSigTimeoutTime_HU_Mid_X445" SG_ 496 FotaIgnOnHoldState 0;
BA_ "GenSigTimeoutMsg_IVI" SG_ 496 FotaIgnOnHoldState 0;
BA_ "GenSigTimeoutTime_IVI" SG_ 496 FotaIgnOnHoldState 0;
BA_ "GenSigSendType" SG_ 584 BatteryCoolingSolValveState 7;
BA_ "GenSigCycleTimeActive" SG_ 584 BatteryCoolingSolValveState 100;
BA_ "GenSigCycleTime" SG_ 584 BatteryCoolingSolValveState 100;
BA_ "GenSigSendType" SG_ 584 RegenPowerConsumption 7;
BA_ "GenSigCycleTimeActive" SG_ 584 RegenPowerConsumption 100;
BA_ "GenSigCycleTime" SG_ 584 RegenPowerConsumption 100;
BA_ "GenSigSendType" SG_ 584 EnerConsumptionCol 7;
BA_ "GenSigCycleTimeActive" SG_ 584 EnerConsumptionCol 100;
BA_ "GenSigCycleTime" SG_ 584 EnerConsumptionCol 100;
BA_ "GenSigSendType" SG_ 584 EnerConsumptionAux 7;
BA_ "GenSigCycleTimeActive" SG_ 584 EnerConsumptionAux 100;
BA_ "GenSigCycleTime" SG_ 584 EnerConsumptionAux 100;
BA_ "GenSigSendType" SG_ 584 EnerConsumptionDrive 7;
BA_ "GenSigCycleTimeActive" SG_ 584 EnerConsumptionDrive 100;
BA_ "GenSigCycleTime" SG_ 584 EnerConsumptionDrive 100;
BA_ "GenSigSendType" SG_ 728 CCmHuDustConcentrationStatus 7;
BA_ "GenSigCycleTimeActive" SG_ 728 CCmHuDustConcentrationStatus 100;
BA_ "GenSigCycleTime" SG_ 728 CCmHuDustConcentrationStatus 100;
BA_ "GenSigSendType" SG_ 728 CCmHuDustConcentration 7;
BA_ "GenSigCycleTimeActive" SG_ 728 CCmHuDustConcentration 100;
BA_ "GenSigCycleTime" SG_ 728 CCmHuDustConcentration 100;
BA_ "GenSigSendType" SG_ 728 CCmHuAqiLevel 7;
BA_ "GenSigCycleTimeActive" SG_ 728 CCmHuAqiLevel 100;
BA_ "GenSigCycleTime" SG_ 728 CCmHuAqiLevel 100;
BA_ "GenSigSendType" SG_ 728 CCmHuDominantPollutantValue 7;
BA_ "GenSigCycleTimeActive" SG_ 728 CCmHuDominantPollutantValue 100;
BA_ "GenSigCycleTime" SG_ 728 CCmHuDominantPollutantValue 100;
BA_ "GenSigSendType" SG_ 728 CCmHuAqiValue 7;
BA_ "GenSigCycleTimeActive" SG_ 728 CCmHuAqiValue 100;
BA_ "GenSigCycleTime" SG_ 728 CCmHuAqiValue 100;
BA_ "GenSigSendType" SG_ 728 CCmHuAqiValueStatus 7;
BA_ "GenSigCycleTimeActive" SG_ 728 CCmHuAqiValueStatus 100;
BA_ "GenSigCycleTime" SG_ 728 CCmHuAqiValueStatus 100;
BA_ "GenSigSendType" SG_ 728 CCmHuAqiAutolearning 7;
BA_ "GenSigCycleTimeActive" SG_ 728 CCmHuAqiAutolearning 100;
BA_ "GenSigCycleTime" SG_ 728 CCmHuAqiAutolearning 100;
BA_ "GenSigSendType" SG_ 736 VehicleMobilizationStateStatus 7;
BA_ "GenSigCycleTimeActive" SG_ 736 VehicleMobilizationStateStatus 100;
BA_ "GenSigCycleTime" SG_ 736 VehicleMobilizationStateStatus 100;
BA_ "GenSigStartValue" SG_ 736 VehicleMobilizationState 1;
BA_ "GenSigSendType" SG_ 736 VehicleMobilizationState 7;
BA_ "GenSigCycleTimeActive" SG_ 736 VehicleMobilizationState 100;
BA_ "GenSigCycleTime" SG_ 736 VehicleMobilizationState 100;
BA_ "GenSigTimeoutTime_HU_Mid_X451" SG_ 467 HuBCmGotoEntryExitPos 0;
BA_ "GenSigTimeoutTime_HU_High_X451" SG_ 467 HuBCmGotoEntryExitPos 0;
BA_ "GenSigTimeoutTime_HU_B" SG_ 467 HuBCmGotoEntryExitPos 0;
BA_ "GenSigTimeoutTime_HU_A" SG_ 467 HuBCmGotoEntryExitPos 0;
BA_ "GenSigTimeoutMsg_HU_Mid_X451" SG_ 467 HuBCmGotoEntryExitPos 0;
BA_ "GenSigTimeoutMsg_HU_High_X451" SG_ 467 HuBCmGotoEntryExitPos 0;
BA_ "GenSigTimeoutMsg_HU_B" SG_ 467 HuBCmGotoEntryExitPos 0;
BA_ "GenSigTimeoutMsg_HU_A" SG_ 467 HuBCmGotoEntryExitPos 0;
BA_ "GenSigSendType" SG_ 467 HuBCmGotoEntryExitPos 2;
BA_ "GenSigTimeoutMsg_HU_High_X445" SG_ 467 HuBCmGotoEntryExitPos 0;
BA_ "GenSigTimeoutMsg_HU_Mid_X445" SG_ 467 HuBCmGotoEntryExitPos 0;
BA_ "GenSigTimeoutTime_HU_High_X445" SG_ 467 HuBCmGotoEntryExitPos 0;
BA_ "GenSigTimeoutTime_HU_Mid_X445" SG_ 467 HuBCmGotoEntryExitPos 0;
BA_ "GenSigTimeoutMsg_IVI" SG_ 467 HuBCmGotoEntryExitPos 0;
BA_ "GenSigTimeoutTime_IVI" SG_ 467 HuBCmGotoEntryExitPos 0;
BA_ "GenSigSendType" SG_ 583 HvBattDischargingStatus_VCAN 7;
BA_ "GenSigCycleTimeActive" SG_ 583 HvBattDischargingStatus_VCAN 100;
BA_ "GenSigCycleTime" SG_ 583 HvBattDischargingStatus_VCAN 100;
BA_ "GenSigSendType" SG_ 583 HvBattDischargingState_VCAN 7;
BA_ "GenSigCycleTimeActive" SG_ 583 HvBattDischargingState_VCAN 100;
BA_ "GenSigCycleTime" SG_ 583 HvBattDischargingState_VCAN 100;
BA_ "GenSigSendType" SG_ 583 HvBattDischargelimitstatus_VCAN 7;
BA_ "GenSigCycleTimeActive" SG_ 583 HvBattDischargelimitstatus_VCAN 100;
BA_ "GenSigCycleTime" SG_ 583 HvBattDischargelimitstatus_VCAN 100;
BA_ "GenSigSendType" SG_ 583 HvBattDischargelimit_VCAN 7;
BA_ "GenSigCycleTimeActive" SG_ 583 HvBattDischargelimit_VCAN 100;
BA_ "GenSigCycleTime" SG_ 583 HvBattDischargelimit_VCAN 100;
BA_ "GenSigSendType" SG_ 583 HvBattFullChargeStatus_new_VCAN 7;
BA_ "GenSigCycleTimeActive" SG_ 583 HvBattFullChargeStatus_new_VCAN 100;
BA_ "GenSigCycleTime" SG_ 583 HvBattFullChargeStatus_new_VCAN 100;
BA_ "GenSigSendType" SG_ 583 HvBattFullCharge_new_VCAN 7;
BA_ "GenSigCycleTimeActive" SG_ 583 HvBattFullCharge_new_VCAN 100;
BA_ "GenSigCycleTime" SG_ 583 HvBattFullCharge_new_VCAN 100;
BA_ "GenSigSendType" SG_ 583 CruiseSwitchStateVCUStatus 7;
BA_ "GenSigCycleTimeActive" SG_ 583 CruiseSwitchStateVCUStatus 100;
BA_ "GenSigCycleTime" SG_ 583 CruiseSwitchStateVCUStatus 100;
BA_ "GenSigSendType" SG_ 583 CruiseSwitchStateVCU 7;
BA_ "GenSigCycleTimeActive" SG_ 583 CruiseSwitchStateVCU 100;
BA_ "GenSigCycleTime" SG_ 583 CruiseSwitchStateVCU 100;
BA_ "GenSigSendType" SG_ 583 VcuModeSelectionChangeTxt 7;
BA_ "GenSigCycleTimeActive" SG_ 583 VcuModeSelectionChangeTxt 100;
BA_ "GenSigCycleTime" SG_ 583 VcuModeSelectionChangeTxt 100;
BA_ "GenSigSendType" SG_ 583 ModeForDisplayVCUStatus 7;
BA_ "GenSigCycleTimeActive" SG_ 583 ModeForDisplayVCUStatus 100;
BA_ "GenSigCycleTime" SG_ 583 ModeForDisplayVCUStatus 100;
BA_ "GenSigSendType" SG_ 583 ModeForDisplayVCU 7;
BA_ "GenSigCycleTimeActive" SG_ 583 ModeForDisplayVCU 100;
BA_ "GenSigCycleTime" SG_ 583 ModeForDisplayVCU 100;
BA_ "GenSigSendType" SG_ 583 ModeSelectionSwStateVCUStatus 7;
BA_ "GenSigCycleTimeActive" SG_ 583 ModeSelectionSwStateVCUStatus 100;
BA_ "GenSigCycleTime" SG_ 583 ModeSelectionSwStateVCUStatus 100;
BA_ "GenSigSendType" SG_ 583 ModeSelectionSwStateVCU 7;
BA_ "GenSigCycleTimeActive" SG_ 583 ModeSelectionSwStateVCU 100;
BA_ "GenSigCycleTime" SG_ 583 ModeSelectionSwStateVCU 100;
BA_ "GenSigSendType" SG_ 583 VcuRegenSelectionChangeTxt 7;
BA_ "GenSigCycleTimeActive" SG_ 583 VcuRegenSelectionChangeTxt 100;
BA_ "GenSigCycleTime" SG_ 583 VcuRegenSelectionChangeTxt 100;
BA_ "GenSigSendType" SG_ 583 RegenForDisplayVCUStatus 7;
BA_ "GenSigCycleTimeActive" SG_ 583 RegenForDisplayVCUStatus 100;
BA_ "GenSigCycleTime" SG_ 583 RegenForDisplayVCUStatus 100;
BA_ "GenSigStartValue" SG_ 583 RegenForDisplayVCU 7;
BA_ "GenSigSendType" SG_ 583 RegenForDisplayVCU 7;
BA_ "GenSigCycleTimeActive" SG_ 583 RegenForDisplayVCU 100;
BA_ "GenSigCycleTime" SG_ 583 RegenForDisplayVCU 100;
BA_ "GenSigSendType" SG_ 583 VcuCruiseSelectionChangeTxt 7;
BA_ "GenSigCycleTimeActive" SG_ 583 VcuCruiseSelectionChangeTxt 100;
BA_ "GenSigCycleTime" SG_ 583 VcuCruiseSelectionChangeTxt 100;
BA_ "GenSigSendType" SG_ 583 DesiredCruiseSpeedStatus 7;
BA_ "GenSigCycleTimeActive" SG_ 583 DesiredCruiseSpeedStatus 100;
BA_ "GenSigCycleTime" SG_ 583 DesiredCruiseSpeedStatus 100;
BA_ "GenSigSendType" SG_ 583 DesiredCruiseSpeed 7;
BA_ "GenSigCycleTimeActive" SG_ 583 DesiredCruiseSpeed 100;
BA_ "GenSigCycleTime" SG_ 583 DesiredCruiseSpeed 100;
BA_ "GenSigSendType" SG_ 583 VCuCruiseStateStatus 7;
BA_ "GenSigCycleTimeActive" SG_ 583 VCuCruiseStateStatus 100;
BA_ "GenSigCycleTime" SG_ 583 VCuCruiseStateStatus 100;
BA_ "GenSigSendType" SG_ 583 VCuCruiseState 7;
BA_ "GenSigCycleTimeActive" SG_ 583 VCuCruiseState 100;
BA_ "GenSigCycleTime" SG_ 583 VCuCruiseState 100;
BA_ "GenSigSendType" SG_ 583 HvBattFullChargeStatus_VCAN 7;
BA_ "GenSigCycleTimeActive" SG_ 583 HvBattFullChargeStatus_VCAN 100;
BA_ "GenSigCycleTime" SG_ 583 HvBattFullChargeStatus_VCAN 100;
BA_ "GenSigSendType" SG_ 583 HvBattFullCharge_VCAN 7;
BA_ "GenSigCycleTimeActive" SG_ 583 HvBattFullCharge_VCAN 100;
BA_ "GenSigCycleTime" SG_ 583 HvBattFullCharge_VCAN 100;
BA_ "GenSigSendType" SG_ 741 RemoteAcPvTempSetStatus 7;
BA_ "GenSigCycleTimeActive" SG_ 741 RemoteAcPvTempSetStatus 100;
BA_ "GenSigCycleTime" SG_ 741 RemoteAcPvTempSetStatus 100;
BA_ "GenSigStartValue" SG_ 741 RemoteAcPvTempSet 19;
BA_ "GenSigSendType" SG_ 741 RemoteAcPvTempSet 7;
BA_ "GenSigCycleTimeActive" SG_ 741 RemoteAcPvTempSet 100;
BA_ "GenSigCycleTime" SG_ 741 RemoteAcPvTempSet 100;
BA_ "GenSigSendType" SG_ 741 RemoteEngAcCmdStatus 7;
BA_ "GenSigCycleTimeActive" SG_ 741 RemoteEngAcCmdStatus 100;
BA_ "GenSigCycleTime" SG_ 741 RemoteEngAcCmdStatus 100;
BA_ "GenSigStartValue" SG_ 741 RemoteEngAcCmd 2;
BA_ "GenSigSendType" SG_ 741 RemoteEngAcCmd 7;
BA_ "GenSigCycleTimeActive" SG_ 741 RemoteEngAcCmd 100;
BA_ "GenSigCycleTime" SG_ 741 RemoteEngAcCmd 100;
BA_ "GenSigSendType" SG_ 741 FotaUpdateState 7;
BA_ "GenSigCycleTimeActive" SG_ 741 FotaUpdateState 100;
BA_ "GenSigCycleTime" SG_ 741 FotaUpdateState 100;
BA_ "GenSigSendType" SG_ 673 WirelessChargerPresence 7;
BA_ "GenSigCycleTimeActive" SG_ 673 WirelessChargerPresence 100;
BA_ "GenSigCycleTime" SG_ 673 WirelessChargerPresence 100;
BA_ "GenSigSendType" SG_ 673 WcdutycycleStatus 7;
BA_ "GenSigCycleTimeActive" SG_ 673 WcdutycycleStatus 100;
BA_ "GenSigCycleTime" SG_ 673 WcdutycycleStatus 100;
BA_ "GenSigSendType" SG_ 673 Wcdutycycle 7;
BA_ "GenSigCycleTimeActive" SG_ 673 Wcdutycycle 100;
BA_ "GenSigCycleTime" SG_ 673 Wcdutycycle 100;
BA_ "GenSigTimeoutTime_HU_Mid_X451" SG_ 491 HuBCmWindowWindingHmiCmdSupportA 0;
BA_ "GenSigTimeoutTime_HU_High_X451" SG_ 491 HuBCmWindowWindingHmiCmdSupportA 0;
BA_ "GenSigTimeoutTime_HU_B" SG_ 491 HuBCmWindowWindingHmiCmdSupportA 0;
BA_ "GenSigTimeoutTime_HU_A" SG_ 491 HuBCmWindowWindingHmiCmdSupportA 0;
BA_ "GenSigTimeoutMsg_HU_Mid_X451" SG_ 491 HuBCmWindowWindingHmiCmdSupportA 0;
BA_ "GenSigTimeoutMsg_HU_High_X451" SG_ 491 HuBCmWindowWindingHmiCmdSupportA 0;
BA_ "GenSigTimeoutMsg_HU_B" SG_ 491 HuBCmWindowWindingHmiCmdSupportA 0;
BA_ "GenSigTimeoutMsg_HU_A" SG_ 491 HuBCmWindowWindingHmiCmdSupportA 0;
BA_ "GenSigSendType" SG_ 491 HuBCmWindowWindingHmiCmdSupportA 2;
BA_ "GenSigTimeoutMsg_HU_High_X445" SG_ 491 HuBCmWindowWindingHmiCmdSupportA 0;
BA_ "GenSigTimeoutMsg_HU_Mid_X445" SG_ 491 HuBCmWindowWindingHmiCmdSupportA 0;
BA_ "GenSigTimeoutTime_HU_High_X445" SG_ 491 HuBCmWindowWindingHmiCmdSupportA 0;
BA_ "GenSigTimeoutTime_HU_Mid_X445" SG_ 491 HuBCmWindowWindingHmiCmdSupportA 0;
BA_ "GenSigTimeoutMsg_IVI" SG_ 491 HuBCmWindowWindingHmiCmdSupportA 0;
BA_ "GenSigTimeoutTime_IVI" SG_ 491 HuBCmWindowWindingHmiCmdSupportA 0;
BA_ "SystemSignalLongSymbol" SG_ 491 HuBCmWindowWindingHmiCmdSupportA "HuBCmWindowWindingHmiCmdSupportAck";
BA_ "GenSigTimeoutTime_HU_Mid_X451" SG_ 491 HuBCmTyreTempVrCmdSupportAck 0;
BA_ "GenSigTimeoutTime_HU_High_X451" SG_ 491 HuBCmTyreTempVrCmdSupportAck 0;
BA_ "GenSigTimeoutTime_HU_B" SG_ 491 HuBCmTyreTempVrCmdSupportAck 0;
BA_ "GenSigTimeoutTime_HU_A" SG_ 491 HuBCmTyreTempVrCmdSupportAck 0;
BA_ "GenSigTimeoutMsg_HU_Mid_X451" SG_ 491 HuBCmTyreTempVrCmdSupportAck 0;
BA_ "GenSigTimeoutMsg_HU_High_X451" SG_ 491 HuBCmTyreTempVrCmdSupportAck 0;
BA_ "GenSigTimeoutMsg_HU_B" SG_ 491 HuBCmTyreTempVrCmdSupportAck 0;
BA_ "GenSigTimeoutMsg_HU_A" SG_ 491 HuBCmTyreTempVrCmdSupportAck 0;
BA_ "GenSigSendType" SG_ 491 HuBCmTyreTempVrCmdSupportAck 2;
BA_ "GenSigTimeoutMsg_HU_High_X445" SG_ 491 HuBCmTyreTempVrCmdSupportAck 0;
BA_ "GenSigTimeoutMsg_HU_Mid_X445" SG_ 491 HuBCmTyreTempVrCmdSupportAck 0;
BA_ "GenSigTimeoutTime_HU_High_X445" SG_ 491 HuBCmTyreTempVrCmdSupportAck 0;
BA_ "GenSigTimeoutTime_HU_Mid_X445" SG_ 491 HuBCmTyreTempVrCmdSupportAck 0;
BA_ "GenSigTimeoutMsg_IVI" SG_ 491 HuBCmTyreTempVrCmdSupportAck 0;
BA_ "GenSigTimeoutTime_IVI" SG_ 491 HuBCmTyreTempVrCmdSupportAck 0;
BA_ "GenSigTimeoutTime_HU_Mid_X451" SG_ 491 HuBCmTyreTempHmiCmdSupportAck 0;
BA_ "GenSigTimeoutTime_HU_High_X451" SG_ 491 HuBCmTyreTempHmiCmdSupportAck 0;
BA_ "GenSigTimeoutTime_HU_B" SG_ 491 HuBCmTyreTempHmiCmdSupportAck 0;
BA_ "GenSigTimeoutTime_HU_A" SG_ 491 HuBCmTyreTempHmiCmdSupportAck 0;
BA_ "GenSigTimeoutMsg_HU_Mid_X451" SG_ 491 HuBCmTyreTempHmiCmdSupportAck 0;
BA_ "GenSigTimeoutMsg_HU_High_X451" SG_ 491 HuBCmTyreTempHmiCmdSupportAck 0;
BA_ "GenSigTimeoutMsg_HU_B" SG_ 491 HuBCmTyreTempHmiCmdSupportAck 0;
BA_ "GenSigTimeoutMsg_HU_A" SG_ 491 HuBCmTyreTempHmiCmdSupportAck 0;
BA_ "GenSigSendType" SG_ 491 HuBCmTyreTempHmiCmdSupportAck 2;
BA_ "GenSigTimeoutMsg_HU_High_X445" SG_ 491 HuBCmTyreTempHmiCmdSupportAck 0;
BA_ "GenSigTimeoutMsg_HU_Mid_X445" SG_ 491 HuBCmTyreTempHmiCmdSupportAck 0;
BA_ "GenSigTimeoutTime_HU_High_X445" SG_ 491 HuBCmTyreTempHmiCmdSupportAck 0;
BA_ "GenSigTimeoutTime_HU_Mid_X445" SG_ 491 HuBCmTyreTempHmiCmdSupportAck 0;
BA_ "GenSigTimeoutMsg_IVI" SG_ 491 HuBCmTyreTempHmiCmdSupportAck 0;
BA_ "GenSigTimeoutTime_IVI" SG_ 491 HuBCmTyreTempHmiCmdSupportAck 0;
BA_ "GenSigTimeoutTime_HU_Mid_X451" SG_ 491 HuBCmTyrePressureVrCmdSupportAck 0;
BA_ "GenSigTimeoutTime_HU_High_X451" SG_ 491 HuBCmTyrePressureVrCmdSupportAck 0;
BA_ "GenSigTimeoutTime_HU_B" SG_ 491 HuBCmTyrePressureVrCmdSupportAck 0;
BA_ "GenSigTimeoutTime_HU_A" SG_ 491 HuBCmTyrePressureVrCmdSupportAck 0;
BA_ "GenSigTimeoutMsg_HU_Mid_X451" SG_ 491 HuBCmTyrePressureVrCmdSupportAck 0;
BA_ "GenSigTimeoutMsg_HU_High_X451" SG_ 491 HuBCmTyrePressureVrCmdSupportAck 0;
BA_ "GenSigTimeoutMsg_HU_B" SG_ 491 HuBCmTyrePressureVrCmdSupportAck 0;
BA_ "GenSigTimeoutMsg_HU_A" SG_ 491 HuBCmTyrePressureVrCmdSupportAck 0;
BA_ "GenSigSendType" SG_ 491 HuBCmTyrePressureVrCmdSupportAck 2;
BA_ "GenSigTimeoutMsg_HU_High_X445" SG_ 491 HuBCmTyrePressureVrCmdSupportAck 0;
BA_ "GenSigTimeoutMsg_HU_Mid_X445" SG_ 491 HuBCmTyrePressureVrCmdSupportAck 0;
BA_ "GenSigTimeoutTime_HU_High_X445" SG_ 491 HuBCmTyrePressureVrCmdSupportAck 0;
BA_ "GenSigTimeoutTime_HU_Mid_X445" SG_ 491 HuBCmTyrePressureVrCmdSupportAck 0;
BA_ "GenSigTimeoutMsg_IVI" SG_ 491 HuBCmTyrePressureVrCmdSupportAck 0;
BA_ "GenSigTimeoutTime_IVI" SG_ 491 HuBCmTyrePressureVrCmdSupportAck 0;
BA_ "GenSigTimeoutTime_HU_Mid_X451" SG_ 491 HuBCmTyrePressureHmiCmdSupportAc 0;
BA_ "GenSigTimeoutTime_HU_High_X451" SG_ 491 HuBCmTyrePressureHmiCmdSupportAc 0;
BA_ "GenSigTimeoutTime_HU_B" SG_ 491 HuBCmTyrePressureHmiCmdSupportAc 0;
BA_ "GenSigTimeoutTime_HU_A" SG_ 491 HuBCmTyrePressureHmiCmdSupportAc 0;
BA_ "GenSigTimeoutMsg_HU_Mid_X451" SG_ 491 HuBCmTyrePressureHmiCmdSupportAc 0;
BA_ "GenSigTimeoutMsg_HU_High_X451" SG_ 491 HuBCmTyrePressureHmiCmdSupportAc 0;
BA_ "GenSigTimeoutMsg_HU_B" SG_ 491 HuBCmTyrePressureHmiCmdSupportAc 0;
BA_ "GenSigTimeoutMsg_HU_A" SG_ 491 HuBCmTyrePressureHmiCmdSupportAc 0;
BA_ "GenSigSendType" SG_ 491 HuBCmTyrePressureHmiCmdSupportAc 2;
BA_ "GenSigTimeoutMsg_HU_High_X445" SG_ 491 HuBCmTyrePressureHmiCmdSupportAc 0;
BA_ "GenSigTimeoutMsg_HU_Mid_X445" SG_ 491 HuBCmTyrePressureHmiCmdSupportAc 0;
BA_ "GenSigTimeoutTime_HU_High_X445" SG_ 491 HuBCmTyrePressureHmiCmdSupportAc 0;
BA_ "GenSigTimeoutTime_HU_Mid_X445" SG_ 491 HuBCmTyrePressureHmiCmdSupportAc 0;
BA_ "GenSigTimeoutMsg_IVI" SG_ 491 HuBCmTyrePressureHmiCmdSupportAc 0;
BA_ "GenSigTimeoutTime_IVI" SG_ 491 HuBCmTyrePressureHmiCmdSupportAc 0;
BA_ "SystemSignalLongSymbol" SG_ 491 HuBCmTyrePressureHmiCmdSupportAc "HuBCmTyrePressureHmiCmdSupportAck";
BA_ "GenSigTimeoutTime_HU_Mid_X451" SG_ 491 HuBCmSunroofTiltVrCmdSupportAck 0;
BA_ "GenSigTimeoutTime_HU_High_X451" SG_ 491 HuBCmSunroofTiltVrCmdSupportAck 0;
BA_ "GenSigTimeoutTime_HU_B" SG_ 491 HuBCmSunroofTiltVrCmdSupportAck 0;
BA_ "GenSigTimeoutTime_HU_A" SG_ 491 HuBCmSunroofTiltVrCmdSupportAck 0;
BA_ "GenSigTimeoutMsg_HU_Mid_X451" SG_ 491 HuBCmSunroofTiltVrCmdSupportAck 0;
BA_ "GenSigTimeoutMsg_HU_High_X451" SG_ 491 HuBCmSunroofTiltVrCmdSupportAck 0;
BA_ "GenSigTimeoutMsg_HU_B" SG_ 491 HuBCmSunroofTiltVrCmdSupportAck 0;
BA_ "GenSigTimeoutMsg_HU_A" SG_ 491 HuBCmSunroofTiltVrCmdSupportAck 0;
BA_ "GenSigSendType" SG_ 491 HuBCmSunroofTiltVrCmdSupportAck 2;
BA_ "GenSigTimeoutMsg_HU_High_X445" SG_ 491 HuBCmSunroofTiltVrCmdSupportAck 0;
BA_ "GenSigTimeoutMsg_HU_Mid_X445" SG_ 491 HuBCmSunroofTiltVrCmdSupportAck 0;
BA_ "GenSigTimeoutTime_HU_High_X445" SG_ 491 HuBCmSunroofTiltVrCmdSupportAck 0;
BA_ "GenSigTimeoutTime_HU_Mid_X445" SG_ 491 HuBCmSunroofTiltVrCmdSupportAck 0;
BA_ "GenSigTimeoutMsg_IVI" SG_ 491 HuBCmSunroofTiltVrCmdSupportAck 0;
BA_ "GenSigTimeoutTime_IVI" SG_ 491 HuBCmSunroofTiltVrCmdSupportAck 0;
BA_ "GenSigTimeoutTime_HU_Mid_X451" SG_ 491 HuBCmRoofLampVrCmdSupportAck 0;
BA_ "GenSigTimeoutTime_HU_High_X451" SG_ 491 HuBCmRoofLampVrCmdSupportAck 0;
BA_ "GenSigTimeoutTime_HU_B" SG_ 491 HuBCmRoofLampVrCmdSupportAck 0;
BA_ "GenSigTimeoutTime_HU_A" SG_ 491 HuBCmRoofLampVrCmdSupportAck 0;
BA_ "GenSigTimeoutMsg_HU_Mid_X451" SG_ 491 HuBCmRoofLampVrCmdSupportAck 0;
BA_ "GenSigTimeoutMsg_HU_High_X451" SG_ 491 HuBCmRoofLampVrCmdSupportAck 0;
BA_ "GenSigTimeoutMsg_HU_B" SG_ 491 HuBCmRoofLampVrCmdSupportAck 0;
BA_ "GenSigTimeoutMsg_HU_A" SG_ 491 HuBCmRoofLampVrCmdSupportAck 0;
BA_ "GenSigSendType" SG_ 491 HuBCmRoofLampVrCmdSupportAck 2;
BA_ "GenSigTimeoutMsg_HU_High_X445" SG_ 491 HuBCmRoofLampVrCmdSupportAck 0;
BA_ "GenSigTimeoutMsg_HU_Mid_X445" SG_ 491 HuBCmRoofLampVrCmdSupportAck 0;
BA_ "GenSigTimeoutTime_HU_High_X445" SG_ 491 HuBCmRoofLampVrCmdSupportAck 0;
BA_ "GenSigTimeoutTime_HU_Mid_X445" SG_ 491 HuBCmRoofLampVrCmdSupportAck 0;
BA_ "GenSigTimeoutMsg_IVI" SG_ 491 HuBCmRoofLampVrCmdSupportAck 0;
BA_ "GenSigTimeoutTime_IVI" SG_ 491 HuBCmRoofLampVrCmdSupportAck 0;
BA_ "GenSigTimeoutTime_HU_Mid_X451" SG_ 491 HuBCmRoofLampHmiCmdSupportAck 0;
BA_ "GenSigTimeoutTime_HU_High_X451" SG_ 491 HuBCmRoofLampHmiCmdSupportAck 0;
BA_ "GenSigTimeoutTime_HU_B" SG_ 491 HuBCmRoofLampHmiCmdSupportAck 0;
BA_ "GenSigTimeoutTime_HU_A" SG_ 491 HuBCmRoofLampHmiCmdSupportAck 0;
BA_ "GenSigTimeoutMsg_HU_Mid_X451" SG_ 491 HuBCmRoofLampHmiCmdSupportAck 0;
BA_ "GenSigTimeoutMsg_HU_High_X451" SG_ 491 HuBCmRoofLampHmiCmdSupportAck 0;
BA_ "GenSigTimeoutMsg_HU_B" SG_ 491 HuBCmRoofLampHmiCmdSupportAck 0;
BA_ "GenSigTimeoutMsg_HU_A" SG_ 491 HuBCmRoofLampHmiCmdSupportAck 0;
BA_ "GenSigSendType" SG_ 491 HuBCmRoofLampHmiCmdSupportAck 2;
BA_ "GenSigTimeoutMsg_HU_High_X445" SG_ 491 HuBCmRoofLampHmiCmdSupportAck 0;
BA_ "GenSigTimeoutMsg_HU_Mid_X445" SG_ 491 HuBCmRoofLampHmiCmdSupportAck 0;
BA_ "GenSigTimeoutTime_HU_High_X445" SG_ 491 HuBCmRoofLampHmiCmdSupportAck 0;
BA_ "GenSigTimeoutTime_HU_Mid_X445" SG_ 491 HuBCmRoofLampHmiCmdSupportAck 0;
BA_ "GenSigTimeoutMsg_IVI" SG_ 491 HuBCmRoofLampHmiCmdSupportAck 0;
BA_ "GenSigTimeoutTime_IVI" SG_ 491 HuBCmRoofLampHmiCmdSupportAck 0;
BA_ "GenSigTimeoutTime_HU_Mid_X451" SG_ 491 HuBCmPositionLampVrCmdSupportAck 0;
BA_ "GenSigTimeoutTime_HU_High_X451" SG_ 491 HuBCmPositionLampVrCmdSupportAck 0;
BA_ "GenSigTimeoutTime_HU_B" SG_ 491 HuBCmPositionLampVrCmdSupportAck 0;
BA_ "GenSigTimeoutTime_HU_A" SG_ 491 HuBCmPositionLampVrCmdSupportAck 0;
BA_ "GenSigTimeoutMsg_HU_Mid_X451" SG_ 491 HuBCmPositionLampVrCmdSupportAck 0;
BA_ "GenSigTimeoutMsg_HU_High_X451" SG_ 491 HuBCmPositionLampVrCmdSupportAck 0;
BA_ "GenSigTimeoutMsg_HU_B" SG_ 491 HuBCmPositionLampVrCmdSupportAck 0;
BA_ "GenSigTimeoutMsg_HU_A" SG_ 491 HuBCmPositionLampVrCmdSupportAck 0;
BA_ "GenSigSendType" SG_ 491 HuBCmPositionLampVrCmdSupportAck 2;
BA_ "GenSigTimeoutMsg_HU_High_X445" SG_ 491 HuBCmPositionLampVrCmdSupportAck 0;
BA_ "GenSigTimeoutMsg_HU_Mid_X445" SG_ 491 HuBCmPositionLampVrCmdSupportAck 0;
BA_ "GenSigTimeoutTime_HU_High_X445" SG_ 491 HuBCmPositionLampVrCmdSupportAck 0;
BA_ "GenSigTimeoutTime_HU_Mid_X445" SG_ 491 HuBCmPositionLampVrCmdSupportAck 0;
BA_ "GenSigTimeoutMsg_IVI" SG_ 491 HuBCmPositionLampVrCmdSupportAck 0;
BA_ "GenSigTimeoutTime_IVI" SG_ 491 HuBCmPositionLampVrCmdSupportAck 0;
BA_ "GenSigTimeoutTime_HU_Mid_X451" SG_ 491 HuBCmORVMVrCmdSupportAck 0;
BA_ "GenSigTimeoutTime_HU_High_X451" SG_ 491 HuBCmORVMVrCmdSupportAck 0;
BA_ "GenSigTimeoutTime_HU_B" SG_ 491 HuBCmORVMVrCmdSupportAck 0;
BA_ "GenSigTimeoutTime_HU_A" SG_ 491 HuBCmORVMVrCmdSupportAck 0;
BA_ "GenSigTimeoutMsg_HU_Mid_X451" SG_ 491 HuBCmORVMVrCmdSupportAck 0;
BA_ "GenSigTimeoutMsg_HU_High_X451" SG_ 491 HuBCmORVMVrCmdSupportAck 0;
BA_ "GenSigTimeoutMsg_HU_B" SG_ 491 HuBCmORVMVrCmdSupportAck 0;
BA_ "GenSigTimeoutMsg_HU_A" SG_ 491 HuBCmORVMVrCmdSupportAck 0;
BA_ "GenSigSendType" SG_ 491 HuBCmORVMVrCmdSupportAck 2;
BA_ "GenSigTimeoutMsg_HU_High_X445" SG_ 491 HuBCmORVMVrCmdSupportAck 0;
BA_ "GenSigTimeoutMsg_HU_Mid_X445" SG_ 491 HuBCmORVMVrCmdSupportAck 0;
BA_ "GenSigTimeoutTime_HU_High_X445" SG_ 491 HuBCmORVMVrCmdSupportAck 0;
BA_ "GenSigTimeoutTime_HU_Mid_X445" SG_ 491 HuBCmORVMVrCmdSupportAck 0;
BA_ "GenSigTimeoutMsg_IVI" SG_ 491 HuBCmORVMVrCmdSupportAck 0;
BA_ "GenSigTimeoutTime_IVI" SG_ 491 HuBCmORVMVrCmdSupportAck 0;
BA_ "GenSigTimeoutTime_HU_Mid_X451" SG_ 491 HuBCmORVMHmiCmdSupportAck 0;
BA_ "GenSigTimeoutTime_HU_High_X451" SG_ 491 HuBCmORVMHmiCmdSupportAck 0;
BA_ "GenSigTimeoutTime_HU_B" SG_ 491 HuBCmORVMHmiCmdSupportAck 0;
BA_ "GenSigTimeoutTime_HU_A" SG_ 491 HuBCmORVMHmiCmdSupportAck 0;
BA_ "GenSigTimeoutMsg_HU_Mid_X451" SG_ 491 HuBCmORVMHmiCmdSupportAck 0;
BA_ "GenSigTimeoutMsg_HU_High_X451" SG_ 491 HuBCmORVMHmiCmdSupportAck 0;
BA_ "GenSigTimeoutMsg_HU_B" SG_ 491 HuBCmORVMHmiCmdSupportAck 0;
BA_ "GenSigTimeoutMsg_HU_A" SG_ 491 HuBCmORVMHmiCmdSupportAck 0;
BA_ "GenSigSendType" SG_ 491 HuBCmORVMHmiCmdSupportAck 2;
BA_ "GenSigTimeoutMsg_HU_High_X445" SG_ 491 HuBCmORVMHmiCmdSupportAck 0;
BA_ "GenSigTimeoutMsg_HU_Mid_X445" SG_ 491 HuBCmORVMHmiCmdSupportAck 0;
BA_ "GenSigTimeoutTime_HU_High_X445" SG_ 491 HuBCmORVMHmiCmdSupportAck 0;
BA_ "GenSigTimeoutTime_HU_Mid_X445" SG_ 491 HuBCmORVMHmiCmdSupportAck 0;
BA_ "GenSigTimeoutMsg_IVI" SG_ 491 HuBCmORVMHmiCmdSupportAck 0;
BA_ "GenSigTimeoutTime_IVI" SG_ 491 HuBCmORVMHmiCmdSupportAck 0;
BA_ "GenSigTimeoutTime_HU_Mid_X451" SG_ 491 HuBCmMoodLightVrCmdSupportAck 0;
BA_ "GenSigTimeoutTime_HU_High_X451" SG_ 491 HuBCmMoodLightVrCmdSupportAck 0;
BA_ "GenSigTimeoutTime_HU_B" SG_ 491 HuBCmMoodLightVrCmdSupportAck 0;
BA_ "GenSigTimeoutTime_HU_A" SG_ 491 HuBCmMoodLightVrCmdSupportAck 0;
BA_ "GenSigTimeoutMsg_HU_Mid_X451" SG_ 491 HuBCmMoodLightVrCmdSupportAck 0;
BA_ "GenSigTimeoutMsg_HU_High_X451" SG_ 491 HuBCmMoodLightVrCmdSupportAck 0;
BA_ "GenSigTimeoutMsg_HU_B" SG_ 491 HuBCmMoodLightVrCmdSupportAck 0;
BA_ "GenSigTimeoutMsg_HU_A" SG_ 491 HuBCmMoodLightVrCmdSupportAck 0;
BA_ "GenSigSendType" SG_ 491 HuBCmMoodLightVrCmdSupportAck 2;
BA_ "GenSigTimeoutMsg_HU_High_X445" SG_ 491 HuBCmMoodLightVrCmdSupportAck 0;
BA_ "GenSigTimeoutMsg_HU_Mid_X445" SG_ 491 HuBCmMoodLightVrCmdSupportAck 0;
BA_ "GenSigTimeoutTime_HU_High_X445" SG_ 491 HuBCmMoodLightVrCmdSupportAck 0;
BA_ "GenSigTimeoutTime_HU_Mid_X445" SG_ 491 HuBCmMoodLightVrCmdSupportAck 0;
BA_ "GenSigTimeoutMsg_IVI" SG_ 491 HuBCmMoodLightVrCmdSupportAck 0;
BA_ "GenSigTimeoutTime_IVI" SG_ 491 HuBCmMoodLightVrCmdSupportAck 0;
BA_ "GenSigTimeoutTime_HU_Mid_X451" SG_ 491 HuBCmHazardLampVrCmdSupportAck 0;
BA_ "GenSigTimeoutTime_HU_High_X451" SG_ 491 HuBCmHazardLampVrCmdSupportAck 0;
BA_ "GenSigTimeoutTime_HU_B" SG_ 491 HuBCmHazardLampVrCmdSupportAck 0;
BA_ "GenSigTimeoutTime_HU_A" SG_ 491 HuBCmHazardLampVrCmdSupportAck 0;
BA_ "GenSigTimeoutMsg_HU_Mid_X451" SG_ 491 HuBCmHazardLampVrCmdSupportAck 0;
BA_ "GenSigTimeoutMsg_HU_High_X451" SG_ 491 HuBCmHazardLampVrCmdSupportAck 0;
BA_ "GenSigTimeoutMsg_HU_B" SG_ 491 HuBCmHazardLampVrCmdSupportAck 0;
BA_ "GenSigTimeoutMsg_HU_A" SG_ 491 HuBCmHazardLampVrCmdSupportAck 0;
BA_ "GenSigSendType" SG_ 491 HuBCmHazardLampVrCmdSupportAck 2;
BA_ "GenSigTimeoutMsg_HU_High_X445" SG_ 491 HuBCmHazardLampVrCmdSupportAck 0;
BA_ "GenSigTimeoutMsg_HU_Mid_X445" SG_ 491 HuBCmHazardLampVrCmdSupportAck 0;
BA_ "GenSigTimeoutTime_HU_High_X445" SG_ 491 HuBCmHazardLampVrCmdSupportAck 0;
BA_ "GenSigTimeoutTime_HU_Mid_X445" SG_ 491 HuBCmHazardLampVrCmdSupportAck 0;
BA_ "GenSigTimeoutMsg_IVI" SG_ 491 HuBCmHazardLampVrCmdSupportAck 0;
BA_ "GenSigTimeoutTime_IVI" SG_ 491 HuBCmHazardLampVrCmdSupportAck 0;
BA_ "GenSigTimeoutTime_HU_Mid_X451" SG_ 491 HuBCmDRLVrCmdSupportAck 0;
BA_ "GenSigTimeoutTime_HU_High_X451" SG_ 491 HuBCmDRLVrCmdSupportAck 0;
BA_ "GenSigTimeoutTime_HU_B" SG_ 491 HuBCmDRLVrCmdSupportAck 0;
BA_ "GenSigTimeoutTime_HU_A" SG_ 491 HuBCmDRLVrCmdSupportAck 0;
BA_ "GenSigTimeoutMsg_HU_Mid_X451" SG_ 491 HuBCmDRLVrCmdSupportAck 0;
BA_ "GenSigTimeoutMsg_HU_High_X451" SG_ 491 HuBCmDRLVrCmdSupportAck 0;
BA_ "GenSigTimeoutMsg_HU_B" SG_ 491 HuBCmDRLVrCmdSupportAck 0;
BA_ "GenSigTimeoutMsg_HU_A" SG_ 491 HuBCmDRLVrCmdSupportAck 0;
BA_ "GenSigSendType" SG_ 491 HuBCmDRLVrCmdSupportAck 2;
BA_ "GenSigTimeoutMsg_HU_High_X445" SG_ 491 HuBCmDRLVrCmdSupportAck 0;
BA_ "GenSigTimeoutMsg_HU_Mid_X445" SG_ 491 HuBCmDRLVrCmdSupportAck 0;
BA_ "GenSigTimeoutTime_HU_High_X445" SG_ 491 HuBCmDRLVrCmdSupportAck 0;
BA_ "GenSigTimeoutTime_HU_Mid_X445" SG_ 491 HuBCmDRLVrCmdSupportAck 0;
BA_ "GenSigTimeoutMsg_IVI" SG_ 491 HuBCmDRLVrCmdSupportAck 0;
BA_ "GenSigTimeoutTime_IVI" SG_ 491 HuBCmDRLVrCmdSupportAck 0;
BA_ "GenSigTimeoutTime_HU_Mid_X451" SG_ 491 HuBCmAmbientLightVrCmdSupportAck 0;
BA_ "GenSigTimeoutTime_HU_High_X451" SG_ 491 HuBCmAmbientLightVrCmdSupportAck 0;
BA_ "GenSigTimeoutTime_HU_B" SG_ 491 HuBCmAmbientLightVrCmdSupportAck 0;
BA_ "GenSigTimeoutTime_HU_A" SG_ 491 HuBCmAmbientLightVrCmdSupportAck 0;
BA_ "GenSigTimeoutMsg_HU_Mid_X451" SG_ 491 HuBCmAmbientLightVrCmdSupportAck 0;
BA_ "GenSigTimeoutMsg_HU_High_X451" SG_ 491 HuBCmAmbientLightVrCmdSupportAck 0;
BA_ "GenSigTimeoutMsg_HU_B" SG_ 491 HuBCmAmbientLightVrCmdSupportAck 0;
BA_ "GenSigTimeoutMsg_HU_A" SG_ 491 HuBCmAmbientLightVrCmdSupportAck 0;
BA_ "GenSigSendType" SG_ 491 HuBCmAmbientLightVrCmdSupportAck 2;
BA_ "GenSigTimeoutMsg_HU_High_X445" SG_ 491 HuBCmAmbientLightVrCmdSupportAck 0;
BA_ "GenSigTimeoutMsg_HU_Mid_X445" SG_ 491 HuBCmAmbientLightVrCmdSupportAck 0;
BA_ "GenSigTimeoutTime_HU_High_X445" SG_ 491 HuBCmAmbientLightVrCmdSupportAck 0;
BA_ "GenSigTimeoutTime_HU_Mid_X445" SG_ 491 HuBCmAmbientLightVrCmdSupportAck 0;
BA_ "GenSigTimeoutMsg_IVI" SG_ 491 HuBCmAmbientLightVrCmdSupportAck 0;
BA_ "GenSigTimeoutTime_IVI" SG_ 491 HuBCmAmbientLightVrCmdSupportAck 0;
BA_ "GenSigTimeoutTime_HU_Mid_X451" SG_ 491 HuBCmSunShadeVrCmdSupportAck 0;
BA_ "GenSigTimeoutTime_HU_High_X451" SG_ 491 HuBCmSunShadeVrCmdSupportAck 0;
BA_ "GenSigTimeoutTime_HU_B" SG_ 491 HuBCmSunShadeVrCmdSupportAck 0;
BA_ "GenSigTimeoutTime_HU_A" SG_ 491 HuBCmSunShadeVrCmdSupportAck 0;
BA_ "GenSigTimeoutMsg_HU_Mid_X451" SG_ 491 HuBCmSunShadeVrCmdSupportAck 0;
BA_ "GenSigTimeoutMsg_HU_High_X451" SG_ 491 HuBCmSunShadeVrCmdSupportAck 0;
BA_ "GenSigTimeoutMsg_HU_B" SG_ 491 HuBCmSunShadeVrCmdSupportAck 0;
BA_ "GenSigTimeoutMsg_HU_A" SG_ 491 HuBCmSunShadeVrCmdSupportAck 0;
BA_ "GenSigSendType" SG_ 491 HuBCmSunShadeVrCmdSupportAck 2;
BA_ "GenSigTimeoutMsg_HU_High_X445" SG_ 491 HuBCmSunShadeVrCmdSupportAck 0;
BA_ "GenSigTimeoutMsg_HU_Mid_X445" SG_ 491 HuBCmSunShadeVrCmdSupportAck 0;
BA_ "GenSigTimeoutTime_HU_High_X445" SG_ 491 HuBCmSunShadeVrCmdSupportAck 0;
BA_ "GenSigTimeoutTime_HU_Mid_X445" SG_ 491 HuBCmSunShadeVrCmdSupportAck 0;
BA_ "GenSigTimeoutMsg_IVI" SG_ 491 HuBCmSunShadeVrCmdSupportAck 0;
BA_ "GenSigTimeoutTime_IVI" SG_ 491 HuBCmSunShadeVrCmdSupportAck 0;
BA_ "GenSigTimeoutTime_HU_Mid_X451" SG_ 491 HuBCmSunRoofVrCmdSupportAck 0;
BA_ "GenSigTimeoutTime_HU_High_X451" SG_ 491 HuBCmSunRoofVrCmdSupportAck 0;
BA_ "GenSigTimeoutTime_HU_B" SG_ 491 HuBCmSunRoofVrCmdSupportAck 0;
BA_ "GenSigTimeoutTime_HU_A" SG_ 491 HuBCmSunRoofVrCmdSupportAck 0;
BA_ "GenSigTimeoutMsg_HU_Mid_X451" SG_ 491 HuBCmSunRoofVrCmdSupportAck 0;
BA_ "GenSigTimeoutMsg_HU_High_X451" SG_ 491 HuBCmSunRoofVrCmdSupportAck 0;
BA_ "GenSigTimeoutMsg_HU_B" SG_ 491 HuBCmSunRoofVrCmdSupportAck 0;
BA_ "GenSigTimeoutMsg_HU_A" SG_ 491 HuBCmSunRoofVrCmdSupportAck 0;
BA_ "GenSigSendType" SG_ 491 HuBCmSunRoofVrCmdSupportAck 2;
BA_ "GenSigTimeoutMsg_HU_High_X445" SG_ 491 HuBCmSunRoofVrCmdSupportAck 0;
BA_ "GenSigTimeoutMsg_HU_Mid_X445" SG_ 491 HuBCmSunRoofVrCmdSupportAck 0;
BA_ "GenSigTimeoutTime_HU_High_X445" SG_ 491 HuBCmSunRoofVrCmdSupportAck 0;
BA_ "GenSigTimeoutTime_HU_Mid_X445" SG_ 491 HuBCmSunRoofVrCmdSupportAck 0;
BA_ "GenSigTimeoutMsg_IVI" SG_ 491 HuBCmSunRoofVrCmdSupportAck 0;
BA_ "GenSigTimeoutTime_IVI" SG_ 491 HuBCmSunRoofVrCmdSupportAck 0;
VAL_ 524 RcwOnOffConfigState 3 "Reserved" 2 "Don't Care" 1 "ON" 0 "OFF" ;
VAL_ 524 BsdOnOffConfigState 3 "Reserved" 2 "Don't Care" 1 "ON" 0 "OFF" ;
VAL_ 524 DoaOnOffConfigState 3 "Reserved" 2 "Don't Care" 1 "ON" 0 "OFF" ;
VAL_ 524 RctaOnOffConfigState 3 "Reserved" 2 "Don't Care" 1 "ON" 0 "OFF" ;
VAL_ 593 RLRadarPresence 1 "Reserved" 0 "RLRadar Present" ;
VAL_ 593 RctaStates 7 "Reserved" 6 "System minor failure" 5 "Reserved" 4 "System Blockage" 3 "System Failure" 2 "System Active" 1 "System Passive" 0 "System is Off" ;
VAL_ 593 RctaOnOffState 3 "Reserved" 2 "Not Present" 1 "ON" 0 "OFF" ;
VAL_ 593 RctaIndRight 3 "Reserved" 2 "Error Indicator" 1 "Warning On" 0 "Warning is Off" ;
VAL_ 593 RctaIndLeft 3 "Reserved" 2 "Error Indicator" 1 "Warning On" 0 "Warning is Off" ;
VAL_ 593 RcwOnOffState 3 "Reserved" 2 "Not Present" 1 "ON" 0 "OFF" ;
VAL_ 593 BsdSoundRight 1 "Speaker ON" 0 "Speaker OFF" ;
VAL_ 593 BsdSoundLeft 1 "Speaker ON" 0 "Speaker OFF" ;
VAL_ 593 BsdOnOffState 3 "Reserved" 2 "Not Present" 1 "ON" 0 "OFF" ;
VAL_ 593 DoaWarnRight 3 "Reserved" 2 "DOA Right Warning Blink" 1 "DOA Right Warning ON " 0 "OFF" ;
VAL_ 593 DoaWarnLeft 3 "Reserved" 2 "DOA Left Warning Blink" 1 "DOA Left Warning ON " 0 "OFF" ;
VAL_ 593 DoaStates 3 "Reserved" 2 "System Not Supported" 1 "System On" 0 "System Off" ;
VAL_ 593 DoaOnOffState 3 "Reserved" 2 "Not Present" 1 "ON" 0 "OFF" ;
VAL_ 468 HuBcmOrvmTiltReversePos 1 "ORVM Tilt in Reverse function user req ON" 0 "ORVM Tilt in Reverse function user req OFF" ;
VAL_ 468 PotSwRkeOnOffReq 3 "Reserve" 2 "Enable POT by RKE switch User Req" 1 "Disable POT by RKE switch User Req" 0 "No Action Required" ;
VAL_ 468 PotHeightAdjReq 7 "Description for the value '0x7'" 6 "100% open (Default =  Fully Open Soft Stop)" 5 "90% open" 4 "80% open" 3 "70% open" 2 "60% open" 1 "50% open" 0 "No User Height Set Req" ;
VAL_ 468 PotGestOnOffReq 3 "Reserve" 2 "Enable POT by Gesture User Req" 1 "Disable POT by Gesture User Req" 0 "No Action Required" ;
VAL_ 468 PotBuzzOnOffReq 3 "Reserve" 2 "POT buzzer function ON" 1 "POT buzzer function OFF" 0 "No Action Required" ;
VAL_ 468 RcwReqType 3 "Don't Care" 2 "Settings Update" 1 "Config Query" 0 "Config Ack" ;
VAL_ 468 RcwOnOffStateReq 3 "Reserved" 2 "Reserved" 1 "ON" 0 "OFF" ;
VAL_ 468 RcwOnOffStateAck 3 "Reserved" 2 "Reserved" 1 "ON" 0 "OFF" ;
VAL_ 468 RctaReqType 3 "Don't Care" 2 "Settings Update" 1 "Config Query" 0 "Config Ack" ;
VAL_ 468 RctaOnOffStateReq 3 "Reserved" 2 "Reserved" 1 "ON" 0 "OFF" ;
VAL_ 468 RctaOnOffStateAck 3 "Reserved" 2 "Reserved" 1 "ON" 0 "OFF" ;
VAL_ 468 DoaReqType 3 "Don't Care" 2 "Settings Update" 1 "Config Query" 0 "Config Ack" ;
VAL_ 468 DoaOnOffStateReq 3 "Reserved" 2 "Reserved" 1 "ON" 0 "OFF" ;
VAL_ 468 DoaOnOffStateAck 3 "Reserved" 2 "Reserved" 1 "ON" 0 "OFF" ;
VAL_ 468 BsdReqType 3 "Don't Care" 2 "Settings Update" 1 "Config Query" 0 "Config Ack" ;
VAL_ 468 BsdOnOffStateReq 3 "Reserved" 2 "Reserved" 1 "ON" 0 "OFF" ;
VAL_ 468 BsdOnOffStateAck 3 "Reserved" 2 "Reserved" 1 "ON" 0 "OFF" ;
VAL_ 468 FcwAebWarnSetStateReq 7 "Reserved" 6 "Reserved" 5 "Reserved" 4 "Reserved" 3 "Early" 2 "Normal" 1 "Late" 0 "Not Applied" ;
VAL_ 468 FcwAebWarnSetStateAck 7 "Reserved" 6 "Reserved" 5 "Reserved" 4 "Reserved" 3 "Early" 2 "Normal" 1 "Late" 0 "Not Applied" ;
VAL_ 468 FcwAebReqType 3 "Don't Care" 2 "Settings Update" 1 "Config Query" 0 "Config Ack" ;
VAL_ 468 FcwAebOnOffStateReq 3 "Reserved" 2 "ON(FCW/AEB)" 1 "ON(FCW)" 0 "OFF" ;
VAL_ 468 FcwAebOnOffStateAck 3 "Reserved" 2 "ON(FCW/AEB)" 1 "ON(FCW)" 0 "OFF" ;
VAL_ 468 TsrReqType 3 "Don't Care" 2 "Settings Update" 1 "Config Query" 0 "Config Ack" ;
VAL_ 468 TsrOnOffStateReq 3 "Reserved" 2 "Reserved" 1 "ON" 0 "OFF" ;
VAL_ 468 TsrOnOffStateAck 3 "Reserved" 2 "Reserved" 1 "ON" 0 "OFF" ;
VAL_ 468 LdwOnOffStateReq 3 "Reserved" 2 "LDW & LKA" 1 "LDW" 0 "OFF" ;
VAL_ 468 LdwReqType 3 "Don't Care" 2 "Settings Update" 1 "Config Query" 0 "Config Ack" ;
VAL_ 468 LdwOnOffStateAck 3 "Reserved" 2 "LDW & LKA" 1 "LDW" 0 "OFF" ;
VAL_ 468 HbaOnOffStateReq 3 "Reserved" 2 "Reserved" 1 "ON" 0 "OFF" ;
VAL_ 468 HbaReqType 3 "Don't Care" 2 "Settings Update" 1 "Config Query" 0 "Config Ack" ;
VAL_ 468 HbaOnOffStateAck 3 "Reserved" 2 "Reserved" 1 "ON" 0 "OFF" ;
VAL_ 471 LdwWarningSettingConfigState 3 "Reserved		

" 2 "Haptic + Audio		

" 1 "Audio only		

" 0 "Haptic Only		

" ;
VAL_ 471 LdwHapticWarningConfigState 7 "Reserved" 6 "Reserved" 5 "Reserved" 4 "Reserved" 3 "High" 2 "Medium" 1 "Low" 0 "OFF" ;
VAL_ 471 LcsSignalApplicability 1 "Valid		

" 0 "Don't Care		

" ;
VAL_ 471 LcsOnOffConfigState 3 "Reserved		

" 2 "Reserved		

" 1 "ON		

" 0 "OFF		

" ;
VAL_ 471 AsaSignalApplicability 1 "Valid		

" 0 "Don't Care		

" ;
VAL_ 471 AsaOnOffConfigState 3 "Reserved		

" 2 "Reserved		

" 1 "ON		

" 0 "OFF		

" ;
VAL_ 471 OvrSpdLmtThrshldConfigState 3 "10 kpmh		

" 2 "5 kmph		

" 1 "3 kpmh		

" 0 "0 kmph		

" ;
VAL_ 471 OvrSpdLmtWarnConfigState 3 "Reserved		

" 2 "Visual and Audio Warning		

" 1 "Visual Warning		

" 0 "OFF		

" ;
VAL_ 471 IsaOnOffConfigState 3 "Reserved		

" 2 "ON (Intelligent Mode)		

" 1 "ON (Manual Mode)		

" 0 "OFF		

" ;
VAL_ 471 TsrSignalApplicability 1 "Valid" 0 "Don't Care" ;
VAL_ 471 FcwAebSignalApplicability 1 "Valid" 0 "Don't Care" ;
VAL_ 471 LdwSignalApplicability 1 "Valid" 0 "Don't Care" ;
VAL_ 471 HbaSignalApplicability 1 "Valid" 0 "Don't Care" ;
VAL_ 471 FcwAebOnOffConfigStateValidity 1 "Update attempt above threshold speed" 0 "Update Allowed" ;
VAL_ 471 FcwAebWarnSetConfigStateValidity 1 "Update attempt above threshold speed" 0 "Update Allowed" ;
VAL_ 471 FcwAebWarnSetConfigState 7 "Reserved" 6 "Reserved" 5 "Reserved" 4 "Reserved" 3 "Early" 2 "Normal" 1 "Late" 0 "Not Applied" ;
VAL_ 471 TsrOnOffConfigState 3 "Reserved" 2 "Reserved" 1 "ON" 0 "OFF" ;
VAL_ 471 LdwOnOffConfigState 3 "Reserved" 2 "LDW & LKA" 1 "LDW" 0 "OFF" ;
VAL_ 471 HbaOnOffConfigState 3 "Reserved" 2 "Reserved" 1 "ON" 0 "OFF" ;
VAL_ 471 FcwAebOnOffConfigState 3 "Reserved" 2 "ON(FCW/AEB)" 1 "ON(FCW)" 0 "OFF" ;
VAL_ 592 LdwHapticWarningPresence 1 "Present" 0 "Not Present" ;
VAL_ 592 LkaPresence 1 "Present" 0 "Not Present" ;
VAL_ 592 TsrOnOffState 3 "TSR & OverSpeedLimit" 2 "Not Present" 1 "ON" 0 "OFF" ;
VAL_ 592 HbaOnOffState 3 "Reserved" 2 "Not Present" 1 "ON" 0 "OFF" ;
VAL_ 592 LdwOnOffState 3 "Not Present" 2 "LDW & LKA" 1 "LDW" 0 "OFF" ;
VAL_ 592 FcmPresence 1 "Reserved" 0 "FCM Present" ;
VAL_ 384 FcwAebOnOffState 3 "ON (FCW)" 2 "Not Present" 1 "ON(FCW/AEB)" 0 "Off" ;
VAL_ 473 LdwWarningSettingReq 3 "Reserved		

" 2 "Haptic + Audio		

" 1 "Audio only		

" 0 "Haptic Only		

" ;
VAL_ 473 LdwWarningSettingConfigAck 3 "Reserved		

" 2 "Haptic + Audio		

" 1 "Audio only		

" 0 "Haptic Only		

" ;
VAL_ 473 LdwHapticWarningStateReq 7 "Reserved" 6 "Reserved" 5 "Reserved" 4 "Reserved" 3 "High" 2 "Medium" 1 "Low" 0 "OFF" ;
VAL_ 473 LdwHapticWarningConfigAck 7 "Reserved" 6 "Reserved" 5 "Reserved" 4 "Reserved" 3 "High" 2 "Medium" 1 "Low" 0 "OFF" ;
VAL_ 473 LcsOnOffStateReq 3 "Reserved		

" 2 "Reserved		

" 1 "ON		

" 0 "OFF		

" ;
VAL_ 473 LcsOnOffStateAck 3 "Reserved	" 2 "Reserved		

" 1 "ON		

" 0 "OFF		

" ;
VAL_ 473 LcsReqType 3 "Don't Care		

" 2 "Settings Update		

" 1 "Config Query		

" 0 "Config Ack		

" ;
VAL_ 473 HuPepsMrrProximityUnfoldSelReq 3 "Reserve" 2 "ORVM Proximity Auto Fold / Unfold feature On" 1 "ORVM Proximity Auto Fold / Unfold feature OFF" 0 "No Action Required" ;
VAL_ 473 HuVCuReqType 3 "Factory default" 2 "Charge limit setting update for DC" 1 "Charge limit setting update for AC" 0 "Don't care" ;
VAL_ 473 HuCplSclTimerSettingUpdate 3 "Reserved" 2 "SCL Timer is 60 sec" 1 "SCL Timer is 30 sec" 0 "SCL Timer is 10 sec" ;
VAL_ 473 HuCplSclOnOffSettingUpdate 1 "SCL is ON" 0 "SCL is OFF" ;
VAL_ 473 HuCplReqType 3 "Reserved" 2 "Factory default" 1 "SCL user setting update" 0 "Don't care" ;
VAL_ 473 AsaOnOffStateReq 3 "Reserved		

" 2 "Reserved		

" 1 "ON		

" 0 "OFF		

" ;
VAL_ 473 AsaOnOffStateAck 3 "Reserved		

" 2 "Reserved		

" 1 "ON		

" 0 "OFF		

" ;
VAL_ 473 AsaReqType 3 "Don't Care		

" 2 "Settings Update		

" 1 "Config Query		

" 0 "Config Ack		

" ;
VAL_ 473 OvrSpdLmtThrshldStateReq 3 "10 kpmh		

" 2 "5 kmph		

" 1 "3 kpmh		

" 0 "0 kmph		

" ;
VAL_ 473 OvrSpdLmtThrshldStateAck 3 "10 kpmh		

" 2 "5 kmph		

" 1 "3 kpmh		

" 0 "0 kmph		

" ;
VAL_ 473 OvrSpdLmtWarnStateReq 3 "Reserved" 2 "Visual and Audio Warning" 1 "Visual Warning" 0 "OFF" ;
VAL_ 473 OvrSpdLmtWarnStateAck 3 "Reserved		

" 2 "Visual and Audio Warning		

" 1 "Visual Warning		

" 0 "OFF		

" ;
VAL_ 473 IsaOnOffStateReq 3 "Reserved		

" 2 "ON (Intelligent Mode)		

" 1 "ON (Manual Mode)		

" 0 "OFF		

" ;
VAL_ 473 IsaOnOffStateAck 3 "Reserved		

" 2 "ON (Intelligent Mode)		

" 1 "ON (Manual Mode)		

" 0 "OFF		

" ;
VAL_ 473 HuBCmMrrAutoUnfoldSelReq 3 "Reserve" 2 "ORVM Auto Unfold feature ON" 1 "ORVM Auto Unfold feature OFF" 0 "No Action Required" ;
VAL_ 473 IviSwcEvent 15 "Reserved" 14 "Reserved" 13 "Short to ground" 12 "Short to BAT" 11 "Open" 10 "Key stuck" 9 "Push To Talk (PTT)" 8 "Phone Reject" 7 "Volume -" 6 "Mute" 5 "Volume +" 4 "Phone Accept" 3 "SRC" 2 "Seek Up" 1 "Seek Down" 0 "No switch pressed" ;
VAL_ 436 BcmHuOrvmTiltReversePosAck 1 "ORVM tilt in Reverse function Acknowledgement Successful" 0 "ORVM tilt in Reverse function Acknowledgement Fail" ;
VAL_ 436 BcmHuMrrAutoUnfoldSelAck 3 "Reserve" 2 "ORVM Auto Unfold feature ON Successful" 1 "ORVM Auto Unfold feature OFF Successful" 0 "No Action Required" ;
VAL_ 436 PotSwRkeOnOffReqAck 3 "Reserve" 2 "Enable POT by RKE sw User Sel. Successful" 1 "Disable POT by RKE sw User Sel. Successful" 0 "No Action Required" ;
VAL_ 436 PotGestOnOffReqAck 3 "Reserve" 2 "Enable POT by Gesture User Sel. Successful" 1 "Disable POT by Gesture User Sel. Successful" 0 "No Action Required" ;
VAL_ 436 PotBuzzOnOffReqAck 3 "Reserve" 2 "POT buzzer function ON Successful" 1 "POT buzzer function OFF Successful" 0 "No Action Required" ;
VAL_ 436 PotHeightAdjAck 3 "Reserve" 2 "POT User height Selection Successful" 1 "POT User height Selection NOT Successful" 0 "No Action Required" ;
VAL_ 436 BCmHuGotoEntryExitPosAck 3 "Reserved" 2 "Action not required" 1 "Easy Entry Exit function ON Successful" 0 "Easy Entry Exit function OFF Successful" ;
VAL_ 436 BCMRemotePrecheck 3 "Reserved" 2 "BCM Remote AC & Engine Pre-condition check failed." 1 "BCM Remote AC & Engine Pre-condition check passed." 0 "Don't Care" ;
VAL_ 525 PepsHuMrrProximityUnfoldSelAck 3 "Reserve" 2 "ORVM Proximity Auto Fold/Unfold settings Failure" 1 "ORVM Proximity Auto Fold/Unfold settings Successful" 0 "No Action Required" ;
VAL_ 525 PEPSRemoteCheck 3 "Reserved" 2 "Remote check not successful" 1 "Remote check successful" 0 "Default state / Remote command not requested" ;
VAL_ 525 FotaIgnOnHoldStateAck 3 "Reserved" 2 "Signal received and Ignition ON Held" 1 "Signal not received or Ignition not held" 0 "No Action required" ;
VAL_ 496 FotaIgnOnHoldState 3 "Reserved" 2 "Ignition to be held at ON state" 1 "Ignition not to be held at ON state" 0 "No Action required" ;
VAL_ 584 BatteryCoolingSolValveState 3 "Reserved" 2 "Battery Cooling SV is ON" 1 "Reserved" 0 "Battery Cooling SV is OFF" ;
VAL_ 728 CCmHuDustConcentrationStatus 3 "Signal Not Available" 2 "Implausible/Error" 1 "Initialisation" 0 "Plausible" ;
VAL_ 728 CCmHuAqiLevel 7 "Reserved" 6 "Reserved" 5 "Severe" 4 "Very Poor" 3 "Poor" 2 "Moderate" 1 "Satisfactory" 0 "Good" ;
VAL_ 728 CCmHuDominantPollutantValue 15 "Reserved" 14 "Reserved" 13 "Reserved" 12 "Reserved" 11 "Reserved" 10 "Reserved" 9 "Reserved" 8 "Reserved" 7 "Reserved" 6 "Reserved" 5 "Reserved" 4 "NH3" 3 "CO" 2 "NOX" 1 "PM2.5" 0 "SNA(Signal not available)" ;
VAL_ 728 CCmHuAqiValueStatus 3 "Signal Not Available" 2 "Implausible/Error" 1 "Initialisation" 0 "Plausible" ;
VAL_ 728 CCmHuAqiAutolearning 1 "Feature present" 0 "Feature not present" ;
VAL_ 736 VehicleMobilizationStateStatus 3 "Signal  Not Available" 2 "Signal is Implausible" 1 "Reserved for future use" 0 "Plausible-Information is correct" ;
VAL_ 736 VehicleMobilizationState 3 "Reserved for future use" 2 "Immobilised by TCU" 1 "Mobilised by TCU" 0 "Reserved for future use" ;
VAL_ 467 HuBCmGotoEntryExitPos 3 "Reserved" 2 "Action not required" 1 "Easy Entry Exit function ON" 0 "Easy Entry Exit function OFF" ;
VAL_ 583 HvBattDischargingStatus_VCAN 3 "Signal Not Available" 2 "Signal is implausible" 1 "Reserved for Future Use" 0 "Signal is plausible" ;
VAL_ 583 HvBattDischargingState_VCAN 7 "Reserved for Future Use" 6 "Reserved for Future Use" 5 "Reserved for Future Use" 4 "Charger Connection lamp Red colour Blink" 3 "Charger Connection lamp Red colour On" 2 "Charger Connection lamp Amber colour Blink" 1 "Charger Connection lamp Amber colour On" 0 "Charger Connection lamp is OFF" ;
VAL_ 583 HvBattDischargelimitstatus_VCAN 3 "Reserved for Future Use" 2 "Signal is implausible" 1 "Reserved for Future Use" 0 "Signal is plausible" ;
VAL_ 583 HvBattDischargelimit_VCAN 3 "Low SOC, V2X deactivated" 2 "Current SOC less than Set limit" 1 "HV Battery discharged as per limit set" 0 "HV Battery Not discharged as per limit set" ;
VAL_ 583 HvBattFullChargeStatus_new_VCAN 4 "Reserved" 2 "Signal is implausible" 1 "Reserved" 0 "Signal is plausible" ;
VAL_ 583 HvBattFullCharge_new_VCAN 3 "Reserved for Future use" 2 "HV battery Set limit reached" 1 "HV Battery  fully charged" 0 "HV Battery Not fully charged" ;
VAL_ 583 CruiseSwitchStateVCUStatus 3 "Signal not available" 2 "Value is implausible " 1 "Reserved for future use" 0 "Signal is correct" ;
VAL_ 583 CruiseSwitchStateVCU 3 "Invalid Key Pressed" 2 "Set / Cruise Spd - Key pressed" 1 "Resume / Cruise Spd+ Key pressed" 0 "No Key ( Resume/Cruise Speed+  && Set/Cruise Speed - ) pressed" ;
VAL_ 583 VcuModeSelectionChangeTxt 3 "Signal not available" 2 "Mode Selection in process" 1 "Mode Selections not possible" 0 "Mode Selections possible" ;
VAL_ 583 ModeForDisplayVCUStatus 3 "Signal Not Available" 2 "Information given is implausible due to a detected failure " 1 "Reserved" 0 "Information given correct and according to specification" ;
VAL_ 583 ModeForDisplayVCU 7 "Information Initialization in progress" 6 "Reserved" 5 "Reserved" 4 "Reserved" 3 "Reserved" 2 "Sport" 1 "Eco" 0 "City" ;
VAL_ 583 ModeSelectionSwStateVCUStatus 3 "Reserved" 2 "Information given is implausible due to a detected failure " 1 "Reserved" 0 "Information given correct and according to specification" ;
VAL_ 583 ModeSelectionSwStateVCU 7 "Reserved" 6 "Reserved" 5 "Reserved" 4 "Reserved" 3 "Reserved" 2 "Sport" 1 "Eco" 0 "City" ;
VAL_ 583 VcuRegenSelectionChangeTxt 3 "Regen Level Min Limit Reached" 2 "Regen Level Max Limit Reached" 1 "Regen Level Selections not possible" 0 "Regen Level Selections possible" ;
VAL_ 583 RegenForDisplayVCUStatus 3 "Signal Not Available" 2 "Information given is implausible due to a detected failure " 1 "Reserved" 0 "Information given correct and according to specification" ;
VAL_ 583 RegenForDisplayVCU 7 "Information Initialization in progress" 6 "Reserved" 5 "Reserved" 4 "Reserved" 3 "Level 3" 2 "Level 2" 1 "Level 1" 0 "Level 0" ;
VAL_ 583 VcuCruiseSelectionChangeTxt 8 "Min Speed Limit Reached" 7 "Max Speed Limit Reached" 6 "Cruise Selections not possible" 5 "Cruise Control Overide" 4 "Cruise Cancelled" 3 "Cruise Resumed" 2 "Cruise Activated" 1 "Cruise ON" 0 "Cruise OFF" ;
VAL_ 583 DesiredCruiseSpeedStatus 3 "Signal Not available" 2 "Information given  is implausible" 1 "Reserved" 0 "Information given i correct and according to specification" ;
VAL_ 583 VCuCruiseStateStatus 3 "Signal Not Available" 2 "Information given is implausible due to a detected failure " 1 "Reserved" 0 "Information given correct and according to specification" ;
VAL_ 583 VCuCruiseState 7 "Information Initialization in progress" 6 "Reserved" 5 "Reserved" 4 "Reserved" 3 "Reserved" 2 "Cruise is enabled and not active" 1 "Cruise is enabled and active" 0 "Cruise is disabled" ;
VAL_ 583 HvBattFullChargeStatus_VCAN 4 "Reserved" 2 "Information given is implausible due to a detected failure " 1 "Reserved" 0 "Information given correct and according to specification" ;
VAL_ 583 HvBattFullCharge_VCAN 1 "HV Battery  fully charged" 0 "HV Battery Not fully charged" ;
VAL_ 741 RemoteAcPvTempSetStatus 3 "Signal Not Available" 2 "Signal is Implausible" 1 "Don’t Care" 0 "Plausible - Information given is correct and according to specification" ;
VAL_ 741 RemoteAcPvTempSet 31 "HI" 30 "Reserved" 29 "30" 28 "29.5" 27 "29" 26 "28.5" 25 "28" 24 "27.5" 23 "27" 22 "26.5" 21 "26" 20 "25.5" 19 "25" 18 "24.5" 17 "24" 16 "23.5" 15 "23" 14 "22.5" 13 "22" 12 "21.5" 11 "21" 10 "20.5" 9 "20" 8 "19.5" 7 "19" 6 "18.5" 5 "18" 4 "LO" 3 "Reserved" 2 "Reserved" 1 "Reserved" 0 "Reserved" ;
VAL_ 741 RemoteEngAcCmdStatus 3 "Signal not available" 2 "Signal is implausible" 1 "Reserved for future use." 0 "Signal is correct" ;
VAL_ 741 RemoteEngAcCmd 3 "Remote AC Start is Active" 2 "Default state with Normal Running mode ON" 1 "Remote Engine Start is Active" 0 "Remote AC & Engine Signal is not Active" ;
VAL_ 741 FotaUpdateState 15 "IgnitionRecycle" 14 "Reserved" 13 "Reserved" 12 "NoActionRequired" 11 "UpdateAborted" 10 "RollbackFailed" 9 "RollbackSuccessful" 8 "RollbackInProgress (InstallationFailed)" 7 "ReInstallationInProgress" 6 "InstallationSuccessful" 5 "InstallationInProgress" 4 "UserReConfirm" 3 "InstallPreConditionCheck " 2 "WaitingUserConfirm" 1 "ReadyToInstall" 0 "Default" ;
VAL_ 673 WirelessChargerPresence 1 "Present" 0 "Not Present" ;
VAL_ 673 WcdutycycleStatus 3 "Signal Not Avilable" 2 "Wcdutycycle signal value is implausible" 1 "Reserved for Future" 0 "Wcdutycycle signal value is plausible" ;
VAL_ 491 HuBCmWindowWindingHmiCmdSupportA 1 "Supported" 0 "Not Supported" ;
VAL_ 491 HuBCmTyreTempVrCmdSupportAck 1 "Supported" 0 "Not Supported" ;
VAL_ 491 HuBCmTyreTempHmiCmdSupportAck 1 "Supported" 0 "Not Supported" ;
VAL_ 491 HuBCmTyrePressureVrCmdSupportAck 1 "Supported" 0 "Not Supported" ;
VAL_ 491 HuBCmTyrePressureHmiCmdSupportAc 1 "Supported" 0 "Not Supported" ;
VAL_ 491 HuBCmSunroofTiltVrCmdSupportAck 1 "Supported" 0 "Not Supported" ;
VAL_ 491 HuBCmRoofLampVrCmdSupportAck 1 "Supported" 0 "Not Supported" ;
VAL_ 491 HuBCmRoofLampHmiCmdSupportAck 1 "Supported" 0 "Not Supported" ;
VAL_ 491 HuBCmPositionLampVrCmdSupportAck 1 "Supported" 0 "Not Supported" ;
VAL_ 491 HuBCmORVMVrCmdSupportAck 1 "Supported" 0 "Not Supported" ;
VAL_ 491 HuBCmORVMHmiCmdSupportAck 1 "Supported" 0 "Not Supported" ;
VAL_ 491 HuBCmMoodLightVrCmdSupportAck 1 "Supported" 0 "Not Supported" ;
VAL_ 491 HuBCmHazardLampVrCmdSupportAck 1 "Supported" 0 "Not Supported" ;
VAL_ 491 HuBCmDRLVrCmdSupportAck 1 "Supported" 0 "Not Supported" ;
VAL_ 491 HuBCmAmbientLightVrCmdSupportAck 1 "Supported" 0 "Not Supported" ;
VAL_ 491 HuBCmSunShadeVrCmdSupportAck 1 "Supported" 0 "Not Supported" ;
VAL_ 491 HuBCmSunRoofVrCmdSupportAck 1 "Supported" 0 "Not Supported" ;
